VERSION "HNNBNNNYNNNNNNNNNNNNNNNNNNNNNNNNNNNNNNNNNN/4/%%%/4/'%**4NNN///"

NS_ :

BS_:

BU_: AFS Airbag Allrad BAP_Tester BMS_Hybrid Bremse_MK60EC Bremse_MK70MABS Bremse_TRW_EBC450M Bremse_TRW_ESP Daempfer EPB_TRW EPB_TRW_VW411CS FLA Gateway_PQ35 Gateway_Zusatz_EGolf Getriebe_AG6 Getriebe_DQ Getriebe_DQ_Hyb Getriebe_Sele Gurtmikro_PQ35 HCA Ladegeraet_EGolf LEH_Hybrid LH_EPS_APA LH_EPS_ZF_2G LH_EPS_ZF_3G LPG_Interface_Box LWR LWS Magne_Ride Motor_Diesel Motor_EGolf Motor_Hybrid Motor_Otto PDC_PLA Quersperre_VAQ RKA_Plus SAK Waehlhebel Waehlhebel_Sele

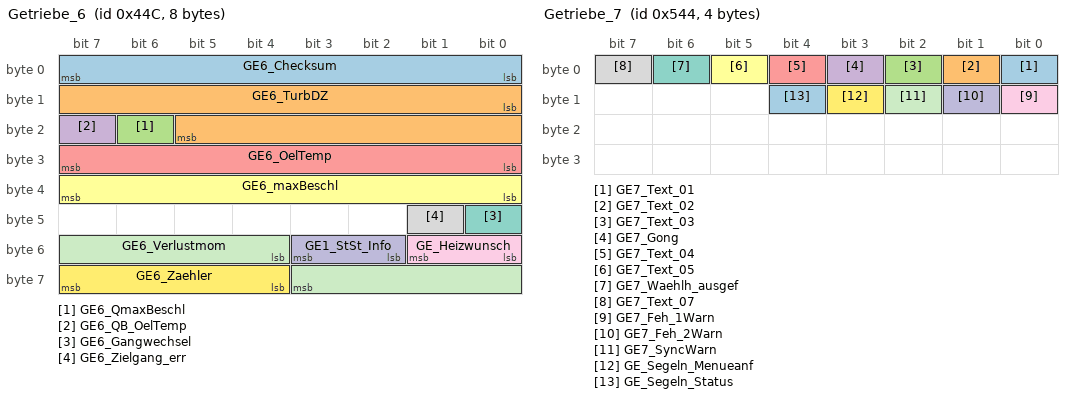
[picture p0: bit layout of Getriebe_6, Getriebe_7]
BO_ 1100 Getriebe_6: 8 Getriebe_AG6
 SG_ GE6_Checksum : 0|8@1+ (1,0) [0|255] ""  Motor_Diesel,Motor_Otto
 SG_ GE6_TurbDZ : 8|14@1+ (1,0) [0|16381] "Unit_MinutInver"  Motor_Diesel,Motor_Otto
 SG_ GE6_QmaxBeschl : 22|1@1+ (1,0) [0|1] "" Vector__XXX
 SG_ GE6_QB_OelTemp : 23|1@1+ (1,0) [0|1] ""  Motor_Diesel,Motor_Otto
 SG_ GE6_OelTemp : 24|8@1+ (1,-55) [-55|199] "Unit_DegreCelsi"  Motor_Diesel,Motor_Otto
 SG_ GE6_maxBeschl : 32|8@1+ (0.024,-2.112) [-2.112|3.984] "Unit_MeterPerSeconSquar" Vector__XXX
 SG_ GE6_Gangwechsel : 40|1@1+ (1,0) [0|1] "" Vector__XXX
 SG_ GE6_Zielgang_err : 41|1@1+ (1,0) [0|1] "" Vector__XXX
 SG_ GE_Heizwunsch : 48|2@1+ (1,0) [0|3] "" Vector__XXX
 SG_ GE1_StSt_Info : 50|2@1+ (1,0) [0|3] "" Vector__XXX
 SG_ GE6_Verlustmom : 52|8@1+ (0.39,0) [0|99.06] "Unit_PerCent" Vector__XXX
 SG_ GE6_Zaehler : 60|4@1+ (1,0) [0|15] ""  Motor_Diesel,Motor_Otto

BO_ 1348 Getriebe_7: 4 Getriebe_DQ
 SG_ GE7_Text_01 : 0|1@1+ (1,0) [0|1] ""  Gateway_PQ35
 SG_ GE7_Text_02 : 1|1@1+ (1,0) [0|1] ""  Gateway_PQ35
 SG_ GE7_Text_03 : 2|1@1+ (1,0) [0|1] ""  Gateway_PQ35
 SG_ GE7_Gong : 3|1@1+ (1,0) [0|1] ""  Gateway_PQ35
 SG_ GE7_Text_04 : 4|1@1+ (1,0) [0|1] ""  Gateway_PQ35
 SG_ GE7_Text_05 : 5|1@1+ (1,0) [0|1] ""  Gateway_PQ35
 SG_ GE7_Waehlh_ausgef : 6|1@1+ (1,0) [0|1] ""  Gateway_PQ35
 SG_ GE7_Text_07 : 7|1@1+ (1,0) [0|1] ""  Gateway_PQ35
 SG_ GE7_Feh_1Warn : 8|1@1+ (1,0) [0|1] ""  Gateway_PQ35
 SG_ GE7_Feh_2Warn : 9|1@1+ (1,0) [0|1] ""  Gateway_PQ35
 SG_ GE7_SyncWarn : 10|1@1+ (1,0) [0|1] ""  Gateway_PQ35
 SG_ GE_Segeln_Menueanf : 11|1@1+ (1,0) [0|1] ""  Gateway_PQ35
 SG_ GE_Segeln_Status : 12|1@1+ (1,0) [0|1] ""  Gateway_PQ35

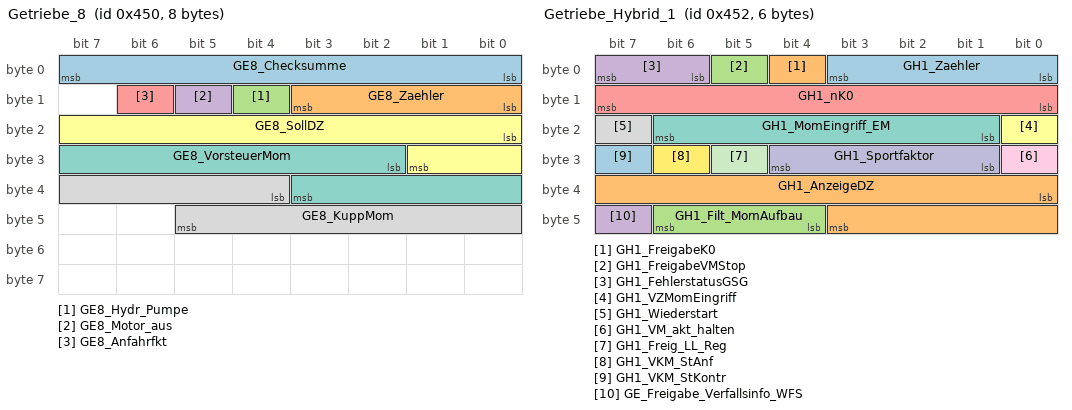
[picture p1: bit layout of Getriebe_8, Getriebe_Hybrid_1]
BO_ 1104 Getriebe_8: 8 Getriebe_Sele
 SG_ GE8_Checksumme : 0|8@1+ (1,0) [0|255] ""  Motor_Otto
 SG_ GE8_Zaehler : 8|4@1+ (1,0) [0|15] ""  Motor_Otto
 SG_ GE8_Hydr_Pumpe : 12|1@1+ (1,0) [0|1] ""  Motor_Otto
 SG_ GE8_Motor_aus : 13|1@1+ (1,0) [0|1] ""  Motor_Otto
 SG_ GE8_Anfahrfkt : 14|1@1+ (1,0) [0|1] ""  Motor_Otto
 SG_ GE8_SollDZ : 16|10@1+ (10,0) [0|10230] "Unit_MinutInver"  Motor_Otto
 SG_ GE8_VorsteuerMom : 26|10@1+ (1,0) [0|1023] "Unit_NewtoMeter"  Motor_Otto
 SG_ GE8_KuppMom : 36|10@1+ (1,0) [0|1023] "Unit_NewtoMeter"  Motor_Otto

BO_ 1106 Getriebe_Hybrid_1: 6 Getriebe_DQ_Hyb
 SG_ GH1_Zaehler : 0|4@1+ (1,0) [0|15] ""  Motor_Hybrid
 SG_ GH1_FreigabeK0 : 4|1@1+ (1,0) [0|1] ""  Motor_Hybrid
 SG_ GH1_FreigabeVMStop : 5|1@1+ (1,0) [0|1] ""  Motor_Hybrid
 SG_ GH1_FehlerstatusGSG : 6|2@1+ (1,0) [0|3] ""  Motor_Hybrid
 SG_ GH1_nK0 : 8|8@1+ (25,0) [0|6350] "Unit_MinutInver"  Motor_Hybrid
 SG_ GH1_VZMomEingriff : 16|1@1+ (1,0) [0|1] ""  LEH_Hybrid
 SG_ GH1_MomEingriff_EM : 17|6@1+ (0.5,0) [0|31.5] "Unit_NewtoMeter"  LEH_Hybrid
 SG_ GH1_Wiederstart : 23|1@1+ (1,0) [0|1] ""  Motor_Hybrid
 SG_ GH1_VM_akt_halten : 24|1@1+ (1,0) [0|1] ""  Motor_Hybrid
 SG_ GH1_Sportfaktor : 25|4@1+ (1,0) [0|15] ""  Motor_Hybrid
 SG_ GH1_Freig_LL_Reg : 29|1@1+ (1,0) [0|1] ""  Motor_Hybrid
 SG_ GH1_VKM_StAnf : 30|1@1+ (1,0) [0|1] ""  Motor_Hybrid
 SG_ GH1_VKM_StKontr : 31|1@1+ (1,0) [0|1] ""  Motor_Hybrid
 SG_ GH1_AnzeigeDZ : 32|12@1+ (3,0) [0|12282] "Unit_MinutInver"  Motor_Hybrid
 SG_ GH1_Filt_MomAufbau : 44|3@1+ (1,0) [0|7] ""  Motor_Hybrid
 SG_ GE_Freigabe_Verfallsinfo_WFS : 47|1@1+ (1,0) [0|1] "" Vector__XXX

BO_ 906 GRA_Neu: 4 Gateway_PQ35
 SG_ GRA_Checksum : 0|8@1+ (1,0) [0|255] ""  Motor_Diesel,Motor_EGolf,Motor_Hybrid,Motor_Otto
 SG_ GRA_Hauptschalt : 8|1@1+ (1,0) [0|1] ""  Motor_Diesel,Motor_EGolf,Motor_Hybrid,Motor_Otto
 SG_ GRA_Abbrechen : 9|1@1+ (1,0) [0|1] ""  Motor_Diesel,Motor_EGolf,Motor_Hybrid,Motor_Otto
 SG_ GRA_Down_kurz : 10|1@1+ (1,0) [0|1] ""  Getriebe_DQ,Getriebe_DQ_Hyb,Motor_Diesel,Motor_EGolf,Motor_Hybrid,Motor_Otto
 SG_ GRA_Up_kurz : 11|1@1+ (1,0) [0|1] ""  Getriebe_DQ,Getriebe_DQ_Hyb,Motor_Diesel,Motor_EGolf,Motor_Hybrid,Motor_Otto
 SG_ GRA_Down_lang : 12|1@1+ (1,0) [0|1] "" Vector__XXX
 SG_ GRA_Up_lang : 13|1@1+ (1,0) [0|1] "" Vector__XXX
 SG_ GRA_Fehler_Bed : 14|1@1+ (1,0) [0|1] ""  Motor_Diesel,Motor_EGolf,Motor_Hybrid,Motor_Otto
 SG_ GRA_Kodierinfo : 15|1@1+ (1,0) [0|1] ""  Motor_Diesel,Motor_EGolf,Motor_Hybrid,Motor_Otto
 SG_ GRA_Neu_Setzen : 16|1@1+ (1,0) [0|1] ""  Getriebe_DQ,Getriebe_DQ_Hyb,Motor_Diesel,Motor_EGolf,Motor_Hybrid,Motor_Otto
 SG_ GRA_Recall : 17|1@1+ (1,0) [0|1] ""  Getriebe_DQ,Getriebe_DQ_Hyb,Motor_Diesel,Motor_EGolf,Motor_Hybrid,Motor_Otto
 SG_ GRA_Sender : 18|2@1+ (1,0) [0|3] ""  Getriebe_DQ,Getriebe_DQ_Hyb,Getriebe_Sele,Motor_Diesel,Motor_EGolf,Motor_Hybrid,Motor_Otto
 SG_ GRA_Neu_Zaehler : 20|4@1+ (1,0) [0|15] ""  Motor_Diesel,Motor_EGolf,Motor_Hybrid,Motor_Otto
 SG_ GRA_Tip_Down : 24|1@1+ (1,0) [0|1] ""  Getriebe_AG6,Getriebe_DQ,Getriebe_DQ_Hyb,Getriebe_Sele
 SG_ GRA_Tip_Up : 25|1@1+ (1,0) [0|1] ""  Getriebe_AG6,Getriebe_DQ,Getriebe_DQ_Hyb,Getriebe_Sele
 SG_ GRA_Zeitluecke : 26|2@1+ (1,0) [0|3] "" Vector__XXX
 SG_ GRA_Sta_Limiter : 28|1@1+ (1,0) [0|1] "" Vector__XXX
 SG_ GRA_Typ_Hauptschalt : 29|1@1+ (1,0) [0|1] ""  Motor_Diesel,Motor_EGolf,Motor_Hybrid,Motor_Otto
 SG_ GRA_Sportschalter : 30|1@1+ (1,0) [0|1] "" Vector__XXX
 SG_ GRA_Fehler_Tip : 31|1@1+ (1,0) [0|1] ""  Getriebe_AG6,Getriebe_DQ,Getriebe_DQ_Hyb

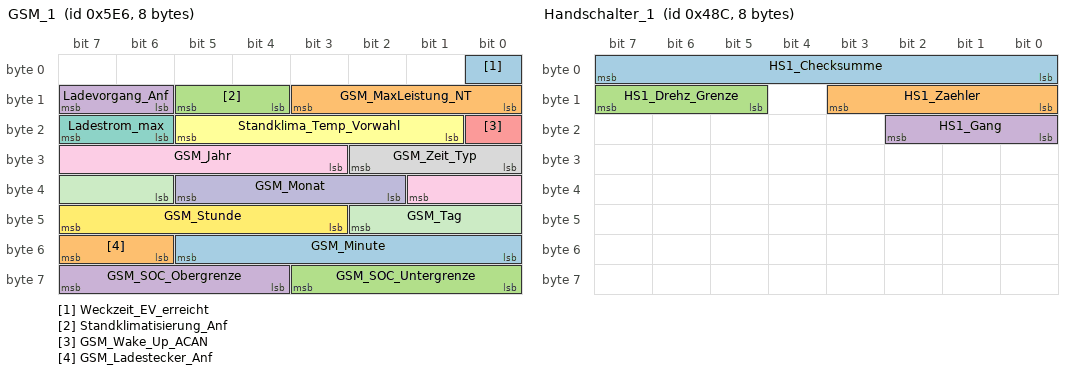
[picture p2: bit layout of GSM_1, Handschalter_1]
BO_ 1510 GSM_1: 8 Gateway_Zusatz_EGolf
 SG_ Weckzeit_EV_erreicht : 0|1@1+ (1,0) [0|1] ""  Ladegeraet_EGolf
 SG_ GSM_MaxLeistung_NT : 8|4@1+ (1,0) [1|15] "Unit_KiloWatt"  Ladegeraet_EGolf
 SG_ Standklimatisierung_Anf : 12|2@1+ (1,0) [0|3] ""  Ladegeraet_EGolf
 SG_ Ladevorgang_Anf : 14|2@1+ (1,0) [0|3] ""  Ladegeraet_EGolf
 SG_ GSM_Wake_Up_ACAN : 16|1@1+ (1,0) [0|1] "" Vector__XXX
 SG_ Standklima_Temp_Vorwahl : 17|5@1+ (1,18) [18|28] "Unit_DegreCelsi" Vector__XXX
 SG_ Ladestrom_max : 22|2@1+ (1,0) [0|3] ""  Ladegeraet_EGolf
 SG_ GSM_Zeit_Typ : 24|3@1+ (1,0) [0|7] ""  Ladegeraet_EGolf
 SG_ GSM_Jahr : 27|7@1+ (1,2000) [2000|2127] "Unit_Year"  Ladegeraet_EGolf
 SG_ GSM_Monat : 34|4@1+ (1,0) [1|12] "Unit_Month"  Ladegeraet_EGolf
 SG_ GSM_Tag : 38|5@1+ (1,0) [0|31] "Unit_Day"  Ladegeraet_EGolf
 SG_ GSM_Stunde : 43|5@1+ (1,0) [0|23] "Unit_Hours"  Ladegeraet_EGolf
 SG_ GSM_Minute : 48|6@1+ (1,0) [0|59] "Unit_Minut"  Ladegeraet_EGolf
 SG_ GSM_Ladestecker_Anf : 54|2@1+ (1,0) [0|3] ""  Ladegeraet_EGolf,Motor_EGolf
 SG_ GSM_SOC_Untergrenze : 56|4@1+ (10,0) [0|100] "Unit_PerCent"  Ladegeraet_EGolf
 SG_ GSM_SOC_Obergrenze : 60|4@1+ (10,0) [0|100] "Unit_PerCent"  Ladegeraet_EGolf

BO_ 1529 Gurtmikro_1: 1 Gurtmikro_PQ35
 SG_ GM_KD_Fehler : 0|1@1+ (1,0) [0|1] ""  Gateway_PQ35

BO_ 1164 Handschalter_1: 8 Motor_Diesel
 SG_ HS1_Checksumme : 0|8@1+ (1,0) [0|255] ""  Gateway_PQ35
 SG_ HS1_Zaehler : 8|4@1+ (1,0) [0|15] ""  Gateway_PQ35
 SG_ HS1_Drehz_Grenze : 13|3@1+ (1,0) [0|7] ""  Gateway_PQ35
 SG_ HS1_Gang : 16|3@1+ (1,0) [0|7] ""  Gateway_PQ35

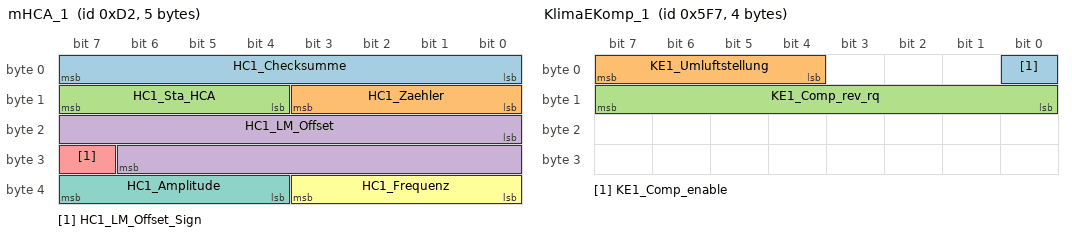
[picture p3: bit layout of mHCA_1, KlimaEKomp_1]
BO_ 210 mHCA_1: 5 Gateway_PQ35
 SG_ HC1_Checksumme : 0|8@1+ (1,0) [0|255] ""  LH_EPS_APA,LH_EPS_ZF_2G,LH_EPS_ZF_3G
 SG_ HC1_Zaehler : 8|4@1+ (1,0) [0|15] ""  LH_EPS_APA,LH_EPS_ZF_2G,LH_EPS_ZF_3G
 SG_ HC1_Sta_HCA : 12|4@1+ (1,0) [0|15] ""  Gateway_PQ35,LH_EPS_APA,LH_EPS_ZF_2G,LH_EPS_ZF_3G
 SG_ HC1_LM_Offset : 16|15@1+ (0.0003052,0) [0|10.0004884] "Unit_NewtoMeter"  Gateway_PQ35,LH_EPS_APA,LH_EPS_ZF_2G,LH_EPS_ZF_3G
 SG_ HC1_LM_Offset_Sign : 31|1@1+ (1,0) [0|1] ""  Gateway_PQ35,LH_EPS_APA,LH_EPS_ZF_2G,LH_EPS_ZF_3G
 SG_ HC1_Frequenz : 32|4@1+ (4,0) [0|60] "Unit_Hertz"  LH_EPS_APA,LH_EPS_ZF_2G,LH_EPS_ZF_3G
 SG_ HC1_Amplitude : 36|4@1+ (0.5,0) [0|7.5] "Unit_NewtoMeter"  LH_EPS_APA,LH_EPS_ZF_2G,LH_EPS_ZF_3G

BO_ 1490 mIdent: 8 Gateway_PQ35
 SG_ IDT_Mux M : 0|2@1+ (1,0) [0|2] ""  Airbag,Bremse_MK60EC,Bremse_MK70MABS,Bremse_TRW_EBC450M,Bremse_TRW_ESP,Daempfer,EPB_TRW,EPB_TRW_VW411CS,LH_EPS_APA,LH_EPS_ZF_2G,LH_EPS_ZF_3G,LWS,Magne_Ride
 SG_ IDT_Geheimnis_1 m0 : 8|8@1+ (1,0) [0|255] "" Vector__XXX
 SG_ IDT_VIN_4 m1 : 8|8@1+ (1,0) [0|255] ""  Airbag,Daempfer,LWS,Magne_Ride
 SG_ IDT_VIN_11 m2 : 8|8@1+ (1,0) [0|255] ""  Airbag,Daempfer,LWS,Magne_Ride
 SG_ IDT_Geheimnis_2 m0 : 16|8@1+ (1,0) [0|255] "" Vector__XXX
 SG_ IDT_VIN_5 m1 : 16|8@1+ (1,0) [0|255] ""  Airbag,Daempfer,LWS,Magne_Ride
 SG_ IDT_VIN_12 m2 : 16|8@1+ (1,0) [0|255] ""  Airbag,Daempfer,LWS,Magne_Ride
 SG_ IDT_Geheimnis_3 m0 : 24|8@1+ (1,0) [0|255] "" Vector__XXX
 SG_ IDT_VIN_6 m1 : 24|8@1+ (1,0) [0|255] ""  Airbag,Daempfer,LWS,Magne_Ride
 SG_ IDT_VIN_13 m2 : 24|8@1+ (1,0) [0|255] ""  Airbag,Bremse_MK60EC,Bremse_TRW_EBC450M,Bremse_TRW_ESP,Daempfer,EPB_TRW,EPB_TRW_VW411CS,LWS,Magne_Ride
 SG_ IDT_Geheimnis_4 m0 : 32|8@1+ (1,0) [0|255] "" Vector__XXX
 SG_ IDT_VIN_7 m1 : 32|8@1+ (1,0) [0|255] ""  Airbag,Bremse_MK60EC,Bremse_TRW_EBC450M,Daempfer,EPB_TRW,EPB_TRW_VW411CS,LWS,Magne_Ride
 SG_ IDT_VIN_14 m2 : 32|8@1+ (1,0) [0|255] ""  Airbag,Bremse_MK60EC,Bremse_MK70MABS,Bremse_TRW_EBC450M,Bremse_TRW_ESP,Daempfer,EPB_TRW,EPB_TRW_VW411CS,LH_EPS_APA,LH_EPS_ZF_2G,LH_EPS_ZF_3G,LWS,Magne_Ride
 SG_ IDT_VIN_1 m0 : 40|8@1+ (1,0) [0|255] ""  Airbag,Daempfer,LWS,Magne_Ride
 SG_ IDT_VIN_8 m1 : 40|8@1+ (1,0) [0|255] ""  Airbag,Bremse_MK60EC,Bremse_TRW_EBC450M,Daempfer,EPB_TRW,EPB_TRW_VW411CS,LWS,Magne_Ride
 SG_ IDT_VIN_15 m2 : 40|8@1+ (1,0) [0|255] ""  Airbag,Bremse_MK60EC,Bremse_MK70MABS,Bremse_TRW_EBC450M,Bremse_TRW_ESP,Daempfer,EPB_TRW,EPB_TRW_VW411CS,LH_EPS_APA,LH_EPS_ZF_2G,LH_EPS_ZF_3G,LWS,Magne_Ride
 SG_ IDT_VIN_2 m0 : 48|8@1+ (1,0) [0|255] ""  Airbag,Daempfer,LWS,Magne_Ride
 SG_ IDT_VIN_9 m1 : 48|8@1+ (1,0) [0|255] ""  Airbag,Daempfer,LWS,Magne_Ride
 SG_ IDT_VIN_16 m2 : 48|8@1+ (1,0) [0|255] ""  Airbag,Bremse_MK60EC,Bremse_MK70MABS,Bremse_TRW_EBC450M,Bremse_TRW_ESP,Daempfer,EPB_TRW,EPB_TRW_VW411CS,LH_EPS_APA,LH_EPS_ZF_2G,LH_EPS_ZF_3G,LWS,Magne_Ride
 SG_ IDT_VIN_3 m0 : 56|8@1+ (1,0) [0|255] ""  Airbag,Daempfer,LWS,Magne_Ride
 SG_ IDT_VIN_10 m1 : 56|8@1+ (1,0) [0|255] ""  Airbag,Daempfer,LWS,Magne_Ride
 SG_ IDT_VIN_17 m2 : 56|8@1+ (1,0) [0|255] ""  Airbag,Bremse_MK60EC,Bremse_MK70MABS,Bremse_TRW_EBC450M,Bremse_TRW_ESP,Daempfer,EPB_TRW,EPB_TRW_VW411CS,LH_EPS_APA,LH_EPS_ZF_2G,LH_EPS_ZF_3G,LWS,Magne_Ride

BO_ 1512 Klima_EV_1: 8 Gateway_Zusatz_EGolf
 SG_ KL_HV_ein : 0|1@1+ (1,0) [0|1] "" Vector__XXX
 SG_ KL_Innengeblaese : 1|1@1+ (1,0) [0|1] "" Vector__XXX
 SG_ KL_PTC_Soll : 2|8@1+ (0.5,0) [0|100] "Unit_PerCent"  BMS_Hybrid,Ladegeraet_EGolf,Motor_EGolf
 SG_ KL_Wake_Up_ACAN : 12|1@1+ (1,0) [0|1] "" Vector__XXX
 SG_ KL_HV_Anf : 13|1@1+ (1,0) [0|1] ""  Motor_EGolf
 SG_ KL_Ventil_Batterie_Anf : 14|1@1+ (1,0) [0|1] ""  Motor_EGolf
 SG_ KL_Ventil_vor_Motor_Anf : 15|1@1+ (1,0) [0|1] ""  Motor_EGolf
 SG_ PTC_Strom : 16|8@1+ (0.1,0) [0|25.4] "Unit_Amper"  Ladegeraet_EGolf,Motor_EGolf
 SG_ EKK_Strom : 24|8@1+ (0.1,0) [0|25.4] "Unit_Amper"  Ladegeraet_EGolf,Motor_EGolf
 SG_ KL_Kompr_Drehzahl_Soll : 32|8@1+ (50,0) [0|8600] "Unit_MinutInver" Vector__XXX
 SG_ EKK_Status : 40|1@1+ (1,0) [0|1] ""  Ladegeraet_EGolf,Motor_EGolf
 SG_ KL_Standklima_Status : 41|3@1+ (1,0) [0|7] ""  Ladegeraet_EGolf
 SG_ PTC_Pumpe_Ist : 44|4@1+ (10,0) [0|100] "Unit_PerCent"  Motor_EGolf
 SG_ PTC_Pumpe_Status : 48|2@1+ (1,0) [0|3] ""  Motor_EGolf
 SG_ KL_Charisma_FahrPr : 50|3@1+ (1,0) [0|7] ""  Ladegeraet_EGolf
 SG_ KL_Charisma_Status : 53|2@1+ (1,0) [0|3] ""  Ladegeraet_EGolf
 SG_ EKK_Status_Vorstrg : 55|1@1+ (1,0) [0|1] ""  Motor_EGolf
 SG_ KL_Standklima_Strg_Kluefter : 56|8@1+ (0.4,0) [0|100] "Unit_PerCent"  Motor_EGolf

BO_ 1527 KlimaEKomp_1: 4 Gateway_PQ35
 SG_ KE1_Comp_enable : 0|1@1+ (1,0) [0|1] "" Vector__XXX
 SG_ KE1_Umluftstellung : 4|4@1+ (10,0) [0|100] "Unit_PerCent"  BMS_Hybrid
 SG_ KE1_Comp_rev_rq : 8|8@1+ (50,0) [0|8600] "Unit_MinutInver" Vector__XXX

BO_ 800 Kombi_1: 8 Gateway_PQ35
 SG_ KO1_SleepInd : 0|1@1+ (1,0) [0|1] "" Vector__XXX
 SG_ KO1_Sta_Tank : 1|1@1+ (1,0) [0|1] ""  Motor_Diesel,Motor_Hybrid,Motor_Otto
 SG_ KO1_Oeldruck : 2|1@1+ (1,0) [0|1] ""  Motor_Diesel,Motor_Otto
 SG_ KO1_Sta_Oeldr : 3|1@1+ (1,0) [0|1] "" Vector__XXX
 SG_ KO1_Kuehlmittel : 4|1@1+ (1,0) [0|1] ""  Motor_Diesel,Motor_Otto
 SG_ KO1_Wakeup_Komfort : 5|1@1+ (1,0) [0|1] "" Vector__XXX
 SG_ KO1_Warn_Tank : 6|1@1+ (1,0) [0|1] ""  Motor_Diesel,Motor_Otto
 SG_ KO1_Vorgluehen : 7|1@1+ (1,0) [0|1] ""  Motor_Diesel
 SG_ KO1_Bremsinfo : 8|1@1+ (1,0) [0|1] "" Vector__XXX
 SG_ KO1_Handbremse : 9|1@1+ (1,0) [0|1] ""  Allrad,Bremse_MK60EC,Bremse_MK70MABS,Getriebe_DQ,Getriebe_DQ_Hyb,Getriebe_Sele,LH_EPS_APA,LH_EPS_ZF_2G,LH_EPS_ZF_3G,Motor_Diesel,Motor_EGolf,Motor_Hybrid,Motor_Otto,RKA_Plus
 SG_ KO1_La_Ladekon : 10|1@1+ (1,0) [0|1] "" Vector__XXX
 SG_ KO1_Stellglieder : 11|1@1+ (1,0) [0|1] ""  Airbag,LH_EPS_ZF_2G,LH_EPS_ZF_3G,Motor_Diesel
 SG_ KO1_Zeitluecke : 12|3@1+ (1,0) [0|7] "" Vector__XXX
 SG_ KO1_Tankstop : 15|1@1+ (1,0) [0|1] "" Vector__XXX
 SG_ KO1_Tankinhalt : 16|7@1+ (1,0) [0|126] "Unit_Liter"  Motor_Diesel,Motor_Hybrid,Motor_Otto
 SG_ KO1_OBD_Tank : 23|1@1+ (1,0) [0|1] ""  Motor_Diesel,Motor_Hybrid,Motor_Otto
 SG_ KO1_Quelle_kmh : 24|1@1+ (1,0) [0|1] ""  Motor_Otto
 SG_ KO1_kmh : 25|15@1+ (0.01,0) [0|326] "Unit_KiloMeterPerHour"  LH_EPS_ZF_2G,LH_EPS_ZF_3G,LWR
 SG_ KO1_Zaehler : 40|4@1+ (1,0) [0|15] ""  HCA
 SG_ KO1_ACC_Inkons : 44|1@1+ (1,0) [0|1] "" Vector__XXX
 SG_ KO1_ACC_AnzFhl : 45|1@1+ (1,0) [0|1] "" Vector__XXX
 SG_ KO1_angez_kmh : 46|10@1+ (0.32,0) [0|325.76] "Unit_KiloMeterPerHour"  Getriebe_DQ,Getriebe_DQ_Hyb,HCA,Motor_Diesel,Motor_Otto,RKA_Plus
 SG_ KO1_kmh_mph : 56|1@1+ (1,0) [0|1] ""  Getriebe_DQ,Getriebe_DQ_Hyb,Motor_Diesel,Motor_Otto
 SG_ KO1_ABS_Lampe : 57|1@1+ (1,0) [0|1] "" Vector__XXX
 SG_ KO1_ASRESP_Lampe : 58|1@1+ (1,0) [0|1] "" Vector__XXX
 SG_ KO1_Brems_Lampe : 59|1@1+ (1,0) [0|1] "" Vector__XXX
 SG_ KO1_Airbag_Lampe : 60|1@1+ (1,0) [0|1] ""  Airbag
 SG_ KO1_Lenkh_Lampe : 61|1@1+ (1,0) [0|1] ""  LH_EPS_APA,LH_EPS_ZF_2G,LH_EPS_ZF_3G
 SG_ KO1_LDW_AnzFeh : 62|1@1+ (1,0) [0|1] ""  HCA
 SG_ KO1_SILA_gueltig : 63|1@1+ (1,0) [0|1] ""  Airbag,LH_EPS_APA,LH_EPS_ZF_2G,LH_EPS_ZF_3G

BO_ 1056 Kombi_2: 8 Gateway_PQ35
 SG_ KO2_Sta_Auss_T : 0|1@1+ (1,0) [0|1] ""  Bremse_MK60EC,Bremse_MK70MABS,EPB_TRW_VW411CS,HCA,Magne_Ride,Motor_Diesel,Motor_EGolf,Motor_Hybrid,Motor_Otto,RKA_Plus
 SG_ KO2_Verb_TOG : 1|1@1+ (1,0) [0|1] ""  Motor_Diesel,Motor_Hybrid,Motor_Otto
 SG_ KO2_Oelwarn : 2|1@1+ (1,0) [0|1] "" Vector__XXX
 SG_ KO2_GRA_High : 3|1@1+ (1,0) [0|1] ""  Motor_Diesel,Motor_Otto
 SG_ KO2_Temp_Einheit : 4|1@1+ (1,0) [0|1] "" Vector__XXX
 SG_ KO2_Wischwasser : 5|1@1+ (1,0) [0|1] "" Vector__XXX
 SG_ KO2_PLA_Displaystatus : 6|1@1+ (1,0) [0|1] ""  PDC_PLA
 SG_ KO2_Fehlereintr : 7|1@1+ (1,0) [0|1] "" Vector__XXX
 SG_ KO2_gef_Auss_T : 8|8@1+ (0.5,-50) [-50|77] "Unit_DegreCelsi"  AFS,Bremse_MK60EC,Bremse_TRW_EBC450M,Bremse_TRW_ESP,EPB_TRW_VW411CS,Getriebe_DQ,Getriebe_DQ_Hyb,Getriebe_Sele,HCA,LWR,Magne_Ride,Motor_EGolf,Motor_Hybrid,Motor_Otto,PDC_PLA,RKA_Plus
 SG_ KO2_Aussen_T : 16|8@1+ (0.5,-50) [-50|77] "Unit_DegreCelsi"  Bremse_MK60EC,Bremse_MK70MABS,Magne_Ride,Motor_Diesel,Motor_Otto,PDC_PLA
 SG_ KB2_EasyEntry : 34|1@1+ (1,0) [0|1] "" Vector__XXX
 SG_ KBI_rotes_P_verbaut : 35|1@1+ (1,0) [0|1] ""  Bremse_TRW_EBC450M,EPB_TRW_VW411CS
 SG_ KO_Segeln_Menuestatus : 36|1@1+ (1,0) [0|1] ""  Getriebe_DQ
 SG_ KO_Segeln_Zustandswechsel : 37|1@1+ (1,0) [0|1] ""  Getriebe_DQ
 SG_ KB2_Auto_eKiSi : 38|1@1+ (1,0) [0|1] "" Vector__XXX
 SG_ KB2_Req_IstZu_Solldruecke : 39|1@1+ (1,0) [0|1] ""  Bremse_MK60EC,Bremse_TRW_EBC450M,RKA_Plus
 SG_ KO2_Bel_Displ : 40|7@1+ (1,0) [0|100] "Unit_PerCent"  Airbag,Daempfer,Magne_Ride,PDC_PLA,Waehlhebel_Sele
 SG_ KO2_Sta_Displ : 47|1@1+ (1,0) [0|1] ""  Airbag,Daempfer,Magne_Ride,PDC_PLA,Waehlhebel_Sele
 SG_ KO2_Bel_Schalt : 48|7@1+ (1,0) [0|100] "Unit_PerCent" Vector__XXX
 SG_ KO2_Sta_Schalt : 55|1@1+ (1,0) [0|1] "" Vector__XXX
 SG_ KO2_MFA_v_Einheit : 56|1@1+ (1,0) [0|1] ""  Motor_Diesel,Motor_EGolf,Motor_Hybrid,Motor_Otto
 SG_ KO2_Passiv_Autolock : 57|1@1+ (1,0) [0|1] "" Vector__XXX
 SG_ KO2_WFS_Schl_Ort : 58|1@1+ (1,0) [0|1] "" Vector__XXX
 SG_ KB2_MFA_Strecke_Einheit : 59|1@1+ (1,0) [0|1] "" Vector__XXX
 SG_ KO2_OBD_Nib_Temp : 60|4@1+ (1,0) [0|15] ""  Motor_Diesel,Motor_Hybrid,Motor_Otto

BO_ 1312 Kombi_3: 8 Gateway_PQ35
 SG_ KO3_Sprache m0 : 0|8@1+ (1,0) [0|255] ""  Bremse_TRW_EBC450M,Bremse_TRW_ESP
 SG_ KO3_Derivat m1 : 0|4@1+ (1,0) [0|15] ""  Allrad,Bremse_MK60EC
 SG_ KO3_Radumfang m2 : 0|12@1+ (1,0) [0|4095] ""  Allrad,Bremse_MK60EC,Bremse_MK70MABS,Bremse_TRW_EBC450M,Bremse_TRW_ESP,Getriebe_DQ,Getriebe_DQ_Hyb,PDC_PLA
 SG_ KO3_Verbau_Mot m3 : 0|1@1+ (1,0) [0|1] "" Vector__XXX
 SG_ KO3_Verbau_Get m3 : 1|1@1+ (1,0) [0|1] "" Vector__XXX
 SG_ KO3_Verbau_Br m3 : 2|1@1+ (1,0) [0|1] ""  Bremse_MK60EC
 SG_ KO3_Verbau_Kl m3 : 3|1@1+ (1,0) [0|1] "" Vector__XXX
 SG_ KO3_Generation m1 : 4|4@1+ (1,0) [0|15] ""  Allrad,Bremse_MK60EC
 SG_ KO3_Verbau_Air m3 : 4|1@1+ (1,0) [0|1] ""  Airbag
 SG_ KO3_Verbau_ADR m3 : 5|1@1+ (1,0) [0|1] "" Vector__XXX
 SG_ KO3_Verbau_BN m3 : 6|1@1+ (1,0) [0|1] "" Vector__XXX
 SG_ KO3_Verbau_Syn m3 : 7|1@1+ (1,0) [0|1] "" Vector__XXX
 SG_ KO3_Land m0 : 8|6@1+ (1,0) [0|63] "" Vector__XXX
 SG_ KO3_Baureihe m1 : 8|3@1+ (1,0) [0|7] ""  Allrad,Bremse_MK60EC
 SG_ KO3_Verbau_LWS m3 : 8|1@1+ (1,0) [0|1] "" Vector__XXX
 SG_ KO3_Verbau_DP m3 : 9|1@1+ (1,0) [0|1] "" Vector__XXX
 SG_ KO3_Verbau_LH m3 : 10|1@1+ (1,0) [0|1] "" Vector__XXX
 SG_ KO3_Marke m1 : 11|3@1+ (1,0) [0|7] ""  Allrad,Bremse_MK60EC
 SG_ KO3_Verbau_Niveau m3 : 11|1@1+ (1,0) [0|1] "" Vector__XXX
 SG_ KO3_Mp_Code M : 14|2@1+ (1,0) [0|3] ""  Airbag,Allrad,Bremse_MK60EC,Bremse_MK70MABS,Bremse_TRW_EBC450M,Bremse_TRW_ESP,Getriebe_DQ,Getriebe_DQ_Hyb,PDC_PLA
 SG_ KO3_Schluessel : 16|4@1+ (1,0) [0|15] ""  Ladegeraet_EGolf
 SG_ KO3_Um_AFS2 : 20|1@1+ (1,0) [0|1] ""  AFS
 SG_ KO3_Um_Tourist : 21|1@1+ (1,0) [0|1] ""  AFS,LWR
 SG_ KO3_Um_AutoHold : 22|1@1+ (1,0) [0|1] ""  Bremse_TRW_EBC450M,Bremse_TRW_ESP
 SG_ KO3_SWA_AnzFeh : 23|1@1+ (1,0) [0|1] "" Vector__XXX
 SG_ KO3_Standzeit : 24|15@1+ (4,0) [0|131068] "Unit_Secon"  AFS,Allrad,Bremse_MK60EC,Bremse_TRW_EBC450M,Bremse_TRW_ESP,Getriebe_DQ,Getriebe_DQ_Hyb,Magne_Ride,Motor_Diesel,Motor_Hybrid,Motor_Otto
 SG_ KO3_Sta_Standz : 39|1@1+ (1,0) [0|1] ""  AFS,Bremse_MK60EC,Getriebe_DQ,Getriebe_DQ_Hyb,Magne_Ride,Motor_Diesel,Motor_Hybrid,Motor_Otto
 SG_ KO3_Kilometer : 40|20@1+ (1,0) [0|1048575] "Unit_KiloMeter"  Bremse_MK60EC,Bremse_MK70MABS,Getriebe_AG6,LH_EPS_ZF_2G,LH_EPS_ZF_3G

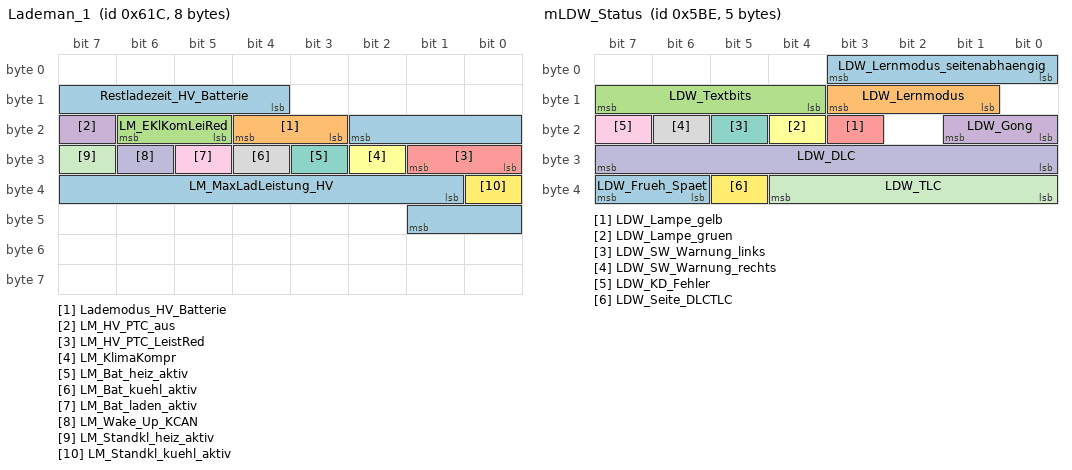
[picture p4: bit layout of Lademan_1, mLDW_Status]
BO_ 1564 Lademan_1: 8 Ladegeraet_EGolf
 SG_ Restladezeit_HV_Batterie : 12|7@1+ (5,0) [0|630] "Unit_Minut"  Gateway_Zusatz_EGolf
 SG_ Lademodus_HV_Batterie : 19|2@1+ (1,0) [0|3] ""  Gateway_Zusatz_EGolf
 SG_ LM_EKlKomLeiRed : 21|2@1+ (1,0) [0|3] ""  Gateway_Zusatz_EGolf
 SG_ LM_HV_PTC_aus : 23|1@1+ (1,0) [0|1] ""  Gateway_Zusatz_EGolf
 SG_ LM_HV_PTC_LeistRed : 24|2@1+ (1,0) [0|3] ""  Gateway_Zusatz_EGolf
 SG_ LM_KlimaKompr : 26|1@1+ (1,0) [0|1] ""  Gateway_Zusatz_EGolf
 SG_ LM_Bat_heiz_aktiv : 27|1@1+ (1,0) [0|1] ""  Gateway_Zusatz_EGolf
 SG_ LM_Bat_kuehl_aktiv : 28|1@1+ (1,0) [0|1] ""  Gateway_Zusatz_EGolf
 SG_ LM_Bat_laden_aktiv : 29|1@1+ (1,0) [0|1] ""  Gateway_Zusatz_EGolf
 SG_ LM_Wake_Up_KCAN : 30|1@1+ (1,0) [0|1] ""  Gateway_Zusatz_EGolf
 SG_ LM_Standkl_heiz_aktiv : 31|1@1+ (1,0) [0|1] ""  Gateway_Zusatz_EGolf
 SG_ LM_Standkl_kuehl_aktiv : 32|1@1+ (1,0) [0|1] ""  Gateway_Zusatz_EGolf
 SG_ LM_MaxLadLeistung_HV : 33|9@1+ (100,0) [0|51000] "Unit_Watt"  Gateway_Zusatz_EGolf

BO_ 1470 mLDW_Status: 5 HCA
 SG_ LDW_Lernmodus_seitenabhaengig : 0|4@1+ (1,0) [0|15] ""  Gateway_PQ35
 SG_ LDW_Lernmodus : 9|3@1+ (1,0) [0|7] ""  Gateway_PQ35
 SG_ LDW_Textbits : 12|4@1+ (1,0) [0|15] ""  Gateway_PQ35
 SG_ LDW_Gong : 16|2@1+ (1,0) [0|3] ""  Gateway_PQ35
 SG_ LDW_Lampe_gelb : 19|1@1+ (1,0) [0|1] ""  Gateway_PQ35
 SG_ LDW_Lampe_gruen : 20|1@1+ (1,0) [0|1] ""  Gateway_PQ35
 SG_ LDW_SW_Warnung_links : 21|1@1+ (1,0) [0|1] ""  Gateway_PQ35
 SG_ LDW_SW_Warnung_rechts : 22|1@1+ (1,0) [0|1] ""  Gateway_PQ35
 SG_ LDW_KD_Fehler : 23|1@1+ (1,0) [0|1] ""  Gateway_PQ35
 SG_ LDW_DLC : 24|8@1+ (0.01,-1.25) [-1.25|1.25] "Unit_Meter"  Gateway_PQ35
 SG_ LDW_TLC : 32|5@1+ (0.1,0) [0|3] "Unit_Secon"  Gateway_PQ35
 SG_ LDW_Seite_DLCTLC : 37|1@1+ (1,0) [0|1] ""  Gateway_PQ35
 SG_ LDW_Frueh_Spaet : 38|2@1+ (1,0) [0|3] ""  Gateway_PQ35

BO_ 976 Lenkhilfe_1: 6 LH_EPS_APA
 SG_ LH1_Lastinfo : 0|7@1+ (1,0) [0|127] "Unit_Amper"  Gateway_PQ35
 SG_ LH1_Fehler_LI : 7|1@1+ (1,0) [0|1] ""  Gateway_PQ35
 SG_ LH1_Sicherheitslamp : 8|1@1+ (1,0) [0|1] ""  Gateway_PQ35
 SG_ LH1_Fehlerlampe : 9|1@1+ (1,0) [0|1] ""  Gateway_PQ35
 SG_ LH1_Textbits : 10|3@1+ (1,0) [0|7] ""  Gateway_PQ35
 SG_ LH1_Akustiksign : 13|1@1+ (1,0) [0|1] ""  Gateway_PQ35
 SG_ LH1_SleepInd : 14|1@1+ (1,0) [0|1] ""  Gateway_PQ35
 SG_ LH1_Fehlereintr : 15|1@1+ (1,0) [0|1] ""  Gateway_PQ35
 SG_ LH1_EPS_Diagmode : 16|1@1+ (1,0) [0|1] ""  Gateway_PQ35
 SG_ LH1_gue_ECU_Temp : 19|1@1+ (1,0) [0|1] ""  Gateway_PQ35
 SG_ LH1_Kuehlung : 20|1@1+ (1,0) [0|1] ""  Gateway_PQ35
 SG_ LH1_Mode_Hybrid : 21|1@1+ (1,0) [0|1] ""  Gateway_PQ35
 SG_ LH1_NL_Untersp : 24|1@1+ (1,0) [0|1] ""  Gateway_PQ35
 SG_ LH1_NL_Uebersp : 25|1@1+ (1,0) [0|1] ""  Gateway_PQ35
 SG_ LH1_NL_Uebertemp : 26|1@1+ (1,0) [0|1] ""  Gateway_PQ35
 SG_ LH1_NL_Sensor : 27|1@1+ (1,0) [0|1] ""  Gateway_PQ35
 SG_ LH1_NL_CAN_SS : 28|1@1+ (1,0) [0|1] ""  Gateway_PQ35
 SG_ LH1_NL_ECU : 29|1@1+ (1,0) [0|1] ""  Gateway_PQ35
 SG_ LH1_NL_Motor : 30|1@1+ (1,0) [0|1] ""  Gateway_PQ35
 SG_ LH1_NL_LeistDichte : 31|1@1+ (1,0) [0|1] ""  Gateway_PQ35
 SG_ LH1_ULeistung : 32|8@1+ (0.5,0) [0|100] "Unit_PerCent"  Gateway_PQ35
 SG_ LH1_ECU_Temp : 40|8@1+ (1,-70) [-70|185] "Unit_DegreCelsi"  Gateway_PQ35

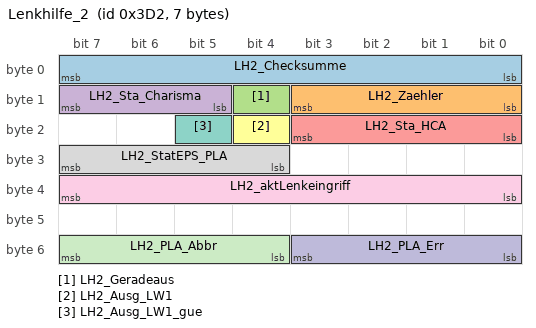
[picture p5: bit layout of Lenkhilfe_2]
BO_ 978 Lenkhilfe_2: 7 LH_EPS_APA
 SG_ LH2_Checksumme : 0|8@1+ (1,0) [0|255] ""  Bremse_MK60EC,Bremse_TRW_EBC450M,Bremse_TRW_ESP,Gateway_PQ35,HCA,PDC_PLA
 SG_ LH2_Zaehler : 8|4@1+ (1,0) [0|15] ""  Bremse_MK60EC,Bremse_TRW_EBC450M,Bremse_TRW_ESP,Gateway_PQ35,HCA,PDC_PLA
 SG_ LH2_Geradeaus : 12|1@1+ (1,0) [0|1] ""  Gateway_PQ35,LWS,Magne_Ride
 SG_ LH2_Sta_Charisma : 13|3@1+ (1,0) [0|7] ""  Gateway_PQ35
 SG_ LH2_Sta_HCA : 16|4@1+ (1,0) [0|15] ""  Gateway_PQ35,HCA
 SG_ LH2_Ausg_LW1 : 20|1@1+ (1,0) [0|1] ""  Gateway_PQ35
 SG_ LH2_Ausg_LW1_gue : 21|1@1+ (1,0) [0|1] ""  Gateway_PQ35
 SG_ LH2_StatEPS_PLA : 28|4@1+ (1,0) [0|15] ""  Bremse_MK60EC,Bremse_TRW_EBC450M,Bremse_TRW_ESP,Gateway_PQ35,PDC_PLA
 SG_ LH2_aktLenkeingriff : 32|8@1+ (1,0) [0|255] ""  Gateway_PQ35,PDC_PLA
 SG_ LH2_PLA_Err : 48|4@1+ (1,0) [0|15] ""  Gateway_PQ35,PDC_PLA
 SG_ LH2_PLA_Abbr : 52|4@1+ (1,0) [0|15] ""  Gateway_PQ35,PDC_PLA

BO_TX_BU_ 1348 : Getriebe_DQ,Getriebe_Sele,Motor_EGolf;
BO_TX_BU_ 1164 : Motor_Diesel,Motor_Otto;
BO_TX_BU_ 210 : Gateway_PQ35,HCA;
BO_TX_BU_ 976 : LH_EPS_APA,LH_EPS_ZF_2G,LH_EPS_ZF_3G;
BO_TX_BU_ 978 : LH_EPS_APA,LH_EPS_ZF_2G,LH_EPS_ZF_3G;
CM_ SG_ 1100 GE6_Checksum "Prüfsumme mit Endwert 0x0, Definition im CAN Lastenheft (HS-CAN V4.2a, LS-CAN V1.42)";
CM_ SG_ 1100 GE6_TurbDZ "Zur Verbesserung des Lastschlagverhaltens beim Schaltvorgang
Turbinendrehzahl";
CM_ SG_ 1100 GE6_QmaxBeschl "Definition im CAN Lastenheft
Qualifizierungsbit max. Beschleunigung";
CM_ SG_ 1100 GE6_QB_OelTemp "Definition im CAN Lastenheft
Qualifizierungsbit Getriebeöltemperatur";
CM_ SG_ 1100 GE6_OelTemp "Getriebeöltemperatur";
CM_ SG_ 1100 GE6_maxBeschl "max. Beschleunigung Getriebe für Audi ACC-Projekte";
CM_ SG_ 1100 GE6_Gangwechsel "Das Bit wird gesetzt, wenn das Bit 'Schaltung aktiv' gesetzt ist und der Betrag der Differenz zwischen dem Produkt aus Getriebeausgangsdrehzahl und Übersetzung des Istgangs und der Getriebeeingangsdrehzahl einen getriebeseitig applizierbaren Schwellwert ü";
CM_ SG_ 1100 GE6_Zielgang_err "Das Bit wird gesetzt, wenn der Betrag der Differenz zwischen Getriebeeingangsdrehzahl und Produkt aus Getriebeausgangsdrehzahl und Übersetzung des Zielgangs einen getriebeseitig applizierbaren Schwellwert unterschreitet. Das Bit wird zurückgesetzt, wenn d";
CM_ SG_ 1100 GE_Heizwunsch "(nur AU716)";
CM_ SG_ 1100 GE1_StSt_Info "Stopp-Freigabe/Start-Anforderung für den Start-Stopp-Koordinator
(Verriegelt über Systemstatus Start/Stopp wegen ESP8 bei AUDI und ggf. alter Motoren: Getriebe darf nur einen Wert ungleich 0 senden, wenn mMotor_10 empfangen wurde und der 'Systemstatus St";
CM_ SG_ 1100 GE6_Verlustmom "gesamtes Verlustmoment von Zentralgetriebe incl. Vorderachsdifferential (und Zentraldifferential / Verteilergetriebe bei quattro) Nutzung im ACC, GRA und Triebstrangkoordinator im Motor (nur AU716 und D3, nicht für andere Projekte verwenden!)
Getriebever";
CM_ SG_ 1100 GE6_Zaehler "Freilaufender Botschaftszähler
Zähler (Getriebe_6)";
CM_ SG_ 1348 GE7_Text_01 "Bit schaltet Textmeldung im Kombi als Fahrerhinweis:
Wenn die Kupplungsschutzfunktion des Selespeed-Getriebes aktiv ist, wird über diesen Text der Fahrer informiert.";
CM_ SG_ 1348 GE7_Text_02 "Bit schaltet Textmeldung im Kombi als Fahrerhinweis:
'Handbremse nicht betätigt'
Wenn sich das Getriebe nach KL15-Aus nicht im wegrollsicheren Zustand befindet, wird der Fahrer aufgefordert die Handbremse zu ziehen";
CM_ SG_ 1348 GE7_Text_03 "Bit schaltet Textmeldung im Kombi als Fahrerhinweis:
'Gang nicht eingelegt'
Wenn sich das Getriebe nach KL15-Aus nicht im wegrollsicheren Zustand befindet, wird der Fahrer aufgefordert durch Tippen des Wählhebels einen Gang einzulegen";
CM_ SG_ 1348 GE7_Gong "Selespeed-Getriebe kann den Fahrer in bestimmten Situationen durch einen Gong zusätzlich warnen";
CM_ SG_ 1348 GE7_Text_04 "Bit schaltet Textmeldung im Kombi als Fahrerhinweis:
'Zum Starten des Motors Bremse betätigen'
Das Bit wird gesetzt, wenn der Fahrer den Motor zu starten versucht ohne die Bremse zu betätigen, wird vom Getriebe über eine diskrete Leitung der Motorstart ";
CM_ SG_ 1348 GE7_Text_05 "Bit schaltet Textmeldung im Kombi als Fahrerhinweis:
'Zum Einlegen einer Fahrstufe im Stand Fussbremse betätigen'";
CM_ SG_ 1348 GE7_Waehlh_ausgef "Ist der Wählhebel nicht mehr in der Lage eine gültige Position an das Getriebesteuergerät zu ermitteln, so wird dieses Bit gesetzt und im Kombiinstrument erscheint die Priorität 2 Warnmeldung 'Wählhebel defekt, kein R-Gang'.";
CM_ SG_ 1348 GE7_Text_07 "Bit schaltet Prio 2 Warnung im Display des Kombis:
'Rückwärtsgang nicht schaltbar'";
CM_ SG_ 1348 GE7_Feh_1Warn "Text Prio2-Meldung 'Getriebefehler: Weiterfahrt möglich' + gelbes Getriebefehlersymbol";
CM_ SG_ 1348 GE7_Feh_2Warn "Text Prio2-Meldung 'Getriebefehler: Weiterfahrt nur eingeschränkt möglich' + gelbes Getriebefehlersymbol";
CM_ SG_ 1348 GE7_SyncWarn "tbd
Synchronisation Meldungen bei Kl.-15 aus";
CM_ SG_ 1348 GE_Segeln_Menueanf "Aktivierung/Deaktivierung Kombi-Menue Segeln Personalisierung";
CM_ SG_ 1348 GE_Segeln_Status "Bestätigung Personalisierung Segeln";
CM_ SG_ 1104 GE8_Checksumme "Prüfsumme mit Endwert 0x0, Definition im CAN Lastenheft (HS-CAN V4.2a, LS-CAN V1.42)";
CM_ SG_ 1104 GE8_Zaehler "Freilaufender Botschaftszähler";
CM_ SG_ 1104 GE8_Hydr_Pumpe "Momentenvorsteuerung der Leerlaufregelung muss erhöhtes Verlustmoment aussteuern
Hydraulikpumpe angesteuert";
CM_ SG_ 1104 GE8_Motor_aus "Motor soll beim Umschalten des Bits ausgeschaltet werden (Getriebeschutz)";
CM_ SG_ 1104 GE8_Anfahrfkt "Zwischen Motor und Getriebe gibt es für die Phase des Anfahrens eine besondere Funktion, bei der das Getriebe dem Motor eine Solldrehzahl und ein dazu passendes Vorsteuermoment vorgibt. Das Bit 'Anfahrfunktion aktiv' aktiviert die Funktion im Motor.";
CM_ SG_ 1104 GE8_SollDZ "Zwischen Motor und Getriebe gibt es für die Phase des Anfahrens eine besondere Funktion, bei der das Getriebe dem Motor eine Solldrehzahl (Solldrehzahl für Anfahrfunktion) und ein dazu passendes Vorsteuermoment vorgibt.";
CM_ SG_ 1104 GE8_VorsteuerMom "Zwischen Motor und Getriebe gibt es für die Phase des Anfahrens eine besondere Funktion, bei der das Getriebe dem Motor eine Solldrehzahl (Solldrehzahl für Anfahrfunktion) und ein dazu passendes Vorsteuermoment (Vorsteuermoment für Anfahrfunktion) vorgibt";
CM_ SG_ 1104 GE8_KuppMom "Zwischen Motor und Getriebe gibt es für die Phase des Anfahrens eine besondere Funktion, bei der das Getriebe dem Motor eine Solldrehzahl (Solldrehzahl für Anfahrfunktion) und ein dazu passendes Vorsteuermoment vorgibt. Im Fall, dass der Fahrer bei aktive";
CM_ SG_ 1106 GH1_Zaehler "Freilaufender Botschaftszähler";
CM_ SG_ 1106 GH1_FreigabeK0 "Übergang von 0 nach 1 (bzw. 1 nach 0) ist Teil des Wiederstart- (Stop-) Handshakes";
CM_ SG_ 1106 GH1_FreigabeVMStop "Signalisiert Bereitschaft GSG, dass VM gestoppt werden darf (Soft Stop) oder dass EM gestoppt werden darf (Übergang EM-Fahren => EM-Fahrbereitschaft)";
CM_ SG_ 1106 GH1_FehlerstatusGSG "Hybrid-spezifische Fehlerstati
PQ35: Fehlerstatus 1 signalisiert, dass der Druck zum Öffnen der K0 nicht ausreicht (nach Kl15 ein)
PL71: Fehlerstatus 1 signalisiert eine unzureichende Druckversorgung durch die EOP.
Fehlerstatus 2: Verhinderung ungewoll";
CM_ SG_ 1106 GH1_nK0 "Nur PQ35 Hybrid:
GSG teilt MSG mit, auf welcher DZ die EM nach schnellem Schließen der K0 und nach DZAngleichung durch das GSG landen wird.
Wenn Bit7 Byte3 nicht aktiv: EM-Drehzahl wird gespiegelt
Wenn Bit7 Byte3 aktiv: DZ, auf der Motor nach Schließen";
CM_ SG_ 1106 GH1_VZMomEingriff "PQ35 Hybrid: Vorzeichen für Getriebeeingriff auf EM (Byte 3, Bit 6..1)";
CM_ SG_ 1106 GH1_MomEingriff_EM "Nur PQ35 Hybrid: Direkter Eingriff des GSG auf EM.
Ist der Betrag des Absolutwertes des Eingriffsmomentes in Nm. Verwendet zur Dämpfung des Triebstranges nach Impulsstart, wenn VM-Momente noch ungenau sind.
E-Gas-Sicherheit: begrenzt auf 30Nm, zusätzlic";
CM_ SG_ 1106 GH1_Wiederstart "Getriebe zeigt an, ob Wiederstart aktiv ist";
CM_ SG_ 1106 GH1_VM_akt_halten "Im elektrischen Fahren/Tip: Übergang von 0 auf 1 zeigt VM-Startanforderung des GSG an.
Ansonsten: Empfehlung GSG an MSG, dass VM aktiv gehalten werden soll. Verwendbar zB bei den Funktionen 'fast off (Gang halten)' oder bei 'Rückschaltung bei Bremsen'";
CM_ SG_ 1106 GH1_Sportfaktor "Sportlichkeitsfaktor Getriebe, zur Verwendung in der Hybrid-Fahrstrategie
0 = nicht sportlich
1..15 = sportlich";
CM_ SG_ 1106 GH1_Freig_LL_Reg "GSG gibt hier die Aktivierung einer DZ-Regelung von VM und/oder EM frei.
(Verhinderung Selbstbeschleuniger)";
CM_ SG_ 1106 GH1_VKM_StAnf "Auslösen des VM-Wiederstart im elektromot. Betrieb
Nur zur abgestimmten Verwendung zwischen Hybridcontroller (MSG) und Getriebe (GSG)";
CM_ SG_ 1106 GH1_VKM_StKontr "Freigabe der Wiederstartkontrolle
Nur zur abgestimmten Verwendung zwischen Hybridcontroller (MSG) und Getriebe (GSG)";
CM_ SG_ 1106 GH1_AnzeigeDZ "Anzeigedrehzahl in Hybridprojekten vom Getriebe zum Motor";
CM_ SG_ 1106 GH1_Filt_MomAufbau "Faktor, der im MSG zur Berechnung der Filterkonstanten für den Fahrerwunschmomentenaufbau im Impulsstart verwendet wird.";
CM_ SG_ 1106 GE_Freigabe_Verfallsinfo_WFS "WFS";
CM_ SG_ 906 GRA_Checksum "Prüfsumme mit Endwert 0x0, Definition im CAN Lastenheft (HS-CAN V4.2a, LS-CAN V1.42)";
CM_ SG_ 906 GRA_Hauptschalt "1 = GRA-Hauptschaslter eingeschaltet, gerastetes Aus/Ein, 1 Tastsignal ein
 Bei Sender Codierung '01 u. 10' sind Tipsignale entprellt'
4 Positionen LSM (Sender-Codierung 11) uebertraegt Tastsignal (Byte 4 Bit 5 gesetzt)";
CM_ SG_ 906 GRA_Abbrechen "1 = GRA/ADR-Tipschalter betaetigt (Aus mit Speichern), Bei Sender Codierung '01 u. 10' sind Tipsignale entprellt'
GRA_ADR_Tippschalter _aus betaetigt, Abbrechen";
CM_ SG_ 906 GRA_Down_kurz "1 = Tippschalter betaetigt, Bei Sendercodierung '00' und '11' wird hier 'Setzen/Verzoegern' uebertragen
Bei Sender Codierung '01 u. 10' sind Tipsignale entprellt.
GRA_ADR_Tipschalter_Verzoegern betaetigt, KurzTip-down";
CM_ SG_ 906 GRA_Up_kurz "1 = Tippschalter betaetigt, Bei Sendercodierung '00' und '11' wird hier 'Wiederaufnahme/Beschleunigen' uebertragen
Bei Sender Codierung '01 u. 10' sind Tipsignale entprellt.
GRA_ADR_Tipschalter_Beschleunigen betaetigt, KurzTip-up";
CM_ SG_ 906 GRA_Down_lang "1 = Verzoegern
Betaetigung des Tipschalters 'Verzoegern' fuer t> 0.5 sec. Bedeutet 'Verzoegern'
GRA_ADR_verzoegern, LangTip-down";
CM_ SG_ 906 GRA_Up_lang "1 = Beschleunigen
Betaetigung des Tipschalters 'Beschleunigen' fuer t> 0.5 sec. Bedeutet 'Beschleunigen'
GRA_ADR_beschleunigen, LangTip-up";
CM_ SG_ 906 GRA_Fehler_Bed "1 = Fehler im Bedienteil";
CM_ SG_ 906 GRA_Kodierinfo "0 = GRA, 1 = ACC
Kodierinfo SMLS";
CM_ SG_ 906 GRA_Neu_Setzen "1 = Tipschalter betaetigt; Bei Sendercodierung '00' und '11' wird hier immer '0' uebertragen
Bei Sender Codierung '01' und '10' sind Tipsignale entprellt.
GRA_ADR_Tipschalter_Setzen";
CM_ SG_ 906 GRA_Recall "1 = Tipschalter betaetigt
Bei Sendercodierung '00' und '11' wird hier immer '0' uebertragen, Bei Sender Codierung '01' und '10' sind Tipsignale entprellt.
GRA_ADR_Tipschalter _Wiederaufnahme";
CM_ SG_ 906 GRA_Sender "00: Sender = Bordnetz-SG/BCM (4 Tasten / Rohwerte)
01: Sender = Lenksaeulenmodul mit 6 GRA Bedienelementen
10: Sender = nicht belegt
11: Sender = Lenksaeulenmodul mit 4 GRA Bedienelementen
GRA_ADR_Sendercodierung";
CM_ SG_ 906 GRA_Neu_Zaehler "Botschaftszaehler zur Erkennung fehlender GRA-Botschaften";
CM_ SG_ 906 GRA_Tip_Down "0 = Taste Down unbetaetigt, 1 = Taste Down betaetigt
Tiptronic Bedienung Down, Tiptronik-Tip-Down";
CM_ SG_ 906 GRA_Tip_Up "0 = Taste Up unbetaetigt, 1 = Taste Up betaetigt
Tiptronic Bedienung Up, Tiptronik-Tip-Up";
CM_ SG_ 906 GRA_Zeitluecke "Wird nur gesendet bei Sendercodierung '01'
00: Taste nicht betaetigt
01: Distanzwunsch kleiner
10: Distanzwunsch groesser
11: nicht definiert.
ADR Distanzwunsch, Zeitlückenverstellung";
CM_ SG_ 906 GRA_Sta_Limiter "1 = Limiterfunktion wird eingeschaltet";
CM_ SG_ 906 GRA_Typ_Hauptschalt "0 = Hauptschalter gerastet ein
1 = Hauptschalter getastet, d.h. nur Flankenübermittlung, Zustandserkennung im Motor-SG
Typ GRA Haupt-schalter/-taster";
CM_ SG_ 906 GRA_Sportschalter "z. Zt. nur Audi B7 RS4 (bewirkt Fahrpedal-Kennlinienumschaltung im Motor-SG)
Sportschalter";
CM_ SG_ 906 GRA_Fehler_Tip "1 = Fehler im Tiptronic Bedienteil";
CM_ SG_ 1510 Weckzeit_EV_erreicht "Information vom GSM Modul, daß die vom MSG programmierte Weckzeit erreicht wurde.";
CM_ SG_ 1510 GSM_MaxLeistung_NT "Vom EVU (Energieversorger) maximal zugelassene Leistung während NT-Zeit (Niedrigtarif).";
CM_ SG_ 1510 Standklimatisierung_Anf "Initialisierung der Standklimatisierung über das GSM-Modul";
CM_ SG_ 1510 Ladevorgang_Anf "Initialisierung des Ladevorgangs über das GSM-Modul";
CM_ SG_ 1510 GSM_Wake_Up_ACAN "0 = kein Wake-Up (z.B. KL15-Normalbetrieb)
1 = Anforderung zum Wecken des Antriebs-CAN
Das GSM Modul lernt anhand von MO7_Mot_weckfaehig, ob es das Bit setzen muss.";
CM_ SG_ 1510 Standklima_Temp_Vorwahl "Auto oder Temperatur, die vom Nutzer vorgewählt wurde.";
CM_ SG_ 1510 Ladestrom_max "Vom Kunden voreigestellter Ladestrom. Vorgabe gilt nur im Lademodus 0 (Schuko-Steckdose)";
CM_ SG_ 1510 GSM_Zeit_Typ "Gibt den Zeittyp an, der vom GSM Modul über die Signale der Zeitinfo gesendet wird.";
CM_ SG_ 1510 GSM_Jahr "0 für Datum unbekannt (z.B. keine Funkuhr)
(bei relativem Datum ist auch der Wert 0 gültig siehe Spezifikation_Tageszähler_Kombi_01.doc)";
CM_ SG_ 1510 GSM_Monat "0 = Monat unbekannt
Dh = ungueltig
Eh = relatives Datum siehe Spezifikation_Tageszähler_Kombi_01.doc
Fh = Keine Funkuhrinformation vorhanden und 12 h Anzeige (Monat, Tag, Jahr fehlen)";
CM_ SG_ 1510 GSM_Tag "0 für Datum unbekannt (z.B. keine Funkuhr)
(bei relativem Datum ist auch der Wert 0 gültig siehe Spezifikation_Tageszähler_Kombi_01.doc)";
CM_ SG_ 1510 GSM_Stunde "18h - 1Fh ungueltig";
CM_ SG_ 1510 GSM_Minute "3Ch - 3Fh ungueltig";
CM_ SG_ 1510 GSM_Ladestecker_Anf "Anforderung des GSM-Moduls an den Ladekoordinator zum ent- oder verriegeln des Ladesteckers.";
CM_ SG_ 1510 GSM_SOC_Untergrenze "HV-Batterieladezustand, der minimal durch Sofortladen erreicht werden soll. (Benutzervorgabe 0-100%)";
CM_ SG_ 1510 GSM_SOC_Obergrenze "HV-Batterieladezustand, bis zu dem in jedem Lademodus maximal geladen werden darf. (Benutzervorgabe 0-100%)";
CM_ SG_ 1529 GM_KD_Fehler "Mind. ein Kundendienstfehler ist eingetragen";
CM_ SG_ 1164 HS1_Checksumme "Prüfsumme mit Endwert 0x0, Definition im CAN Lastenheft (HS-CAN V4.2a, LS-CAN V1.42)";
CM_ SG_ 1164 HS1_Zaehler "Freilaufender Botschaftszähler gem. CAN Lastenheft";
CM_ SG_ 1164 HS1_Drehz_Grenze "Erkennung der Motordrehzahlgrenzen im ACC für die ACC-Funktion in Kombination mit Handschaltgetrieben für die Schaltaufforderung beim Erreichen der Komfortgrenzen bzw. die ACC-Abschaltung beim Erreichen der Abschaltgrenzen
ACC Motordrehzahlgrenze";
CM_ SG_ 1164 HS1_Gang "Erkennung der Ganginformation im ACC für die ACC-Funktion in Kombination mit Handschaltgetrieben
Ganginformation";
CM_ SG_ 210 HC1_Checksumme "Prüfsumme mit Endwert 0x0, Definition im CAN Lastenheft (HS-CAN V4.2a, LS-CAN V1.42)";
CM_ SG_ 210 HC1_Zaehler "Definition im CAN-Lastenheft
Freilaufender Botschaftszähler";
CM_ SG_ 210 HC1_Sta_HCA "0: HCA deaktiviert
1: HCA Anforderung nicht ausführbar (Lenkung Fehlerstatus)
2: Kommunikation zum Lenkhilfe-SG gestört
3: HCA funktionsbereit
4: reserviert
5: externer Momenteneingriff angefordert";
CM_ SG_ 210 HC1_LM_Offset "Reale Auflösung 0,01 Nm
Anforderung Lenkmomenten-Offset";
CM_ SG_ 210 HC1_LM_Offset_Sign "Vorzeichen Anforderung Lenkmomenten-Offset";
CM_ SG_ 210 HC1_Frequenz "Frequenz der Lenkradvibration";
CM_ SG_ 210 HC1_Amplitude "Amplitude der Lenkradvibration";
CM_ BO_ 1490 "CAN-Antrieb";
CM_ SG_ 1490 IDT_Mux "Multiplexbyte zur Berechnung der folgenden Datenbytes
Schaltet die naechsten 7 Byte um.
VW756/VW611: Reihenfolge der Inhalte für schnelle Initialisierung anderer Steuergeräte über Ident-Wert 0 folgendermaßen definiert 0, 1, 0, 2, 0, 1, 0, ...";
CM_ SG_ 1490 IDT_Geheimnis_1 "Multiplex = 0
1. Byte Fahrzeuggeheimnis (nicht PQ35/46)";
CM_ SG_ 1490 IDT_VIN_4 "Multiplex = 1
4. Stelle der Fahrgestellnummer
WFS nicht angelernt: Ausgabe 'X' (0x58) oder '-' (0x2D)";
CM_ SG_ 1490 IDT_VIN_11 "Multiplex = 2
11. Stelle der Fahrgestellnummer
WFS nicht angelernt: Ausgabe 'X' (0x58) oder '-' (0x2D)";
CM_ SG_ 1490 IDT_Geheimnis_2 "Multiplex = 0
2. Byte Fahrzeuggeheimnis (nicht PQ35/46)";
CM_ SG_ 1490 IDT_VIN_5 "Multiplex = 1
5. Stelle der Fahrgestellnummer
WFS nicht angelernt: Ausgabe 'X' (0x58) oder '-' (0x2D)";
CM_ SG_ 1490 IDT_VIN_12 "Multiplex = 2
12. Stelle der Fahrgestellnummer
WFS nicht angelernt: Ausgabe 'X' (0x58) oder '-' (0x2D)";
CM_ SG_ 1490 IDT_Geheimnis_3 "Multiplex = 0
3. Byte Fahrzeuggeheimnis (nicht PQ35/46)";
CM_ SG_ 1490 IDT_VIN_6 "Multiplex = 1
6. Stelle der Fahrgestellnummer
WFS nicht angelernt: Ausgabe 'X' (0x58) oder '-' (0x2D)";
CM_ SG_ 1490 IDT_VIN_13 "Multiplex = 2
13. Stelle der Fahrgestellnummer
WFS nicht angelernt: Ausgabe 'X' (0x58) oder '-' (0x2D)";
CM_ SG_ 1490 IDT_Geheimnis_4 "Multiplex = 0
4. Byte Fahrzeuggeheimnis (nicht PQ35/46)";
CM_ SG_ 1490 IDT_VIN_7 "Multiplex = 1
7. Stelle der Fahrgestellnummer
WFS nicht angelernt: Ausgabe 'X' (0x58) oder '-' (0x2D)";
CM_ SG_ 1490 IDT_VIN_14 "Multiplex = 2
14. Stelle der Fahrgestellnummer
WFS nicht angelernt: Ausgabe 'X' (0x58) oder '-' (0x2D)";
CM_ SG_ 1490 IDT_VIN_1 "Multiplex = 0
1. Stelle der Fahrgestellnummer
WFS nicht angelernt: Ausgabe 'X' (0x58) oder '-' (0x2D)";
CM_ SG_ 1490 IDT_VIN_8 "Multiplex = 1
8. Stelle der Fahrgestellnummer
WFS nicht angelernt: Ausgabe 'X' (0x58) oder '-' (0x2D)";
CM_ SG_ 1490 IDT_VIN_15 "Multiplex = 2
15. Stelle der Fahrgestellnummer
WFS nicht angelernt: Ausgabe 'X' (0x58) oder '-' (0x2D)";
CM_ SG_ 1490 IDT_VIN_2 "Multiplex = 0
2. Stelle der Fahrgestellnummer
WFS nicht angelernt: Ausgabe 'X' (0x58) oder '-' (0x2D)";
CM_ SG_ 1490 IDT_VIN_9 "Multiplex = 1
9. Stelle der Fahrgestellnummer
WFS nicht angelernt: Ausgabe 'X' (0x58) oder '-' (0x2D)";
CM_ SG_ 1490 IDT_VIN_16 "Multiplex = 2
16. Stelle der Fahrgestellnummer
WFS nicht angelernt: Ausgabe 'X' (0x58) oder '-' (0x2D)";
CM_ SG_ 1490 IDT_VIN_3 "Multiplex = 0
3. Stelle der Fahrgestellnummer
WFS nicht angelernt: Ausgabe 'X' (0x58) oder '-' (0x2D)";
CM_ SG_ 1490 IDT_VIN_10 "Multiplex = 1
10. Stelle der Fahrgestellnummer
WFS nicht angelernt: Ausgabe 'X' (0x58) oder '-' (0x2D)";
CM_ SG_ 1490 IDT_VIN_17 "Multiplex = 2
17. Stelle der Fahrgestellnummer
WFS nicht angelernt: Ausgabe 'X' (0x58) oder '-' (0x2D)";
CM_ SG_ 1512 KL_HV_ein "Gibt an, ob eine Hochvolt-Klimakomponente (HV-PTC, EKK) eingeschaltet ist.";
CM_ SG_ 1512 KL_Innengeblaese "Gibt an, ob das Innengebläse eingeschaltet ist.";
CM_ SG_ 1512 KL_PTC_Soll "PTC Soll Heizleistung";
CM_ SG_ 1512 KL_Wake_Up_ACAN "0 = kein Wake-Up (z.B. KL15-Normalbetrieb)
1 = Anforderung zum Wecken des Antriebs-CAN
Die RCP_Klima lernt anhand von MO7_Mot_weckfaehig, ob es das Bit setzen muss.";
CM_ SG_ 1512 KL_HV_Anf "Klimaanlage fordert die Aktivierung des Hochvoltbordnetz für Standklimatiserung an.";
CM_ SG_ 1512 KL_Ventil_Batterie_Anf "Das Klima-SG sendet eine Anforderung für den Soll-Schaltzustand des 3/2 Wegeventils für die HV-Batterie an die MED";
CM_ SG_ 1512 KL_Ventil_vor_Motor_Anf "Das Klima-SG sendet eine Anforderung für den Soll-Schaltzustand des 3/2 Wegeventils vor dem Motor an die MED";
CM_ SG_ 1512 PTC_Strom "Strom HV-PTC für Reichweitenberechnung";
CM_ SG_ 1512 EKK_Strom "Strom EKK für Reichweitenberechnung";
CM_ SG_ 1512 KL_Kompr_Drehzahl_Soll "Kompressordrehzahl";
CM_ SG_ 1512 EKK_Status "Signalisiert, ob der EKK zur Batteriekühlung oder (Stand-)klimatisierung aktiviert wurde.";
CM_ SG_ 1512 KL_Standklima_Status "Info an das GSM-Modul, daß Standklimatisierung nicht gestartet werden konnt oder abgebrochen wurde.
0 = Standklimatisierung aus
1 = Standklimatisierung ein
2 = Standklimatisierung nicht möglich, da Aussenhülle nicht geschlossen
3 = Standklimatisierung";
CM_ SG_ 1512 PTC_Pumpe_Ist "Info an das MSG über Ansteuerung PTC Wasserpumpe";
CM_ SG_ 1512 PTC_Pumpe_Status "Zustandsrückmeldung PTC Wasserpumpe";
CM_ SG_ 1512 KL_Charisma_FahrPr "Aktuelles Fahrprogramm des Charisma-Teilnehmers";
CM_ SG_ 1512 KL_Charisma_Status "Charisma Systemstatus des Charisma-Teilnehmers";
CM_ SG_ 1512 EKK_Status_Vorstrg "VW360/7: 1 = Kompressor ein, Zustand incl. 140ms Vorsteuerung, Info an das MSG: Kompressor EIN";
CM_ SG_ 1512 KL_Standklima_Strg_Kluefter "VW360/7: Ansteuerung des Kuehlerluefters in Prozent (Standklimatisierung)";
CM_ SG_ 1527 KE1_Comp_enable "Enable to start for compressor
After 1 second when High-voltage becomes available, turn on '1'";
CM_ SG_ 1527 KE1_Umluftstellung "Reserviert für Umluftstellung 0-100%";
CM_ SG_ 1527 KE1_Comp_rev_rq "Requested compressor revolution
0, 800-8600 rpm
below 800 rpm = compressor stop
800 - 8600 rpm = operation
over 8600 rpm = compressor stop";
CM_ BO_ 800 "PQ35/46 (Kombi-CAN)";
CM_ SG_ 800 KO1_SleepInd "SIB zwischen Kombi und Gateway (nur auf dem Kombi-CAN, wird aber auch auf A-CAN gespiegelt)
(z.Zt. nur Audi D3/C6, Audi AB2 und PQ46): Bit hält im PQ35/46 den CAN-Infotainment wach. Anmerkung: Bit wird bei 'Klemme 15 aus' auf 1 gesetzt, außer es liegt ei";
CM_ SG_ 800 KO1_Sta_Tank "nach 2 Sekunden liegt spätestens die Tankinfo vor
Fehlerstatus Tank";
CM_ SG_ 800 KO1_Oeldruck "Öldruckschalter";
CM_ SG_ 800 KO1_Sta_Oeldr "Öldruckwarnung könnte auch vom Empfänger des Öldruckschalters generiert werden
Dynamische Öldruckwarnung";
CM_ SG_ 800 KO1_Kuehlmittel "Kühlmittelmangel";
CM_ SG_ 800 KO1_Wakeup_Komfort "Das Audi PQ35-/ VW PQ46 Kombi kann durch Setzen dieses Bits bei aktivem Kombi-CAN den Komfort-CAN aufwecken oder wachhalten
Anmerkung: alle Funktionen, die einen aktiven Komfort-CAN benötigen (z.B. Warnblinken) müssen dieses Bit auf 1 setzen.";
CM_ SG_ 800 KO1_Warn_Tank "Fahrer wird gewarnt (z. Zt. 7 Liter)";
CM_ SG_ 800 KO1_Vorgluehen "Rückmeldeinformation für das Motorsteuergerät
Vorglühlampe (Kombi 1)";
CM_ SG_ 800 KO1_Bremsinfo "Bit 0 Bremsflüssigkeitswarnung
Bit 1 Handbremsschalter (nicht bei Audi)
A0-Klasse hat z. Zt. einen gemeinsamen Eingang für Bremsflüssigkeitsstand und Handbremse, d.h. es ist keine Unterscheidung möglich";
CM_ SG_ 800 KO1_Handbremse "Umgesetzt bei VW, Audi B6, B7
Nicht bei Audi-Fahrzeugen mit EPB (Audi D3, C6)
Sonderfall PQ46: Hardware-Eingang von EPB zur Ansteuerung der BKL-Lampe, auch im Betriebsfall BKL-Blinken!
Sonderfall BY61x: Gespiegelt aus EPB-Botschaft CAN-Antrieb.";
CM_ SG_ 800 KO1_La_Ladekon "Kombi hat seine Ladekontroll-Lampe eingeschaltet (Empfänger: z.Zt. Batman), nicht PQ35/46, nicht Audi D3/C6";
CM_ SG_ 800 KO1_Stellglieder "Im Stellgliedtest werden auch Lampen angesteuert (Achtung: Rückmeldebits können gesetzt sein)";
CM_ SG_ 800 KO1_Zeitluecke "nur in ADR/ACC-Fahrzeugen:
ACC Zusatzanzeige: 0 = aus / ungleich 0 = ein
angezeigte ADR-Zeitlücke wird auf 3 Bits begrenzt
ACC Zusatzanzeige / Angezeigte Zeitlücke";
CM_ SG_ 800 KO1_Tankstop "Kombi hat Tankstop erkannt (Vorsicht: Wartezeit nach Klemme 15 ein berücksichtigen)
Flag wird nach 5 Sekunden bei fahrendem Fahrzeug gelöscht
";
CM_ SG_ 800 KO1_Tankinhalt "Restmenge 2 bzw. 2,5l nicht auflösbar
7FH ist Fehler. Bei Klemme 15 aus werden hier die zuletzt bei Kl. 15 ein ermittelten Werte gesendet.";
CM_ SG_ 800 KO1_OBD_Tank "OBD-Schwelle (z. Zt. 15 %, applizierbar)
Tankwarnung";
CM_ SG_ 800 KO1_Quelle_kmh "Die Fahrzeuggeschwindigkeit wird aus einem Tachogeber (eigener Hallgeber, eigener Reed-Kontakt, Fahrtenschreiber) oder aus der Referenzgeschwindigkeit vom ABS berechnet (nicht Audi D3/C6)
Signalquelle Geschwindigkeit";
CM_ SG_ 800 KO1_kmh "Fahrzeuggeschwindigkeit als Rohsignal vom Tachogeber (ab ca. 25 km/h eine Geberradumdrehung, d.h. z.Zt. Mittelwert aus 4 Perioden der wahren Geschwindigkeit) oder vom ABS-Steuergerät (Raddrehzahl x Radumfang)
die Auflösung entspricht der ABS-Geschwindigk";
CM_ SG_ 800 KO1_Zaehler "Plausibilisierung erfolgt im ACC-/ADR- System: im PQ46 nur bei ACC unterstützt
Botschaftszähler";
CM_ SG_ 800 KO1_ACC_Inkons "Rückmeldung zum ACC-/ADR- System bzgl. CAN- Lastenheft
ACC Botschaft(en) nicht konsistent";
CM_ SG_ 800 KO1_ACC_AnzFhl "Bit wird bei einem ACC/ADR relevanten Fehler (Anzeige/Gong) gesetzt.
ACC Anzeige Fehler";
CM_ SG_ 800 KO1_angez_kmh "Am Tacho angezeigte Geschwindigkeit (incl. Voreilung)
(0xFF im High-Byte (Byte 7 von mKombi_1) = Fehler)";
CM_ SG_ 800 KO1_kmh_mph "Dem Fahrer wird die Geschwindigkeit in km/h oder in Miles/hour angezeigt (über Personalisierung verstellbar) (bei Audi konstanter Wert)
Einheit der angezeigten Geschwindigkeit";
CM_ SG_ 800 KO1_ABS_Lampe "ABS-Sicherheits-Lampe wurde eingeschaltet";
CM_ SG_ 800 KO1_ASRESP_Lampe "ASR-/ESP-Sicherheits-Lampe wurde eingeschaltet";
CM_ SG_ 800 KO1_Brems_Lampe "Sicherheits-Lampe Bremskontrolle wurde eingeschaltet
Besonderheit (VW PQ35/46): Lampe wird auch zur Handbremskontrolle (Audi: auch von EPB) und Bremsflüssigkeitswarnung (auch bei Audi) verwendet und vom Kombi aufgeprüft";
CM_ SG_ 800 KO1_Airbag_Lampe "Airbag Sicherheits-Lampe wurde eingeschaltet";
CM_ SG_ 800 KO1_Lenkh_Lampe "Lenkhilfe-Sicherheits-Lampe wurde eingeschaltet";
CM_ SG_ 800 KO1_LDW_AnzFeh "Kombiinstrument hat Fehler erkannt
LDW-Anzeigefehler";
CM_ SG_ 800 KO1_SILA_gueltig "Rückmeldeinformation (Bit 1-5) ist gültig
Anmerkung: Rückmeldeinformationen werden bedient; Lampen sind bei 'Klemme 15 aus' ausgeschaltet";
CM_ SG_ 1056 KO2_Sta_Auss_T "Diese Botschaft wird mit der Botschaft mKombi_1 zeitlich verzahnt gesendet!!!
n.i.O. steht für Fehlerwert, außerhalb des Meßbereichs (ungenau), nicht verbaut oder noch kein aktueller Wert
Besonderheit Initwerte Temperaturen (bei VW und Audi ???):

0/1";
CM_ SG_ 1056 KO2_Verb_TOG "'TOG nicht verbaut': TOG nicht am Kombi angeschlossen
TOG-Botschaft wird nicht vom Kombi gesendet (Bit wird bei Audi nicht unterstützt)";
CM_ SG_ 1056 KO2_Oelwarn "Ölwarnschwelle plus Offset überschritten
(wird in mKombi_2 verwendet, falls bei WIV3.2 der TOG-Sensor nicht direkt am Kombi angeschlossen ist, siehe mKombi_2, Byte 1, Bit 1)";
CM_ SG_ 1056 KO2_GRA_High "Kombi unterstützt die 'GRA High' (Sollgeschwindigkeit wird angezeigt)
GRA-High-Anzeige im Display wird unterstützt";
CM_ SG_ 1056 KO2_Temp_Einheit "Außentemperatur Anzeige im Kombi wird in Grad Celsius oder Fahrenheit gemacht
Temperatureinheit";
CM_ SG_ 1056 KO2_Wischwasser "Zusatzinfo zur Scheinwerferreinigungsanlage (z. Zt. nur Audi D3)
Wischwasserwarnung";
CM_ SG_ 1056 KO2_PLA_Displaystatus "Das Signal wird als aktive Rückmeldung genutzt, ob die Info des PLA im Kombi angezeigt wird. Wenn nach Anforderung des Displays das Signal zweimal auf 0 ist, wird der Parkvorgang abgebrochen.
Ein Kombi, dass PLA Anzeige nicht unterstützt, schickt dauerha";
CM_ SG_ 1056 KO2_Fehlereintr "Bei gesetztem Bit ist mindestens ein Kundendienstfehler eingetragen
Fehlerspeichereintrag (Kombi 2)";
CM_ SG_ 1056 KO2_gef_Auss_T "realer Meßbereich z. Zt. ca. -45..58 Grad
0 für nicht verbaut

im Fehlerfall (FFH) ggf. auf Byte 8, Bit 7..4 achten
Außentemperatur gefiltert";
CM_ SG_ 1056 KO2_Aussen_T "Klima-Steuergerät kann aus dem Rohsignal eigene Plausibilitäten berechnen
0 für nicht verbaut
im Hochlauf alter abgespeicherter Wert bis neuer vorliegt
Besonderheit Initwerte Temperaturen (bei VW und Audi ???):

0/1*:
0: Klemme 30 Reset
1: Klemme 1";
CM_ SG_ 1056 KB2_EasyEntry "Umschaltanforderung von der MFA des Kombi-SG für die Aktivierung/Deaktivierung der Easy-Entry-Funktion im Memorysitz";
CM_ SG_ 1056 KBI_rotes_P_verbaut "Das Signal dient der EPB zur Unterscheidung, ob das Kombi das 'rote P' unterstützt.";
CM_ SG_ 1056 KO_Segeln_Menuestatus "Signalisierung ob im Kombi ein Menü für die Funktion 'Segeln'/'Freilauf' verfügbar ist";
CM_ SG_ 1056 KO_Segeln_Zustandswechsel "Statuswechsel Segelwunsch des Fahrers";
CM_ SG_ 1056 KB2_Auto_eKiSi "Umschaltung automatische E-KiSi";
CM_ SG_ 1056 KB2_Req_IstZu_Solldruecke "Anforderung für RKA/RDK die Istdrücke als neue Solldrücke zu übernehmen für Systeme mit Menübedienung im Kombi";
CM_ SG_ 1056 KO2_Bel_Displ "Display-Beleuchtung, Tastverhältnis in Prozent
Klemme 58d";
CM_ SG_ 1056 KO2_Sta_Displ "N.i.O. steht für nicht verfügbar oder Ersatzwert in Bit 6..0 wird vorgegeben (Standard)
VW Highline / Mini-DOT und Audi Kombis geben das mit dem Fototransister bewertete Signal aus
Fehlerstatus Kl. 58 d";
CM_ SG_ 1056 KO2_Bel_Schalt "Schalter-Beleuchtung (z.Zt. nur Audi) ,Tastverhältnis in Prozent
Klemme 58s (Kombi 2)";
CM_ SG_ 1056 KO2_Sta_Schalt "N.i.O. steht für nicht verfügbar (z. Zt. bei VW) oder Ersatzwert in Bit 6..0 wird vorgegeben
Fehlerstatus Kl. 58 s (Kombi 2)";
CM_ SG_ 1056 KO2_MFA_v_Einheit "Meldung an den Motor, mit welcher Einheit die GRA-Geschwindigkeit dargestellt wird, damit der Motor in der Botschaft Motor_8 die GRA-Wunschgeschwindigkeit anzeigeoptimiert ausgeben kann (Verhinderung von Werten, die keiner Meilengröße entsprechen). (im Au";
CM_ SG_ 1056 KO2_Passiv_Autolock "1 = Umschaltanforderung vom Kombi: 'Passiv Autolock / Autounlock'";
CM_ SG_ 1056 KO2_WFS_Schl_Ort "Schlüsselerkennung via Lesespule oder Keyless";
CM_ SG_ 1056 KB2_MFA_Strecke_Einheit "reserviert für SCR-Reststreckeneinheit (nur AU716!)";
CM_ SG_ 1056 KO2_OBD_Nib_Temp "Die Motorsteuerung muss bei einem Sensorfehler Fehlerarten unterscheiden können (CARB-Forderung)
(PQ35/46 geplant zu KW 22/07, Touareg GP 22/08)
0000 = kein Fehler
0001 = KS-
0010 = KS+
0011 = OC
0100 = OOR+
0101 = OOR-
0110 = RC+
0111 = RC-
100";
CM_ SG_ 1312 KO3_Sprache "Code 00: Länder- und Sprachvariante werden nur ausgegeben, wenn Sie im Kombi vorliegen (z.B. Highline)
Kombi Multiplex Info (Sprachvariante)";
CM_ SG_ 1312 KO3_Derivat "Code 01: Plattforminformation entspricht dem Kenntnisstand des Kombis; als Derivat wird 0 (Kurzheck) ausgegeben, wenn es keine Besonderheiten abhängig vom Derivat gibt
Kombi Multiplex Info (Plattform/Derivat)";
CM_ SG_ 1312 KO3_Radumfang "Code 10: mittlerer Reifenumfang in Millimeter (Byte 2 Bit 5,4 reserviert, Byte 2 Bit 3..0 und Byte 1 Bit 7..0; Wertebereich 0..4096 mm)
Kombi Multiplex Info (Radumfang)";
CM_ SG_ 1312 KO3_Verbau_Mot "Code 11: Verbauliste nach Kenntnisstand des Kombis
Verbauliste Motor";
CM_ SG_ 1312 KO3_Verbau_Get "Code 11: Verbauliste nach Kenntnisstand des Kombis
Verbauliste Getriebe";
CM_ SG_ 1312 KO3_Verbau_Br "Code 11: Verbauliste nach Kenntnisstand des Kombis
Verbauliste Bremse";
CM_ SG_ 1312 KO3_Verbau_Kl "Code 11: Verbauliste nach Kenntnisstand des Kombis
Verbauliste Klima";
CM_ SG_ 1312 KO3_Generation "Code 01: Plattforminformation entspricht dem Kenntnisstand des Kombis
Kombi Multiplex Info (Plattform/Generation)";
CM_ SG_ 1312 KO3_Verbau_Air "Code 11: Verbauliste nach Kenntnisstand des Kombis
Verbauliste Airbag";
CM_ SG_ 1312 KO3_Verbau_ADR "Code 11: Verbauliste nach Kenntnisstand des Kombis
Verbauliste ADR";
CM_ SG_ 1312 KO3_Verbau_BN "Code 11: Verbauliste nach Kenntnisstand des Kombis
Verbauliste Bordnetz";
CM_ SG_ 1312 KO3_Verbau_Syn "Code 11: Verbauliste nach Kenntnisstand des Kombis
Verbauliste Allrad";
CM_ SG_ 1312 KO3_Land "Code 00: Länder- und Sprachvariante werden nur ausgegeben, wenn Sie im Kombi vorliegen (z.B. Highline)
Kombi Multiplex Info (Ländervariante)";
CM_ SG_ 1312 KO3_Baureihe "Code 01: Plattforminformation entspricht dem Kenntnisstand des Kombis
Kombi Multiplex Info (Plattform/Baureihe)";
CM_ SG_ 1312 KO3_Verbau_LWS "Code 11: Verbauliste nach Kenntnisstand des Kombis
Verbauliste Lenkwinkel";
CM_ SG_ 1312 KO3_Verbau_DP "Code 11: Verbauliste nach Kenntnisstand des Kombis
Verbauliste Dieselpumpe";
CM_ SG_ 1312 KO3_Verbau_LH "Code 11: Verbauliste nach Kenntnisstand des Kombis
Verbauliste Lenkhilfe";
CM_ SG_ 1312 KO3_Marke "Code 01: Plattforminformation entspricht dem Kenntnisstand des Kombis
Kombi Multiplex Info (Plattform/Marke)";
CM_ SG_ 1312 KO3_Verbau_Niveau "Code 11: Verbauliste nach Kenntnisstand des Kombis
Verbauliste Niveauregulierung";
CM_ SG_ 1312 KO3_Mp_Code "Code 00 Ländervariante, Sprachvariante: Land, Sprache (nur Highline)
Code 01 Plattform: Plattforminfo, die im Kombi vorliegt
Code 10 Radumfang: mittlerer Radumfang (aus der K-Zahl gerechnet)
Code 11 Verbauliste: Verbauliste nach Kenntnisstand des Kombi";
CM_ SG_ 1312 KO3_Schluessel "0 = ungueltig, xxxx = Schluessel-Nr.
Schluesselinformation (s. Kombi_3)";
CM_ SG_ 1312 KO3_Um_AFS2 "Aufforderung an das AFS.
Funktion auch während der Fahrt bedienbar.
Gedrückter Taster bewirkt Umschaltung im AFS-Steuergerät (siehe mLWR_Zustand, Byte 6, Bit 4,5)
Umschaltung AFS II";
CM_ SG_ 1312 KO3_Um_Tourist "Aufforderung an das AFS.
Gedrückter Taster bewirkt Umschaltung im AFS-Steuergerät (siehe mLWR_Zustand, Byte 6, Bit 6,7)
Touristenfunktion umschalten";
CM_ SG_ 1312 KO3_Um_AutoHold "Umstellung der 'Auto Hold'-Funktion im MFA-Display als Rückmeldung für die EPB (PQ46 ab 22/08, VW469)
Gedrückter Taster bewirkt Umschaltung im EPB-Steuergerät (siehe mEPB_1, Byte 5, Bit 2,3)
Auto Hold umschalten";
CM_ SG_ 1312 KO3_SWA_AnzFeh "Kombiinstrument hat Fehler erkannt
SWA Anzeigefehler";
CM_ SG_ 1312 KO3_Standzeit "(0...36,4 h) Standzeit in 4 Sekunden Auflösung
mit diesen 15 Bits läßt sich eine Zeit bis 36 Stunden, 24 Minuten und 28 Sekunden darstellen
Der Standzeitzähler wird mit 'Klemme 15 aus' gestartet, er bleibt 2 Minuten vor einem Überlauf stehen, dieser alt";
CM_ SG_ 1312 KO3_Sta_Standz "Reset Standzeit";
CM_ SG_ 1312 KO3_Kilometer "Kilometerstand";
CM_ SG_ 1564 Restladezeit_HV_Batterie "Zeit, bis HV-Batterie vollständig geladen ist. Angabe in 5 Minuten Schritten. Maximum 10h 30Min";
CM_ SG_ 1564 Lademodus_HV_Batterie "Gibt den Aktuell eingestellten Lademodus an.
0 = Sofortladenmodus (Taster, GSM)
1 = zeitversetztes Laden";
CM_ SG_ 1564 LM_EKlKomLeiRed "Anforderung an die Klimasteuerung, die Leistungsaufnahme des E-Kompressors bei schlechtem SOC und in bestimmten Fahrsituationen zu begrenzen.
(Das bereits bestehende Signal 'Klimakompressor aus' Motor5, Byte2, Bit5 als stets umzusetzende Anforderung blei";
CM_ SG_ 1564 LM_HV_PTC_aus "MSG schaltet HV-PTC aus";
CM_ SG_ 1564 LM_HV_PTC_LeistRed "Anforderung an die Klimasteuerung, die Leistungsaufnahme des HV-PTC bei schlechtem SOC und in bestimmten Fahrsituationen zu begrenzen.
(Das bereits bestehende Signal 'Klimakompressor aus' Motor5, Byte2, Bit5 als stets umzusetzende Anforderung bleib)";
CM_ SG_ 1564 LM_KlimaKompr "Motor-Steuergerät schaltet Klimakompressor aus";
CM_ SG_ 1564 LM_Bat_heiz_aktiv "0 = Batteriekonditionierung heizen nicht aktiv
1 = Batteriekonditionierung heizen aktiv";
CM_ SG_ 1564 LM_Bat_kuehl_aktiv "0 = Batteriekonditionierung kühlen nicht aktiv
1 = Batteriekonditionierung kühlen aktiv";
CM_ SG_ 1564 LM_Bat_laden_aktiv "0 = Batterieladen nicht aktiv
1 = Batterieladen aktiv";
CM_ SG_ 1564 LM_Wake_Up_KCAN "0 = kein Wake-Up (z.B. KL15-Normalbetrieb)
1 = Anforderung zum Wecken des Komfort-CAN (Ladestecker gesteckt)";
CM_ SG_ 1564 LM_Standkl_heiz_aktiv "0 = Standklimatisierung heizen nicht aktiv
1 = Standklimatisierung heizen aktiv";
CM_ SG_ 1564 LM_Standkl_kuehl_aktiv "0 = Standklimatisierung kühlen nicht aktiv
1 = Standklimatisierung kühlen aktiv";
CM_ SG_ 1564 LM_MaxLadLeistung_HV "Maximale Leistung Ladegerät bezogen auf die maximale Leistung Infrastruktur (Kabel, Ladestation) und Berücksichtigung des Ladegerät-Wirkungsgrades";
CM_ SG_ 1470 LDW_Lernmodus_seitenabhaengig "Signal dient zur Ansteuerung von Funktionsanzeigen im Mitteldisplay des Kombiinstruments für die seitenabhängige Liniendetektion";
CM_ SG_ 1470 LDW_Lernmodus "Ansteuerung von LDW-Funktionsanzeigen im Mitteldisplay Kombiinstrument analog B8/Q5 (im AU716, C6)";
CM_ SG_ 1470 LDW_Gong "Gong";
CM_ SG_ 1470 LDW_Lampe_gelb "Lampenansteuerung gelb im Kombiinstrument";
CM_ SG_ 1470 LDW_Lampe_gruen "Lampenansteuerung grün im Kombiinstrument";
CM_ SG_ 1470 LDW_SW_Warnung_links "Die Kamera erkennt einen kurz bevorstehenden möglichen Spurwechsel auf der linken Seite. Das Signal dient dazu, Side Assist in den Warnmodus umzuschalten, obwohl der Fahrer nicht blinkt.";
CM_ SG_ 1470 LDW_SW_Warnung_rechts "Die Kamera erkennt einen kurz bevorstehenden möglichen Spurwechsel auf der rechten Seite. Das Signal dient dazu, Side Assist in den Warnmodus umzuschalten, obwohl der Fahrer nicht blinkt.";
CM_ SG_ 1470 LDW_KD_Fehler "Bei gesetztem Bit ist mindestens ein Kundendienstfehler eingetragen";
CM_ SG_ 1470 LDW_DLC "distance to line, Abstand vom Fahrzeug zur Fahrbahnmarkierung
Der Wert gibt die Breite der Restspur zur Linie wieder (Abstand vom Fahrzeugäußerem zur Linie) (Wert POSITIV wenn Fahrzeug in der Spur - Wert NEGATIV wenn Fahrzeug über der Linie)";
CM_ SG_ 1470 LDW_TLC "time to line, Zeit bis das Fahrzeug die Fahrbahnmarkierung überquert";
CM_ SG_ 1470 LDW_Seite_DLCTLC "Zuordnung auf welche Seite sich LDW_DLC bzw. LDW_TLC beziehen";
CM_ SG_ 1470 LDW_Frueh_Spaet "Im MMI eingestellter, aktiver Lenkeingriffszeitpunkt:
0: frueh, frueh aktiv
1: frueh, spaet aktiv
2: spaet, spaet aktiv
3: Fehler";
CM_ BO_ 976 "CAN-Antrieb";
CM_ SG_ 976 LH1_Lastinfo "reale Auflösung z. Zt. 5 Ampere
Lastinformation";
CM_ SG_ 976 LH1_Fehler_LI "n.i.O. steht für Fehlerwert oder Lastinformation noch nicht verfügbar
Fehlerstatus Lastinformation";
CM_ SG_ 976 LH1_Sicherheitslamp "steuert direkt die Sicherheitswarnlampe Lenkhilfe (rot) an (bei EHPS VW25x gelbe LED)";
CM_ SG_ 976 LH1_Fehlerlampe "steuert direkt die Fehlerlampe Lenkhilfe (gelb); kein Aufprüfen bei Neustart, keine Rückleseinformation in Kombi-Botschaft";
CM_ SG_ 976 LH1_Textbits "Diese Textbits werden verwendet, um im Kombi Texte oder Bilder für die Lenkhilfe darzustellen

Hybrid:
Text 1 (ID_TXT_1026.1): Ausfall Lenkunterstützung
Text 2 (ID_TXT_1026.2): Fehler Lenkunterstützung
Text 3 (ID_TXT_1026.3): Kurzzeitige Störung Lenk";
CM_ SG_ 976 LH1_Akustiksign "Ansteuerung eines Akustiksignals (Summer) im Kombi (optional vorgehalten)";
CM_ SG_ 976 LH1_SleepInd "Die Sleep-Bereitschaft wird nach Klemme 15 aus durch Setzen dieses Bits signalisiert
NMHigh-Teilnehmer der PQ35/46 müssen das Signal nach Kl.-15 aus weiterhin bedienen oder dauerhaft auf 1 = 'Sleep bereit' setzen!
Sleep-Indication (Lenkhilfe 1)";
CM_ SG_ 976 LH1_Fehlereintr "Bei gesetztem Bit ist mindestens ein Kundendienstfehler eingetragen
Fehlerspeichereintrag (Lenkhilfe 1)";
CM_ SG_ 976 LH1_EPS_Diagmode "Anzeige, ob sich die Lenkhilfe in einem Diagnose Mode befindet.
EPS Diagnosemode";
CM_ SG_ 976 LH1_gue_ECU_Temp "(war: 'Bordnetzwelligkeit gültig')
Gültigkeit der Signale ECU-Temperatur";
CM_ SG_ 976 LH1_Kuehlung "nach Überschreiten einer oberen Grenztemperatur fordert die EPS die Zuschaltung einer externen Kühlung, z. B. durch den Kühlerlüfter
Anforderung Kühlung";
CM_ SG_ 976 LH1_Mode_Hybrid "Reserviert für Hybrid-Modus (kodierbar)
Mode Hybrid-Antrieb";
CM_ SG_ 976 LH1_NL_Untersp "Bit-Feld zeigt an, dass sich die Lenkhilfe in einem Notlaufprogramm befindet und durch welche Ursache dieses aktiviert wurde:
0: ist nicht Auslöser eines Notlaufes
1: ist Auslöser eines Notlaufes
Das Betriebsverhalten der Lenkhilfe wird an das bestehen";
CM_ SG_ 976 LH1_NL_Uebersp "Bit-Feld zeigt an, dass sich die Lenkhilfe in einem Notlaufprogramm befindet und durch welche Ursache dieses aktiviert wurde:
0: ist nicht Auslöser eines Notlaufes
1: ist Auslöser eines Notlaufes
Das Betriebsverhalten der Lenkhilfe wird an das bestehen";
CM_ SG_ 976 LH1_NL_Uebertemp "Bit-Feld zeigt an, dass sich die Lenkhilfe in einem Notlaufprogramm befindet und durch welche Ursache dieses aktiviert wurde:
0: ist nicht Auslöser eines Notlaufes
1: ist Auslöser eines Notlaufes
Das Betriebsverhalten der Lenkhilfe wird an das bestehen";
CM_ SG_ 976 LH1_NL_Sensor "Bit-Feld zeigt an, dass sich die Lenkhilfe in einem Notlaufprogramm befindet und durch welche Ursache dieses aktiviert wurde:
0: ist nicht Auslöser eines Notlaufes
1: ist Auslöser eines Notlaufes
Das Betriebsverhalten der Lenkhilfe wird an das bestehen";
CM_ SG_ 976 LH1_NL_CAN_SS "Bit-Feld zeigt an, dass sich die Lenkhilfe in einem Notlaufprogramm befindet und durch welche Ursache dieses aktiviert wurde:
0: ist nicht Auslöser eines Notlaufes
1: ist Auslöser eines Notlaufes
Das Betriebsverhalten der Lenkhilfe wird an das bestehen";
CM_ SG_ 976 LH1_NL_ECU "Bit-Feld zeigt an, dass sich die Lenkhilfe in einem Notlaufprogramm befindet und durch welche Ursache dieses aktiviert wurde:
0: ist nicht Auslöser eines Notlaufes
1: ist Auslöser eines Notlaufes
Das Betriebsverhalten der Lenkhilfe wird an das bestehen";
CM_ SG_ 976 LH1_NL_Motor "Bit-Feld zeigt an, dass sich die Lenkhilfe in einem Notlaufprogramm befindet und durch welche Ursache dieses aktiviert wurde:
0: ist nicht Auslöser eines Notlaufes
1: ist Auslöser eines Notlaufes
Das Betriebsverhalten der Lenkhilfe wird an das bestehen";
CM_ SG_ 976 LH1_NL_LeistDichte "Bit-Feld zeigt an, dass sich die Lenkhilfe in einem Notlaufprogramm befindet und durch welche Ursache dieses aktiviert wurde:
0: ist nicht Auslöser eines Notlaufes
1: ist Auslöser eines Notlaufes
Das Betriebsverhalten der Lenkhilfe wird an das bestehen";
CM_ SG_ 976 LH1_ULeistung "Die Unterstützungsleistung gibt prozentual an, in welchem Verhältnis die tatsächlich abgegebene Leistung zur Nominalleistung steht, d.h.:
0% : keine Servounterstützung
100%: maximale Servounterstützung (Nominalleistung)
0% < Unterstützungsleistung < 10";
CM_ SG_ 976 LH1_ECU_Temp "(war: 'Bordnetzwelligkeit')
Temperatur innerhalb der ECU";
CM_ SG_ 978 LH2_Checksumme "Prüfsumme mit Endwert 0x0, Definition im CAN Lastenheft (HS-CAN V4.2a, LS-CAN V1.42)";
CM_ SG_ 978 LH2_Zaehler "Freilaufender Botschaftszähler, Definition nach CAN-Lastenheft";
CM_ SG_ 978 LH2_Geradeaus "Geradeausfahrt wird angezeigt, wenn sichergestellt ist, dass sich der Lenkwinkel im Sektor +-180° befindet (Mittensektoranzeige)
(nur der LWS empfängt dieses Bit noch)";
CM_ SG_ 978 LH2_Sta_Charisma "Bedeutung der Status-Indices:
0: Charisma in der EPS deaktiviert
1: Sonderkennung mit Komfort-Charakteristik
2: Default: Standardkennung der EPS
3: Sonderkennung mit Sport-Charakteristik
Status Charisma";
CM_ SG_ 978 LH2_Sta_HCA "Bedeutung der Status-Indizes:
0: HCA in der EPS deaktiviert
1: HCA Anforderung nicht ausführbar aufgrund von Init-Phase o.Ä. ohne Fehlerspeichereintrag in der Lenkung (Initialisierung, Ausschaltphase, ¿)
2: HCA Anforderung nicht ausführbar aufgrund ein";
CM_ SG_ 978 LH2_Ausg_LW1 "Steht dieser Wert auf 1, gibt die Lenkhilfe die Lenkwinkelbotschaft Lenkwinkel1 aus. Die Ausgabe ist über den Tester aktivierbar. Dies setzt voraus, dass der Lenkstockschalter diese Botschaft nicht ausgibt.";
CM_ SG_ 978 LH2_Ausg_LW1_gue "Signal Ausgabe LW1 darf nur ausgewertet warden, wenn das Gültigkeitsbit gesetzt ist.
Gültigkeit Ausgabe LW1";
CM_ SG_ 978 LH2_StatEPS_PLA "16 Statuswerte (siehe LH PLA/EPS)
Status EPS PLA";
CM_ SG_ 978 LH2_aktLenkeingriff "Indikation, welcher Eingriff in die Momentenschnittstelle der EPS in der Umsetzung ist.
Bitfeldreihenfolge entspricht Priorität, EPS priorisiert bei zeitgleicher Anforderung
Bit 0: kein Eingriff
Bit 1: DSR
Bit 3: Heading Control
Bit 5: Torque Steer
";
CM_ SG_ 978 LH2_PLA_Err "Art des Fehlers ohne Eintrag, 16 Werte möglich (siehe LH EPS/PLA)";
CM_ SG_ 978 LH2_PLA_Abbr "Grund des PLA-Abbruchs, 16 Werte möglich (siehe LH EPS/PLA)";
BA_DEF_ BO_  "GenMsgAutoGenDsp" ENUM  "No","Yes";
BA_DEF_ BO_  "GenMsgAutoGenSnd" ENUM  "No","Yes";
BA_DEF_ BO_  "GenMsgCycleTime" INT 0 65535;
BA_DEF_ BO_  "GenMsgCycleTimeFast" INT 0 65535;
BA_DEF_ BO_  "GenMsgDelayTime" INT 0 100000;
BA_DEF_ BO_  "GenMsgILSupport" ENUM  "No","Yes";
BA_DEF_ BO_  "GenMsgSendType" ENUM  "Cyclic","not_used","not_used","not_used","not_used","not_used","not_used","IfActive","NoMsgSendType";
BA_DEF_ BO_  "GenMsgStartDelayTime" INT 0 100000;
BA_DEF_ BO_  "NmMessage" ENUM  "No","Yes";
BA_DEF_ BO_  "NmhMessage" ENUM  "No","Yes";
BA_DEF_ BO_  "VAGTP20_API" HEX 0 255;
BA_DEF_ BO_  "VAGTP20_DynConnection" ENUM  "No","Yes";
BA_DEF_ BO_  "VAGTP20_DynSetup" ENUM  "No","Yes";
BA_DEF_ BO_  "VAGTP20_StatConnection" ENUM  "No","Yes";
BA_DEF_ BO_  "Timeoutzeit" INT 0 1000000;
BA_DEF_ BO_  "DiagRequest" ENUM  "No","Yes";
BA_DEF_ BO_  "DiagResponse" ENUM  "No","Yes";
BA_DEF_ BO_  "DiagState" ENUM  "No","Yes";
BA_DEF_ BO_  "GenMsgChkConstant" HEX 0 4095;
BA_DEF_ SG_  "GenSigAutoGenDsp" ENUM  "No","Yes";
BA_DEF_ SG_  "GenSigAutoGenSnd" ENUM  "No","Yes";
BA_DEF_ SG_  "GenSigEnvVarType" ENUM  "int","float","undef";
BA_DEF_ SG_  "GenSigInactiveValue" INT -2147483648 2147483647;
BA_DEF_ SG_  "GenSigSendType" ENUM  "Cyclic","OnWrite","OnWriteWithRepetition","OnChange","OnChangeWithRepetition","IfActive","IfActiveWithRepetition","NoSigSendType","OnChangeAndIfActive","OnChangeAndIfActiveWithRepetition";
BA_DEF_ SG_  "GenSigStartValue" INT -2147483648 2147483647;
BA_DEF_ SG_  "NWM-WakeupAllowed" ENUM  "No","Yes";
BA_DEF_ SG_  "GenSigFuncType" ENUM  "NoFunction","MsgCounter","CRC-8","XOR","XOR-2","DatedBit","SW-Kl15","CHK","Constant","Protocol";
BA_DEF_ SG_  "GenSigSwitchedByIgnition" ENUM  "No","Yes";
BA_DEF_ SG_  "Fehlerwert" HEX 0 2147483647;
BA_DEF_ SG_  "GenSigMissingSourceValue" HEX 0 2147483647;
BA_DEF_REL_ BU_SG_REL_  "GenSigTimeoutTime" INT 0 65535;
BA_DEF_DEF_REL_ "GenSigTimeoutTime" 0;
BA_DEF_DEF_  "GenMsgAutoGenDsp" "Yes";
BA_DEF_DEF_  "GenMsgAutoGenSnd" "Yes";
BA_DEF_DEF_  "GenMsgCycleTime" 0;
BA_DEF_DEF_  "GenMsgCycleTimeFast" 0;
BA_DEF_DEF_  "GenMsgDelayTime" 0;
BA_DEF_DEF_  "GenMsgILSupport" "No";
BA_DEF_DEF_  "GenMsgSendType" "NoMsgSendType";
BA_DEF_DEF_  "GenMsgStartDelayTime" 0;
BA_DEF_DEF_  "NmMessage" "No";
BA_DEF_DEF_  "NmhMessage" "No";
BA_DEF_DEF_  "VAGTP20_API" 0;
BA_DEF_DEF_  "VAGTP20_DynConnection" "No";
BA_DEF_DEF_  "VAGTP20_DynSetup" "No";
BA_DEF_DEF_  "VAGTP20_StatConnection" "No";
BA_DEF_DEF_  "Timeoutzeit" 0;
BA_DEF_DEF_  "DiagRequest" "No";
BA_DEF_DEF_  "DiagResponse" "No";
BA_DEF_DEF_  "DiagState" "No";
BA_DEF_DEF_  "GenMsgChkConstant" 0;
BA_DEF_DEF_  "GenSigAutoGenDsp" "No";
BA_DEF_DEF_  "GenSigAutoGenSnd" "No";
BA_DEF_DEF_  "GenSigEnvVarType" "undef";
BA_DEF_DEF_  "GenSigInactiveValue" 0;
BA_DEF_DEF_  "GenSigSendType" "NoSigSendType";
BA_DEF_DEF_  "GenSigStartValue" 0;
BA_DEF_DEF_  "NWM-WakeupAllowed" "No";
BA_DEF_DEF_  "GenSigFuncType" "NoFunction";
BA_DEF_DEF_  "GenSigSwitchedByIgnition" "Yes";
BA_DEF_DEF_  "Fehlerwert" 0;
BA_DEF_DEF_  "GenSigMissingSourceValue" 0;
BA_ "GenMsgSendType" BO_ 1100 0;
BA_ "GenMsgILSupport" BO_ 1100 1;
BA_ "GenMsgCycleTime" BO_ 1100 20;
BA_ "GenMsgSendType" BO_ 1348 0;
BA_ "GenMsgILSupport" BO_ 1348 1;
BA_ "GenMsgDelayTime" BO_ 1348 10;
BA_ "GenMsgCycleTime" BO_ 1348 100;
BA_ "GenMsgSendType" BO_ 1104 0;
BA_ "GenMsgILSupport" BO_ 1104 1;
BA_ "GenMsgCycleTime" BO_ 1104 10;
BA_ "GenMsgSendType" BO_ 1106 0;
BA_ "GenMsgILSupport" BO_ 1106 1;
BA_ "GenMsgCycleTime" BO_ 1106 20;
BA_ "GenMsgSendType" BO_ 906 0;
BA_ "GenMsgILSupport" BO_ 906 1;
BA_ "GenMsgCycleTime" BO_ 906 20;
BA_ "GenMsgSendType" BO_ 1510 0;
BA_ "GenMsgDelayTime" BO_ 1510 100;
BA_ "GenMsgCycleTime" BO_ 1510 500;
BA_ "GenMsgSendType" BO_ 1529 0;
BA_ "GenMsgILSupport" BO_ 1529 1;
BA_ "GenMsgCycleTime" BO_ 1529 1000;
BA_ "GenMsgSendType" BO_ 1164 0;
BA_ "GenMsgILSupport" BO_ 1164 1;
BA_ "GenMsgCycleTime" BO_ 1164 40;
BA_ "GenMsgSendType" BO_ 210 0;
BA_ "GenMsgILSupport" BO_ 210 1;
BA_ "GenMsgCycleTime" BO_ 210 20;
BA_ "GenMsgSendType" BO_ 1490 0;
BA_ "GenMsgILSupport" BO_ 1490 1;
BA_ "GenMsgCycleTime" BO_ 1490 200;
BA_ "GenMsgSendType" BO_ 1512 0;
BA_ "GenMsgDelayTime" BO_ 1512 100;
BA_ "GenMsgCycleTime" BO_ 1512 500;
BA_ "GenMsgSendType" BO_ 1527 0;
BA_ "GenMsgILSupport" BO_ 1527 1;
BA_ "GenMsgCycleTime" BO_ 1527 500;
BA_ "GenMsgSendType" BO_ 800 0;
BA_ "GenMsgILSupport" BO_ 800 1;
BA_ "GenMsgCycleTimeFast" BO_ 800 20;
BA_ "GenMsgCycleTime" BO_ 800 25;
BA_ "GenMsgSendType" BO_ 1056 0;
BA_ "GenMsgILSupport" BO_ 1056 1;
BA_ "GenMsgCycleTime" BO_ 1056 200;
BA_ "GenMsgSendType" BO_ 1312 0;
BA_ "GenMsgILSupport" BO_ 1312 1;
BA_ "GenMsgCycleTime" BO_ 1312 200;
BA_ "GenMsgSendType" BO_ 1564 0;
BA_ "GenMsgILSupport" BO_ 1564 1;
BA_ "GenMsgCycleTime" BO_ 1564 1000;
BA_ "GenMsgSendType" BO_ 1470 0;
BA_ "GenMsgILSupport" BO_ 1470 1;
BA_ "GenMsgCycleTime" BO_ 1470 50;
BA_ "GenMsgSendType" BO_ 976 0;
BA_ "GenMsgILSupport" BO_ 976 1;
BA_ "GenMsgCycleTime" BO_ 976 20;
BA_ "GenMsgSendType" BO_ 978 0;
BA_ "GenMsgILSupport" BO_ 978 1;
BA_ "GenMsgCycleTime" BO_ 978 50;
BA_ "GenSigSwitchedByIgnition" SG_ 1100 GE6_Checksum 0;
BA_ "GenSigFuncType" SG_ 1100 GE6_Checksum 4;
BA_ "GenSigSendType" SG_ 1100 GE6_Checksum 0;
BA_ "GenSigAutoGenSnd" SG_ 1100 GE6_Checksum 1;
BA_ "GenSigAutoGenDsp" SG_ 1100 GE6_Checksum 1;
BA_ "Fehlerwert" SG_ 1100 GE6_TurbDZ 16383;
BA_ "GenSigStartValue" SG_ 1100 GE6_TurbDZ 16382;
BA_ "GenSigSendType" SG_ 1100 GE6_TurbDZ 0;
BA_ "GenSigAutoGenSnd" SG_ 1100 GE6_TurbDZ 1;
BA_ "GenSigAutoGenDsp" SG_ 1100 GE6_TurbDZ 1;
BA_ "GenSigStartValue" SG_ 1100 GE6_QmaxBeschl 1;
BA_ "GenSigSendType" SG_ 1100 GE6_QmaxBeschl 0;
BA_ "GenSigAutoGenSnd" SG_ 1100 GE6_QmaxBeschl 1;
BA_ "GenSigAutoGenDsp" SG_ 1100 GE6_QmaxBeschl 1;
BA_ "GenSigStartValue" SG_ 1100 GE6_QB_OelTemp 1;
BA_ "GenSigSendType" SG_ 1100 GE6_QB_OelTemp 0;
BA_ "GenSigAutoGenSnd" SG_ 1100 GE6_QB_OelTemp 1;
BA_ "GenSigAutoGenDsp" SG_ 1100 GE6_QB_OelTemp 1;
BA_ "Fehlerwert" SG_ 1100 GE6_OelTemp 255;
BA_ "GenSigSendType" SG_ 1100 GE6_OelTemp 0;
BA_ "GenSigAutoGenSnd" SG_ 1100 GE6_OelTemp 1;
BA_ "GenSigAutoGenDsp" SG_ 1100 GE6_OelTemp 1;
BA_ "Fehlerwert" SG_ 1100 GE6_maxBeschl 255;
BA_ "GenSigStartValue" SG_ 1100 GE6_maxBeschl 88;
BA_ "GenSigSendType" SG_ 1100 GE6_maxBeschl 0;
BA_ "GenSigAutoGenSnd" SG_ 1100 GE6_maxBeschl 1;
BA_ "GenSigAutoGenDsp" SG_ 1100 GE6_maxBeschl 1;
BA_ "GenSigSendType" SG_ 1100 GE6_Gangwechsel 0;
BA_ "GenSigAutoGenSnd" SG_ 1100 GE6_Gangwechsel 1;
BA_ "GenSigAutoGenDsp" SG_ 1100 GE6_Gangwechsel 1;
BA_ "GenSigStartValue" SG_ 1100 GE6_Zielgang_err 1;
BA_ "GenSigSendType" SG_ 1100 GE6_Zielgang_err 0;
BA_ "GenSigAutoGenSnd" SG_ 1100 GE6_Zielgang_err 1;
BA_ "GenSigAutoGenDsp" SG_ 1100 GE6_Zielgang_err 1;
BA_ "GenSigSwitchedByIgnition" SG_ 1100 GE_Heizwunsch 0;
BA_ "GenSigStartValue" SG_ 1100 GE_Heizwunsch 1;
BA_ "GenSigSendType" SG_ 1100 GE_Heizwunsch 0;
BA_ "GenSigAutoGenSnd" SG_ 1100 GE_Heizwunsch 1;
BA_ "GenSigAutoGenDsp" SG_ 1100 GE_Heizwunsch 1;
BA_ "GenSigSendType" SG_ 1100 GE1_StSt_Info 0;
BA_ "GenSigAutoGenSnd" SG_ 1100 GE1_StSt_Info 1;
BA_ "GenSigAutoGenDsp" SG_ 1100 GE1_StSt_Info 1;
BA_ "Fehlerwert" SG_ 1100 GE6_Verlustmom 255;
BA_ "GenSigSendType" SG_ 1100 GE6_Verlustmom 0;
BA_ "GenSigAutoGenSnd" SG_ 1100 GE6_Verlustmom 1;
BA_ "GenSigAutoGenDsp" SG_ 1100 GE6_Verlustmom 1;
BA_ "GenSigSwitchedByIgnition" SG_ 1100 GE6_Zaehler 0;
BA_ "GenSigFuncType" SG_ 1100 GE6_Zaehler 1;
BA_ "GenSigSendType" SG_ 1100 GE6_Zaehler 0;
BA_ "GenSigAutoGenSnd" SG_ 1100 GE6_Zaehler 1;
BA_ "GenSigAutoGenDsp" SG_ 1100 GE6_Zaehler 1;
BA_ "GenSigSendType" SG_ 1348 GE7_Text_01 0;
BA_ "GenSigAutoGenSnd" SG_ 1348 GE7_Text_01 1;
BA_ "GenSigAutoGenDsp" SG_ 1348 GE7_Text_01 1;
BA_ "GenSigSendType" SG_ 1348 GE7_Text_02 0;
BA_ "GenSigAutoGenSnd" SG_ 1348 GE7_Text_02 1;
BA_ "GenSigAutoGenDsp" SG_ 1348 GE7_Text_02 1;
BA_ "GenSigSendType" SG_ 1348 GE7_Text_03 0;
BA_ "GenSigAutoGenSnd" SG_ 1348 GE7_Text_03 1;
BA_ "GenSigAutoGenDsp" SG_ 1348 GE7_Text_03 1;
BA_ "GenSigSendType" SG_ 1348 GE7_Gong 0;
BA_ "GenSigAutoGenSnd" SG_ 1348 GE7_Gong 1;
BA_ "GenSigAutoGenDsp" SG_ 1348 GE7_Gong 1;
BA_ "GenSigSendType" SG_ 1348 GE7_Text_04 0;
BA_ "GenSigAutoGenSnd" SG_ 1348 GE7_Text_04 1;
BA_ "GenSigAutoGenDsp" SG_ 1348 GE7_Text_04 1;
BA_ "GenSigSendType" SG_ 1348 GE7_Text_05 0;
BA_ "GenSigAutoGenSnd" SG_ 1348 GE7_Text_05 1;
BA_ "GenSigAutoGenDsp" SG_ 1348 GE7_Text_05 1;
BA_ "GenSigSendType" SG_ 1348 GE7_Waehlh_ausgef 0;
BA_ "GenSigAutoGenSnd" SG_ 1348 GE7_Waehlh_ausgef 1;
BA_ "GenSigAutoGenDsp" SG_ 1348 GE7_Waehlh_ausgef 1;
BA_ "GenSigSendType" SG_ 1348 GE7_Text_07 0;
BA_ "GenSigAutoGenSnd" SG_ 1348 GE7_Text_07 1;
BA_ "GenSigAutoGenDsp" SG_ 1348 GE7_Text_07 1;
BA_ "GenSigSendType" SG_ 1348 GE7_Feh_1Warn 0;
BA_ "GenSigAutoGenSnd" SG_ 1348 GE7_Feh_1Warn 1;
BA_ "GenSigAutoGenDsp" SG_ 1348 GE7_Feh_1Warn 1;
BA_ "GenSigSendType" SG_ 1348 GE7_Feh_2Warn 0;
BA_ "GenSigAutoGenSnd" SG_ 1348 GE7_Feh_2Warn 1;
BA_ "GenSigAutoGenDsp" SG_ 1348 GE7_Feh_2Warn 1;
BA_ "GenSigSendType" SG_ 1348 GE7_SyncWarn 0;
BA_ "GenSigAutoGenSnd" SG_ 1348 GE7_SyncWarn 1;
BA_ "GenSigAutoGenDsp" SG_ 1348 GE7_SyncWarn 1;
BA_ "GenSigSwitchedByIgnition" SG_ 1348 GE_Segeln_Menueanf 0;
BA_ "GenSigSendType" SG_ 1348 GE_Segeln_Menueanf 0;
BA_ "GenSigSwitchedByIgnition" SG_ 1348 GE_Segeln_Status 0;
BA_ "GenSigSendType" SG_ 1348 GE_Segeln_Status 0;
BA_ "GenSigFuncType" SG_ 1104 GE8_Checksumme 4;
BA_ "GenSigSendType" SG_ 1104 GE8_Checksumme 0;
BA_ "GenSigAutoGenSnd" SG_ 1104 GE8_Checksumme 1;
BA_ "GenSigAutoGenDsp" SG_ 1104 GE8_Checksumme 1;
BA_ "GenSigFuncType" SG_ 1104 GE8_Zaehler 1;
BA_ "GenSigSendType" SG_ 1104 GE8_Zaehler 0;
BA_ "GenSigAutoGenSnd" SG_ 1104 GE8_Zaehler 1;
BA_ "GenSigAutoGenDsp" SG_ 1104 GE8_Zaehler 1;
BA_ "GenSigSendType" SG_ 1104 GE8_Hydr_Pumpe 0;
BA_ "GenSigAutoGenSnd" SG_ 1104 GE8_Hydr_Pumpe 1;
BA_ "GenSigAutoGenDsp" SG_ 1104 GE8_Hydr_Pumpe 1;
BA_ "GenSigSendType" SG_ 1104 GE8_Motor_aus 0;
BA_ "GenSigAutoGenSnd" SG_ 1104 GE8_Motor_aus 1;
BA_ "GenSigAutoGenDsp" SG_ 1104 GE8_Motor_aus 1;
BA_ "GenSigSendType" SG_ 1104 GE8_Anfahrfkt 0;
BA_ "GenSigAutoGenSnd" SG_ 1104 GE8_Anfahrfkt 1;
BA_ "GenSigAutoGenDsp" SG_ 1104 GE8_Anfahrfkt 1;
BA_ "GenSigSendType" SG_ 1104 GE8_SollDZ 0;
BA_ "GenSigAutoGenSnd" SG_ 1104 GE8_SollDZ 1;
BA_ "GenSigAutoGenDsp" SG_ 1104 GE8_SollDZ 1;
BA_ "GenSigSendType" SG_ 1104 GE8_VorsteuerMom 0;
BA_ "GenSigAutoGenSnd" SG_ 1104 GE8_VorsteuerMom 1;
BA_ "GenSigAutoGenDsp" SG_ 1104 GE8_VorsteuerMom 1;
BA_ "GenSigSendType" SG_ 1104 GE8_KuppMom 0;
BA_ "GenSigAutoGenSnd" SG_ 1104 GE8_KuppMom 1;
BA_ "GenSigAutoGenDsp" SG_ 1104 GE8_KuppMom 1;
BA_ "GenSigSwitchedByIgnition" SG_ 1106 GH1_Zaehler 0;
BA_ "GenSigFuncType" SG_ 1106 GH1_Zaehler 1;
BA_ "GenSigSendType" SG_ 1106 GH1_Zaehler 0;
BA_ "GenSigAutoGenSnd" SG_ 1106 GH1_Zaehler 1;
BA_ "GenSigAutoGenDsp" SG_ 1106 GH1_Zaehler 1;
BA_ "GenSigSwitchedByIgnition" SG_ 1106 GH1_FreigabeK0 0;
BA_ "GenSigSendType" SG_ 1106 GH1_FreigabeK0 0;
BA_ "GenSigAutoGenSnd" SG_ 1106 GH1_FreigabeK0 1;
BA_ "GenSigAutoGenDsp" SG_ 1106 GH1_FreigabeK0 1;
BA_ "GenSigSwitchedByIgnition" SG_ 1106 GH1_FreigabeVMStop 0;
BA_ "GenSigSendType" SG_ 1106 GH1_FreigabeVMStop 0;
BA_ "GenSigAutoGenSnd" SG_ 1106 GH1_FreigabeVMStop 1;
BA_ "GenSigAutoGenDsp" SG_ 1106 GH1_FreigabeVMStop 1;
BA_ "GenSigSwitchedByIgnition" SG_ 1106 GH1_FehlerstatusGSG 0;
BA_ "GenSigSendType" SG_ 1106 GH1_FehlerstatusGSG 0;
BA_ "GenSigAutoGenSnd" SG_ 1106 GH1_FehlerstatusGSG 1;
BA_ "GenSigAutoGenDsp" SG_ 1106 GH1_FehlerstatusGSG 1;
BA_ "Fehlerwert" SG_ 1106 GH1_nK0 255;
BA_ "GenSigSwitchedByIgnition" SG_ 1106 GH1_nK0 0;
BA_ "GenSigSendType" SG_ 1106 GH1_nK0 0;
BA_ "GenSigAutoGenSnd" SG_ 1106 GH1_nK0 1;
BA_ "GenSigAutoGenDsp" SG_ 1106 GH1_nK0 1;
BA_ "GenSigSwitchedByIgnition" SG_ 1106 GH1_VZMomEingriff 0;
BA_ "GenSigSendType" SG_ 1106 GH1_VZMomEingriff 0;
BA_ "GenSigAutoGenSnd" SG_ 1106 GH1_VZMomEingriff 1;
BA_ "GenSigAutoGenDsp" SG_ 1106 GH1_VZMomEingriff 1;
BA_ "GenSigSwitchedByIgnition" SG_ 1106 GH1_MomEingriff_EM 0;
BA_ "GenSigSendType" SG_ 1106 GH1_MomEingriff_EM 0;
BA_ "GenSigAutoGenSnd" SG_ 1106 GH1_MomEingriff_EM 1;
BA_ "GenSigAutoGenDsp" SG_ 1106 GH1_MomEingriff_EM 1;
BA_ "GenSigSwitchedByIgnition" SG_ 1106 GH1_Wiederstart 0;
BA_ "GenSigSendType" SG_ 1106 GH1_Wiederstart 0;
BA_ "GenSigAutoGenSnd" SG_ 1106 GH1_Wiederstart 1;
BA_ "GenSigAutoGenDsp" SG_ 1106 GH1_Wiederstart 1;
BA_ "GenSigSwitchedByIgnition" SG_ 1106 GH1_VM_akt_halten 0;
BA_ "GenSigSendType" SG_ 1106 GH1_VM_akt_halten 0;
BA_ "GenSigAutoGenSnd" SG_ 1106 GH1_VM_akt_halten 1;
BA_ "GenSigAutoGenDsp" SG_ 1106 GH1_VM_akt_halten 1;
BA_ "GenSigSwitchedByIgnition" SG_ 1106 GH1_Sportfaktor 0;
BA_ "GenSigSendType" SG_ 1106 GH1_Sportfaktor 0;
BA_ "GenSigAutoGenSnd" SG_ 1106 GH1_Sportfaktor 1;
BA_ "GenSigAutoGenDsp" SG_ 1106 GH1_Sportfaktor 1;
BA_ "GenSigSwitchedByIgnition" SG_ 1106 GH1_Freig_LL_Reg 0;
BA_ "GenSigStartValue" SG_ 1106 GH1_Freig_LL_Reg 1;
BA_ "GenSigSendType" SG_ 1106 GH1_Freig_LL_Reg 0;
BA_ "GenSigAutoGenSnd" SG_ 1106 GH1_Freig_LL_Reg 1;
BA_ "GenSigAutoGenDsp" SG_ 1106 GH1_Freig_LL_Reg 1;
BA_ "GenSigSwitchedByIgnition" SG_ 1106 GH1_VKM_StAnf 0;
BA_ "GenSigSendType" SG_ 1106 GH1_VKM_StAnf 0;
BA_ "GenSigAutoGenSnd" SG_ 1106 GH1_VKM_StAnf 1;
BA_ "GenSigAutoGenDsp" SG_ 1106 GH1_VKM_StAnf 1;
BA_ "GenSigSwitchedByIgnition" SG_ 1106 GH1_VKM_StKontr 0;
BA_ "GenSigSendType" SG_ 1106 GH1_VKM_StKontr 0;
BA_ "GenSigAutoGenSnd" SG_ 1106 GH1_VKM_StKontr 1;
BA_ "GenSigAutoGenDsp" SG_ 1106 GH1_VKM_StKontr 1;
BA_ "Fehlerwert" SG_ 1106 GH1_AnzeigeDZ 4095;
BA_ "GenSigSwitchedByIgnition" SG_ 1106 GH1_AnzeigeDZ 0;
BA_ "GenSigSendType" SG_ 1106 GH1_AnzeigeDZ 0;
BA_ "GenSigAutoGenSnd" SG_ 1106 GH1_AnzeigeDZ 1;
BA_ "GenSigAutoGenDsp" SG_ 1106 GH1_AnzeigeDZ 1;
BA_ "GenSigSwitchedByIgnition" SG_ 1106 GH1_Filt_MomAufbau 0;
BA_ "GenSigSendType" SG_ 1106 GH1_Filt_MomAufbau 0;
BA_ "GenSigAutoGenSnd" SG_ 1106 GH1_Filt_MomAufbau 1;
BA_ "GenSigAutoGenDsp" SG_ 1106 GH1_Filt_MomAufbau 1;
BA_ "GenSigSwitchedByIgnition" SG_ 1106 GE_Freigabe_Verfallsinfo_WFS 0;
BA_ "GenSigSendType" SG_ 1106 GE_Freigabe_Verfallsinfo_WFS 0;
BA_ "GenSigSwitchedByIgnition" SG_ 906 GRA_Checksum 0;
BA_ "GenSigFuncType" SG_ 906 GRA_Checksum 4;
BA_ "GenSigSendType" SG_ 906 GRA_Checksum 0;
BA_ "GenSigAutoGenSnd" SG_ 906 GRA_Checksum 1;
BA_ "GenSigAutoGenDsp" SG_ 906 GRA_Checksum 1;
BA_ "GenSigSwitchedByIgnition" SG_ 906 GRA_Hauptschalt 0;
BA_ "GenSigSendType" SG_ 906 GRA_Hauptschalt 0;
BA_ "GenSigAutoGenSnd" SG_ 906 GRA_Hauptschalt 1;
BA_ "GenSigAutoGenDsp" SG_ 906 GRA_Hauptschalt 1;
BA_ "GenSigSwitchedByIgnition" SG_ 906 GRA_Abbrechen 0;
BA_ "GenSigSendType" SG_ 906 GRA_Abbrechen 0;
BA_ "GenSigAutoGenSnd" SG_ 906 GRA_Abbrechen 1;
BA_ "GenSigAutoGenDsp" SG_ 906 GRA_Abbrechen 1;
BA_ "GenSigSwitchedByIgnition" SG_ 906 GRA_Down_kurz 0;
BA_ "GenSigSendType" SG_ 906 GRA_Down_kurz 0;
BA_ "GenSigAutoGenSnd" SG_ 906 GRA_Down_kurz 1;
BA_ "GenSigAutoGenDsp" SG_ 906 GRA_Down_kurz 1;
BA_ "GenSigSwitchedByIgnition" SG_ 906 GRA_Up_kurz 0;
BA_ "GenSigSendType" SG_ 906 GRA_Up_kurz 0;
BA_ "GenSigAutoGenSnd" SG_ 906 GRA_Up_kurz 1;
BA_ "GenSigAutoGenDsp" SG_ 906 GRA_Up_kurz 1;
BA_ "GenSigSwitchedByIgnition" SG_ 906 GRA_Down_lang 0;
BA_ "GenSigSendType" SG_ 906 GRA_Down_lang 0;
BA_ "GenSigAutoGenSnd" SG_ 906 GRA_Down_lang 1;
BA_ "GenSigAutoGenDsp" SG_ 906 GRA_Down_lang 1;
BA_ "GenSigSwitchedByIgnition" SG_ 906 GRA_Up_lang 0;
BA_ "GenSigSendType" SG_ 906 GRA_Up_lang 0;
BA_ "GenSigAutoGenSnd" SG_ 906 GRA_Up_lang 1;
BA_ "GenSigAutoGenDsp" SG_ 906 GRA_Up_lang 1;
BA_ "GenSigSwitchedByIgnition" SG_ 906 GRA_Fehler_Bed 0;
BA_ "GenSigSendType" SG_ 906 GRA_Fehler_Bed 0;
BA_ "GenSigAutoGenSnd" SG_ 906 GRA_Fehler_Bed 1;
BA_ "GenSigAutoGenDsp" SG_ 906 GRA_Fehler_Bed 1;
BA_ "GenSigSwitchedByIgnition" SG_ 906 GRA_Kodierinfo 0;
BA_ "GenSigSendType" SG_ 906 GRA_Kodierinfo 0;
BA_ "GenSigAutoGenSnd" SG_ 906 GRA_Kodierinfo 1;
BA_ "GenSigAutoGenDsp" SG_ 906 GRA_Kodierinfo 1;
BA_ "GenSigSwitchedByIgnition" SG_ 906 GRA_Neu_Setzen 0;
BA_ "GenSigSendType" SG_ 906 GRA_Neu_Setzen 0;
BA_ "GenSigAutoGenSnd" SG_ 906 GRA_Neu_Setzen 1;
BA_ "GenSigAutoGenDsp" SG_ 906 GRA_Neu_Setzen 1;
BA_ "GenSigSwitchedByIgnition" SG_ 906 GRA_Recall 0;
BA_ "GenSigSendType" SG_ 906 GRA_Recall 0;
BA_ "GenSigAutoGenSnd" SG_ 906 GRA_Recall 1;
BA_ "GenSigAutoGenDsp" SG_ 906 GRA_Recall 1;
BA_ "GenSigSwitchedByIgnition" SG_ 906 GRA_Sender 0;
BA_ "GenSigSendType" SG_ 906 GRA_Sender 0;
BA_ "GenSigAutoGenSnd" SG_ 906 GRA_Sender 1;
BA_ "GenSigAutoGenDsp" SG_ 906 GRA_Sender 1;
BA_ "GenSigSwitchedByIgnition" SG_ 906 GRA_Neu_Zaehler 0;
BA_ "GenSigFuncType" SG_ 906 GRA_Neu_Zaehler 1;
BA_ "GenSigSendType" SG_ 906 GRA_Neu_Zaehler 0;
BA_ "GenSigAutoGenSnd" SG_ 906 GRA_Neu_Zaehler 1;
BA_ "GenSigAutoGenDsp" SG_ 906 GRA_Neu_Zaehler 1;
BA_ "GenSigSwitchedByIgnition" SG_ 906 GRA_Tip_Down 0;
BA_ "GenSigSendType" SG_ 906 GRA_Tip_Down 0;
BA_ "GenSigAutoGenSnd" SG_ 906 GRA_Tip_Down 1;
BA_ "GenSigAutoGenDsp" SG_ 906 GRA_Tip_Down 1;
BA_ "GenSigSwitchedByIgnition" SG_ 906 GRA_Tip_Up 0;
BA_ "GenSigSendType" SG_ 906 GRA_Tip_Up 0;
BA_ "GenSigAutoGenSnd" SG_ 906 GRA_Tip_Up 1;
BA_ "GenSigAutoGenDsp" SG_ 906 GRA_Tip_Up 1;
BA_ "GenSigSwitchedByIgnition" SG_ 906 GRA_Zeitluecke 0;
BA_ "GenSigSendType" SG_ 906 GRA_Zeitluecke 0;
BA_ "GenSigAutoGenSnd" SG_ 906 GRA_Zeitluecke 1;
BA_ "GenSigAutoGenDsp" SG_ 906 GRA_Zeitluecke 1;
BA_ "GenSigSwitchedByIgnition" SG_ 906 GRA_Sta_Limiter 0;
BA_ "GenSigSendType" SG_ 906 GRA_Sta_Limiter 0;
BA_ "GenSigAutoGenSnd" SG_ 906 GRA_Sta_Limiter 1;
BA_ "GenSigAutoGenDsp" SG_ 906 GRA_Sta_Limiter 1;
BA_ "GenSigSwitchedByIgnition" SG_ 906 GRA_Typ_Hauptschalt 0;
BA_ "GenSigSendType" SG_ 906 GRA_Typ_Hauptschalt 0;
BA_ "GenSigAutoGenSnd" SG_ 906 GRA_Typ_Hauptschalt 1;
BA_ "GenSigAutoGenDsp" SG_ 906 GRA_Typ_Hauptschalt 1;
BA_ "GenSigSwitchedByIgnition" SG_ 906 GRA_Sportschalter 0;
BA_ "GenSigSendType" SG_ 906 GRA_Sportschalter 0;
BA_ "GenSigAutoGenSnd" SG_ 906 GRA_Sportschalter 1;
BA_ "GenSigAutoGenDsp" SG_ 906 GRA_Sportschalter 1;
BA_ "GenSigSwitchedByIgnition" SG_ 906 GRA_Fehler_Tip 0;
BA_ "GenSigSendType" SG_ 906 GRA_Fehler_Tip 0;
BA_ "GenSigAutoGenSnd" SG_ 906 GRA_Fehler_Tip 1;
BA_ "GenSigAutoGenDsp" SG_ 906 GRA_Fehler_Tip 1;
BA_ "GenSigSwitchedByIgnition" SG_ 1510 Weckzeit_EV_erreicht 0;
BA_ "GenSigSendType" SG_ 1510 Weckzeit_EV_erreicht 3;
BA_ "GenSigSwitchedByIgnition" SG_ 1510 GSM_MaxLeistung_NT 0;
BA_ "GenSigSendType" SG_ 1510 GSM_MaxLeistung_NT 0;
BA_ "GenSigSwitchedByIgnition" SG_ 1510 Standklimatisierung_Anf 0;
BA_ "GenSigSendType" SG_ 1510 Standklimatisierung_Anf 3;
BA_ "GenSigSwitchedByIgnition" SG_ 1510 Ladevorgang_Anf 0;
BA_ "GenSigSendType" SG_ 1510 Ladevorgang_Anf 3;
BA_ "GenSigSwitchedByIgnition" SG_ 1510 GSM_Wake_Up_ACAN 0;
BA_ "GenSigSendType" SG_ 1510 GSM_Wake_Up_ACAN 3;
BA_ "GenSigAutoGenSnd" SG_ 1510 GSM_Wake_Up_ACAN 1;
BA_ "GenSigAutoGenDsp" SG_ 1510 GSM_Wake_Up_ACAN 1;
BA_ "GenSigSwitchedByIgnition" SG_ 1510 Standklima_Temp_Vorwahl 0;
BA_ "GenSigSendType" SG_ 1510 Standklima_Temp_Vorwahl 0;
BA_ "GenSigSwitchedByIgnition" SG_ 1510 Ladestrom_max 0;
BA_ "GenSigSendType" SG_ 1510 Ladestrom_max 0;
BA_ "GenSigSwitchedByIgnition" SG_ 1510 GSM_Zeit_Typ 0;
BA_ "GenSigSendType" SG_ 1510 GSM_Zeit_Typ 0;
BA_ "GenSigAutoGenSnd" SG_ 1510 GSM_Zeit_Typ 1;
BA_ "GenSigAutoGenDsp" SG_ 1510 GSM_Zeit_Typ 1;
BA_ "GenSigSwitchedByIgnition" SG_ 1510 GSM_Jahr 0;
BA_ "GenSigSendType" SG_ 1510 GSM_Jahr 0;
BA_ "GenSigAutoGenSnd" SG_ 1510 GSM_Jahr 1;
BA_ "GenSigAutoGenDsp" SG_ 1510 GSM_Jahr 1;
BA_ "GenSigSwitchedByIgnition" SG_ 1510 GSM_Monat 0;
BA_ "GenSigSendType" SG_ 1510 GSM_Monat 0;
BA_ "GenSigAutoGenSnd" SG_ 1510 GSM_Monat 1;
BA_ "GenSigAutoGenDsp" SG_ 1510 GSM_Monat 1;
BA_ "GenSigSwitchedByIgnition" SG_ 1510 GSM_Tag 0;
BA_ "GenSigSendType" SG_ 1510 GSM_Tag 0;
BA_ "GenSigAutoGenSnd" SG_ 1510 GSM_Tag 1;
BA_ "GenSigAutoGenDsp" SG_ 1510 GSM_Tag 1;
BA_ "GenSigSwitchedByIgnition" SG_ 1510 GSM_Stunde 0;
BA_ "GenSigSendType" SG_ 1510 GSM_Stunde 0;
BA_ "GenSigAutoGenSnd" SG_ 1510 GSM_Stunde 1;
BA_ "GenSigAutoGenDsp" SG_ 1510 GSM_Stunde 1;
BA_ "GenSigSwitchedByIgnition" SG_ 1510 GSM_Minute 0;
BA_ "GenSigSendType" SG_ 1510 GSM_Minute 0;
BA_ "GenSigAutoGenSnd" SG_ 1510 GSM_Minute 1;
BA_ "GenSigAutoGenDsp" SG_ 1510 GSM_Minute 1;
BA_ "GenSigSwitchedByIgnition" SG_ 1510 GSM_Ladestecker_Anf 0;
BA_ "GenSigSendType" SG_ 1510 GSM_Ladestecker_Anf 3;
BA_ "GenSigSwitchedByIgnition" SG_ 1510 GSM_SOC_Untergrenze 0;
BA_ "GenSigStartValue" SG_ 1510 GSM_SOC_Untergrenze 14;
BA_ "GenSigSendType" SG_ 1510 GSM_SOC_Untergrenze 0;
BA_ "GenSigSwitchedByIgnition" SG_ 1510 GSM_SOC_Obergrenze 0;
BA_ "GenSigStartValue" SG_ 1510 GSM_SOC_Obergrenze 14;
BA_ "GenSigSendType" SG_ 1510 GSM_SOC_Obergrenze 0;
BA_ "Fehlerwert" SG_ 1529 GM_KD_Fehler 1;
BA_ "GenSigSendType" SG_ 1529 GM_KD_Fehler 0;
BA_ "GenSigAutoGenSnd" SG_ 1529 GM_KD_Fehler 1;
BA_ "GenSigAutoGenDsp" SG_ 1529 GM_KD_Fehler 1;
BA_ "GenSigSwitchedByIgnition" SG_ 1164 HS1_Checksumme 0;
BA_ "GenSigFuncType" SG_ 1164 HS1_Checksumme 4;
BA_ "GenSigSendType" SG_ 1164 HS1_Checksumme 0;
BA_ "GenSigAutoGenSnd" SG_ 1164 HS1_Checksumme 1;
BA_ "GenSigAutoGenDsp" SG_ 1164 HS1_Checksumme 1;
BA_ "GenSigSwitchedByIgnition" SG_ 1164 HS1_Zaehler 0;
BA_ "GenSigFuncType" SG_ 1164 HS1_Zaehler 1;
BA_ "GenSigSendType" SG_ 1164 HS1_Zaehler 0;
BA_ "GenSigAutoGenSnd" SG_ 1164 HS1_Zaehler 1;
BA_ "GenSigAutoGenDsp" SG_ 1164 HS1_Zaehler 1;
BA_ "GenSigSwitchedByIgnition" SG_ 1164 HS1_Drehz_Grenze 0;
BA_ "GenSigStartValue" SG_ 1164 HS1_Drehz_Grenze 1;
BA_ "GenSigSendType" SG_ 1164 HS1_Drehz_Grenze 0;
BA_ "GenSigAutoGenSnd" SG_ 1164 HS1_Drehz_Grenze 1;
BA_ "GenSigAutoGenDsp" SG_ 1164 HS1_Drehz_Grenze 1;
BA_ "GenSigSwitchedByIgnition" SG_ 1164 HS1_Gang 0;
BA_ "GenSigStartValue" SG_ 1164 HS1_Gang 7;
BA_ "GenSigSendType" SG_ 1164 HS1_Gang 0;
BA_ "GenSigAutoGenSnd" SG_ 1164 HS1_Gang 1;
BA_ "GenSigAutoGenDsp" SG_ 1164 HS1_Gang 1;
BA_ "GenSigFuncType" SG_ 210 HC1_Checksumme 4;
BA_ "GenSigSendType" SG_ 210 HC1_Checksumme 0;
BA_ "GenSigAutoGenSnd" SG_ 210 HC1_Checksumme 1;
BA_ "GenSigAutoGenDsp" SG_ 210 HC1_Checksumme 1;
BA_ "GenSigFuncType" SG_ 210 HC1_Zaehler 1;
BA_ "GenSigSendType" SG_ 210 HC1_Zaehler 0;
BA_ "GenSigAutoGenSnd" SG_ 210 HC1_Zaehler 1;
BA_ "GenSigAutoGenDsp" SG_ 210 HC1_Zaehler 1;
BA_ "GenSigSendType" SG_ 210 HC1_Sta_HCA 0;
BA_ "GenSigAutoGenSnd" SG_ 210 HC1_Sta_HCA 1;
BA_ "GenSigAutoGenDsp" SG_ 210 HC1_Sta_HCA 1;
BA_ "GenSigSendType" SG_ 210 HC1_LM_Offset 0;
BA_ "GenSigAutoGenSnd" SG_ 210 HC1_LM_Offset 1;
BA_ "GenSigAutoGenDsp" SG_ 210 HC1_LM_Offset 1;
BA_ "GenSigSendType" SG_ 210 HC1_LM_Offset_Sign 0;
BA_ "GenSigAutoGenSnd" SG_ 210 HC1_LM_Offset_Sign 1;
BA_ "GenSigAutoGenDsp" SG_ 210 HC1_LM_Offset_Sign 1;
BA_ "GenSigSendType" SG_ 210 HC1_Frequenz 0;
BA_ "GenSigAutoGenSnd" SG_ 210 HC1_Frequenz 1;
BA_ "GenSigAutoGenDsp" SG_ 210 HC1_Frequenz 1;
BA_ "GenSigSendType" SG_ 210 HC1_Amplitude 0;
BA_ "GenSigAutoGenSnd" SG_ 210 HC1_Amplitude 1;
BA_ "GenSigAutoGenDsp" SG_ 210 HC1_Amplitude 1;
BA_ "GenSigSwitchedByIgnition" SG_ 1490 IDT_Mux 0;
BA_ "GenSigSendType" SG_ 1490 IDT_Mux 0;
BA_ "GenSigAutoGenSnd" SG_ 1490 IDT_Mux 1;
BA_ "GenSigAutoGenDsp" SG_ 1490 IDT_Mux 1;
BA_ "GenSigSwitchedByIgnition" SG_ 1490 IDT_Geheimnis_1 0;
BA_ "GenSigAutoGenSnd" SG_ 1490 IDT_Geheimnis_1 1;
BA_ "GenSigAutoGenDsp" SG_ 1490 IDT_Geheimnis_1 1;
BA_ "GenSigSwitchedByIgnition" SG_ 1490 IDT_VIN_4 0;
BA_ "GenSigStartValue" SG_ 1490 IDT_VIN_4 88;
BA_ "GenSigAutoGenSnd" SG_ 1490 IDT_VIN_4 1;
BA_ "GenSigAutoGenDsp" SG_ 1490 IDT_VIN_4 1;
BA_ "GenSigSwitchedByIgnition" SG_ 1490 IDT_VIN_11 0;
BA_ "GenSigStartValue" SG_ 1490 IDT_VIN_11 88;
BA_ "GenSigAutoGenSnd" SG_ 1490 IDT_VIN_11 1;
BA_ "GenSigAutoGenDsp" SG_ 1490 IDT_VIN_11 1;
BA_ "GenSigSwitchedByIgnition" SG_ 1490 IDT_Geheimnis_2 0;
BA_ "GenSigAutoGenSnd" SG_ 1490 IDT_Geheimnis_2 1;
BA_ "GenSigAutoGenDsp" SG_ 1490 IDT_Geheimnis_2 1;
BA_ "GenSigSwitchedByIgnition" SG_ 1490 IDT_VIN_5 0;
BA_ "GenSigStartValue" SG_ 1490 IDT_VIN_5 88;
BA_ "GenSigAutoGenSnd" SG_ 1490 IDT_VIN_5 1;
BA_ "GenSigAutoGenDsp" SG_ 1490 IDT_VIN_5 1;
BA_ "GenSigSwitchedByIgnition" SG_ 1490 IDT_VIN_12 0;
BA_ "GenSigStartValue" SG_ 1490 IDT_VIN_12 88;
BA_ "GenSigAutoGenSnd" SG_ 1490 IDT_VIN_12 1;
BA_ "GenSigAutoGenDsp" SG_ 1490 IDT_VIN_12 1;
BA_ "GenSigSwitchedByIgnition" SG_ 1490 IDT_Geheimnis_3 0;
BA_ "GenSigAutoGenSnd" SG_ 1490 IDT_Geheimnis_3 1;
BA_ "GenSigAutoGenDsp" SG_ 1490 IDT_Geheimnis_3 1;
BA_ "GenSigSwitchedByIgnition" SG_ 1490 IDT_VIN_6 0;
BA_ "GenSigStartValue" SG_ 1490 IDT_VIN_6 88;
BA_ "GenSigAutoGenSnd" SG_ 1490 IDT_VIN_6 1;
BA_ "GenSigAutoGenDsp" SG_ 1490 IDT_VIN_6 1;
BA_ "GenSigSwitchedByIgnition" SG_ 1490 IDT_VIN_13 0;
BA_ "GenSigStartValue" SG_ 1490 IDT_VIN_13 88;
BA_ "GenSigAutoGenSnd" SG_ 1490 IDT_VIN_13 1;
BA_ "GenSigAutoGenDsp" SG_ 1490 IDT_VIN_13 1;
BA_ "GenSigSwitchedByIgnition" SG_ 1490 IDT_Geheimnis_4 0;
BA_ "GenSigAutoGenSnd" SG_ 1490 IDT_Geheimnis_4 1;
BA_ "GenSigAutoGenDsp" SG_ 1490 IDT_Geheimnis_4 1;
BA_ "GenSigSwitchedByIgnition" SG_ 1490 IDT_VIN_7 0;
BA_ "GenSigStartValue" SG_ 1490 IDT_VIN_7 88;
BA_ "GenSigAutoGenSnd" SG_ 1490 IDT_VIN_7 1;
BA_ "GenSigAutoGenDsp" SG_ 1490 IDT_VIN_7 1;
BA_ "GenSigSwitchedByIgnition" SG_ 1490 IDT_VIN_14 0;
BA_ "GenSigStartValue" SG_ 1490 IDT_VIN_14 88;
BA_ "GenSigAutoGenSnd" SG_ 1490 IDT_VIN_14 1;
BA_ "GenSigAutoGenDsp" SG_ 1490 IDT_VIN_14 1;
BA_ "GenSigSwitchedByIgnition" SG_ 1490 IDT_VIN_1 0;
BA_ "GenSigStartValue" SG_ 1490 IDT_VIN_1 88;
BA_ "GenSigAutoGenSnd" SG_ 1490 IDT_VIN_1 1;
BA_ "GenSigAutoGenDsp" SG_ 1490 IDT_VIN_1 1;
BA_ "GenSigSwitchedByIgnition" SG_ 1490 IDT_VIN_8 0;
BA_ "GenSigStartValue" SG_ 1490 IDT_VIN_8 88;
BA_ "GenSigAutoGenSnd" SG_ 1490 IDT_VIN_8 1;
BA_ "GenSigAutoGenDsp" SG_ 1490 IDT_VIN_8 1;
BA_ "GenSigSwitchedByIgnition" SG_ 1490 IDT_VIN_15 0;
BA_ "GenSigStartValue" SG_ 1490 IDT_VIN_15 88;
BA_ "GenSigAutoGenSnd" SG_ 1490 IDT_VIN_15 1;
BA_ "GenSigAutoGenDsp" SG_ 1490 IDT_VIN_15 1;
BA_ "GenSigSwitchedByIgnition" SG_ 1490 IDT_VIN_2 0;
BA_ "GenSigStartValue" SG_ 1490 IDT_VIN_2 88;
BA_ "GenSigAutoGenSnd" SG_ 1490 IDT_VIN_2 1;
BA_ "GenSigAutoGenDsp" SG_ 1490 IDT_VIN_2 1;
BA_ "GenSigSwitchedByIgnition" SG_ 1490 IDT_VIN_9 0;
BA_ "GenSigStartValue" SG_ 1490 IDT_VIN_9 88;
BA_ "GenSigAutoGenSnd" SG_ 1490 IDT_VIN_9 1;
BA_ "GenSigAutoGenDsp" SG_ 1490 IDT_VIN_9 1;
BA_ "GenSigSwitchedByIgnition" SG_ 1490 IDT_VIN_16 0;
BA_ "GenSigStartValue" SG_ 1490 IDT_VIN_16 88;
BA_ "GenSigAutoGenSnd" SG_ 1490 IDT_VIN_16 1;
BA_ "GenSigAutoGenDsp" SG_ 1490 IDT_VIN_16 1;
BA_ "GenSigSwitchedByIgnition" SG_ 1490 IDT_VIN_3 0;
BA_ "GenSigStartValue" SG_ 1490 IDT_VIN_3 88;
BA_ "GenSigAutoGenSnd" SG_ 1490 IDT_VIN_3 1;
BA_ "GenSigAutoGenDsp" SG_ 1490 IDT_VIN_3 1;
BA_ "GenSigSwitchedByIgnition" SG_ 1490 IDT_VIN_10 0;
BA_ "GenSigStartValue" SG_ 1490 IDT_VIN_10 88;
BA_ "GenSigAutoGenSnd" SG_ 1490 IDT_VIN_10 1;
BA_ "GenSigAutoGenDsp" SG_ 1490 IDT_VIN_10 1;
BA_ "GenSigSwitchedByIgnition" SG_ 1490 IDT_VIN_17 0;
BA_ "GenSigStartValue" SG_ 1490 IDT_VIN_17 88;
BA_ "GenSigAutoGenSnd" SG_ 1490 IDT_VIN_17 1;
BA_ "GenSigAutoGenDsp" SG_ 1490 IDT_VIN_17 1;
BA_ "GenSigSwitchedByIgnition" SG_ 1512 KL_HV_ein 0;
BA_ "GenSigSendType" SG_ 1512 KL_HV_ein 0;
BA_ "GenSigSwitchedByIgnition" SG_ 1512 KL_Innengeblaese 0;
BA_ "GenSigSendType" SG_ 1512 KL_Innengeblaese 0;
BA_ "GenSigSwitchedByIgnition" SG_ 1512 KL_PTC_Soll 0;
BA_ "GenSigSendType" SG_ 1512 KL_PTC_Soll 0;
BA_ "GenSigSwitchedByIgnition" SG_ 1512 KL_Wake_Up_ACAN 0;
BA_ "GenSigSendType" SG_ 1512 KL_Wake_Up_ACAN 3;
BA_ "GenSigAutoGenSnd" SG_ 1512 KL_Wake_Up_ACAN 1;
BA_ "GenSigAutoGenDsp" SG_ 1512 KL_Wake_Up_ACAN 1;
BA_ "GenSigSwitchedByIgnition" SG_ 1512 KL_HV_Anf 0;
BA_ "GenSigSendType" SG_ 1512 KL_HV_Anf 0;
BA_ "GenSigSwitchedByIgnition" SG_ 1512 KL_Ventil_Batterie_Anf 0;
BA_ "GenSigSendType" SG_ 1512 KL_Ventil_Batterie_Anf 0;
BA_ "GenSigSwitchedByIgnition" SG_ 1512 KL_Ventil_vor_Motor_Anf 0;
BA_ "GenSigSendType" SG_ 1512 KL_Ventil_vor_Motor_Anf 0;
BA_ "GenSigSwitchedByIgnition" SG_ 1512 PTC_Strom 0;
BA_ "GenSigStartValue" SG_ 1512 PTC_Strom 255;
BA_ "GenSigSendType" SG_ 1512 PTC_Strom 0;
BA_ "GenSigAutoGenSnd" SG_ 1512 PTC_Strom 1;
BA_ "GenSigAutoGenDsp" SG_ 1512 PTC_Strom 1;
BA_ "GenSigSwitchedByIgnition" SG_ 1512 EKK_Strom 0;
BA_ "GenSigStartValue" SG_ 1512 EKK_Strom 255;
BA_ "GenSigSendType" SG_ 1512 EKK_Strom 0;
BA_ "GenSigAutoGenSnd" SG_ 1512 EKK_Strom 1;
BA_ "GenSigAutoGenDsp" SG_ 1512 EKK_Strom 1;
BA_ "GenSigSwitchedByIgnition" SG_ 1512 KL_Kompr_Drehzahl_Soll 0;
BA_ "GenSigSendType" SG_ 1512 KL_Kompr_Drehzahl_Soll 0;
BA_ "GenSigSwitchedByIgnition" SG_ 1512 EKK_Status 0;
BA_ "GenSigSendType" SG_ 1512 EKK_Status 0;
BA_ "GenSigSwitchedByIgnition" SG_ 1512 KL_Standklima_Status 0;
BA_ "GenSigSendType" SG_ 1512 KL_Standklima_Status 3;
BA_ "GenSigSwitchedByIgnition" SG_ 1512 PTC_Pumpe_Ist 0;
BA_ "GenSigSendType" SG_ 1512 PTC_Pumpe_Ist 0;
BA_ "GenSigSwitchedByIgnition" SG_ 1512 PTC_Pumpe_Status 0;
BA_ "GenSigSendType" SG_ 1512 PTC_Pumpe_Status 0;
BA_ "GenSigSwitchedByIgnition" SG_ 1512 KL_Charisma_FahrPr 0;
BA_ "GenSigSendType" SG_ 1512 KL_Charisma_FahrPr 3;
BA_ "GenSigEnvVarType" SG_ 1512 KL_Charisma_FahrPr 0;
BA_ "GenSigAutoGenSnd" SG_ 1512 KL_Charisma_FahrPr 1;
BA_ "GenSigAutoGenDsp" SG_ 1512 KL_Charisma_FahrPr 1;
BA_ "GenSigSwitchedByIgnition" SG_ 1512 KL_Charisma_Status 0;
BA_ "GenSigSendType" SG_ 1512 KL_Charisma_Status 3;
BA_ "GenSigEnvVarType" SG_ 1512 KL_Charisma_Status 0;
BA_ "GenSigAutoGenSnd" SG_ 1512 KL_Charisma_Status 1;
BA_ "GenSigAutoGenDsp" SG_ 1512 KL_Charisma_Status 1;
BA_ "GenSigSwitchedByIgnition" SG_ 1512 EKK_Status_Vorstrg 0;
BA_ "GenSigSendType" SG_ 1512 EKK_Status_Vorstrg 3;
BA_ "GenSigAutoGenSnd" SG_ 1512 EKK_Status_Vorstrg 1;
BA_ "GenSigAutoGenDsp" SG_ 1512 EKK_Status_Vorstrg 1;
BA_ "Fehlerwert" SG_ 1512 KL_Standklima_Strg_Kluefter 255;
BA_ "GenSigSwitchedByIgnition" SG_ 1512 KL_Standklima_Strg_Kluefter 0;
BA_ "GenSigSendType" SG_ 1512 KL_Standklima_Strg_Kluefter 0;
BA_ "GenSigAutoGenSnd" SG_ 1512 KL_Standklima_Strg_Kluefter 1;
BA_ "GenSigAutoGenDsp" SG_ 1512 KL_Standklima_Strg_Kluefter 1;
BA_ "GenSigSwitchedByIgnition" SG_ 1527 KE1_Comp_enable 0;
BA_ "GenSigSendType" SG_ 1527 KE1_Comp_enable 0;
BA_ "GenSigAutoGenSnd" SG_ 1527 KE1_Comp_enable 1;
BA_ "GenSigAutoGenDsp" SG_ 1527 KE1_Comp_enable 1;
BA_ "GenSigSwitchedByIgnition" SG_ 1527 KE1_Umluftstellung 0;
BA_ "GenSigSendType" SG_ 1527 KE1_Umluftstellung 0;
BA_ "GenSigAutoGenSnd" SG_ 1527 KE1_Umluftstellung 1;
BA_ "GenSigAutoGenDsp" SG_ 1527 KE1_Umluftstellung 1;
BA_ "GenSigSwitchedByIgnition" SG_ 1527 KE1_Comp_rev_rq 0;
BA_ "GenSigSendType" SG_ 1527 KE1_Comp_rev_rq 0;
BA_ "GenSigAutoGenSnd" SG_ 1527 KE1_Comp_rev_rq 1;
BA_ "GenSigAutoGenDsp" SG_ 1527 KE1_Comp_rev_rq 1;
BA_ "GenSigSwitchedByIgnition" SG_ 800 KO1_SleepInd 0;
BA_ "GenSigSendType" SG_ 800 KO1_SleepInd 0;
BA_ "GenSigAutoGenSnd" SG_ 800 KO1_SleepInd 1;
BA_ "GenSigAutoGenDsp" SG_ 800 KO1_SleepInd 1;
BA_ "GenSigSwitchedByIgnition" SG_ 800 KO1_Sta_Tank 0;
BA_ "GenSigSendType" SG_ 800 KO1_Sta_Tank 0;
BA_ "GenSigAutoGenSnd" SG_ 800 KO1_Sta_Tank 1;
BA_ "GenSigAutoGenDsp" SG_ 800 KO1_Sta_Tank 1;
BA_ "GenSigSwitchedByIgnition" SG_ 800 KO1_Oeldruck 0;
BA_ "GenSigSendType" SG_ 800 KO1_Oeldruck 0;
BA_ "GenSigAutoGenSnd" SG_ 800 KO1_Oeldruck 1;
BA_ "GenSigAutoGenDsp" SG_ 800 KO1_Oeldruck 1;
BA_ "GenSigSwitchedByIgnition" SG_ 800 KO1_Sta_Oeldr 0;
BA_ "GenSigSendType" SG_ 800 KO1_Sta_Oeldr 0;
BA_ "GenSigAutoGenSnd" SG_ 800 KO1_Sta_Oeldr 1;
BA_ "GenSigAutoGenDsp" SG_ 800 KO1_Sta_Oeldr 1;
BA_ "GenSigSwitchedByIgnition" SG_ 800 KO1_Kuehlmittel 0;
BA_ "GenSigSendType" SG_ 800 KO1_Kuehlmittel 0;
BA_ "GenSigAutoGenSnd" SG_ 800 KO1_Kuehlmittel 1;
BA_ "GenSigAutoGenDsp" SG_ 800 KO1_Kuehlmittel 1;
BA_ "GenSigSwitchedByIgnition" SG_ 800 KO1_Wakeup_Komfort 0;
BA_ "GenSigSendType" SG_ 800 KO1_Wakeup_Komfort 0;
BA_ "GenSigAutoGenSnd" SG_ 800 KO1_Wakeup_Komfort 1;
BA_ "GenSigAutoGenDsp" SG_ 800 KO1_Wakeup_Komfort 1;
BA_ "GenSigSwitchedByIgnition" SG_ 800 KO1_Warn_Tank 0;
BA_ "GenSigSendType" SG_ 800 KO1_Warn_Tank 0;
BA_ "GenSigAutoGenSnd" SG_ 800 KO1_Warn_Tank 1;
BA_ "GenSigAutoGenDsp" SG_ 800 KO1_Warn_Tank 1;
BA_ "GenSigSwitchedByIgnition" SG_ 800 KO1_Vorgluehen 0;
BA_ "GenSigSendType" SG_ 800 KO1_Vorgluehen 0;
BA_ "GenSigAutoGenSnd" SG_ 800 KO1_Vorgluehen 1;
BA_ "GenSigAutoGenDsp" SG_ 800 KO1_Vorgluehen 1;
BA_ "GenSigSwitchedByIgnition" SG_ 800 KO1_Bremsinfo 0;
BA_ "GenSigSendType" SG_ 800 KO1_Bremsinfo 0;
BA_ "GenSigAutoGenSnd" SG_ 800 KO1_Bremsinfo 1;
BA_ "GenSigAutoGenDsp" SG_ 800 KO1_Bremsinfo 1;
BA_ "GenSigSwitchedByIgnition" SG_ 800 KO1_Handbremse 0;
BA_ "GenSigSendType" SG_ 800 KO1_Handbremse 0;
BA_ "GenSigAutoGenSnd" SG_ 800 KO1_Handbremse 1;
BA_ "GenSigAutoGenDsp" SG_ 800 KO1_Handbremse 1;
BA_ "GenSigSwitchedByIgnition" SG_ 800 KO1_La_Ladekon 0;
BA_ "GenSigSendType" SG_ 800 KO1_La_Ladekon 0;
BA_ "GenSigAutoGenSnd" SG_ 800 KO1_La_Ladekon 1;
BA_ "GenSigAutoGenDsp" SG_ 800 KO1_La_Ladekon 1;
BA_ "GenSigSwitchedByIgnition" SG_ 800 KO1_Stellglieder 0;
BA_ "GenSigSendType" SG_ 800 KO1_Stellglieder 0;
BA_ "GenSigAutoGenSnd" SG_ 800 KO1_Stellglieder 1;
BA_ "GenSigAutoGenDsp" SG_ 800 KO1_Stellglieder 1;
BA_ "GenSigSwitchedByIgnition" SG_ 800 KO1_Zeitluecke 0;
BA_ "GenSigSendType" SG_ 800 KO1_Zeitluecke 0;
BA_ "GenSigAutoGenSnd" SG_ 800 KO1_Zeitluecke 1;
BA_ "GenSigAutoGenDsp" SG_ 800 KO1_Zeitluecke 1;
BA_ "GenSigSwitchedByIgnition" SG_ 800 KO1_Tankstop 0;
BA_ "GenSigSendType" SG_ 800 KO1_Tankstop 0;
BA_ "GenSigAutoGenSnd" SG_ 800 KO1_Tankstop 1;
BA_ "GenSigAutoGenDsp" SG_ 800 KO1_Tankstop 1;
BA_ "Fehlerwert" SG_ 800 KO1_Tankinhalt 127;
BA_ "GenSigSwitchedByIgnition" SG_ 800 KO1_Tankinhalt 0;
BA_ "GenSigSendType" SG_ 800 KO1_Tankinhalt 0;
BA_ "GenSigAutoGenSnd" SG_ 800 KO1_Tankinhalt 1;
BA_ "GenSigAutoGenDsp" SG_ 800 KO1_Tankinhalt 1;
BA_ "GenSigSwitchedByIgnition" SG_ 800 KO1_OBD_Tank 0;
BA_ "GenSigSendType" SG_ 800 KO1_OBD_Tank 0;
BA_ "GenSigAutoGenSnd" SG_ 800 KO1_OBD_Tank 1;
BA_ "GenSigAutoGenDsp" SG_ 800 KO1_OBD_Tank 1;
BA_ "GenSigSwitchedByIgnition" SG_ 800 KO1_Quelle_kmh 0;
BA_ "GenSigSendType" SG_ 800 KO1_Quelle_kmh 0;
BA_ "GenSigAutoGenSnd" SG_ 800 KO1_Quelle_kmh 1;
BA_ "GenSigAutoGenDsp" SG_ 800 KO1_Quelle_kmh 1;
BA_ "GenSigSwitchedByIgnition" SG_ 800 KO1_kmh 0;
BA_ "GenSigSendType" SG_ 800 KO1_kmh 0;
BA_ "GenSigAutoGenSnd" SG_ 800 KO1_kmh 1;
BA_ "GenSigAutoGenDsp" SG_ 800 KO1_kmh 1;
BA_ "GenSigSwitchedByIgnition" SG_ 800 KO1_Zaehler 0;
BA_ "GenSigFuncType" SG_ 800 KO1_Zaehler 1;
BA_ "GenSigSendType" SG_ 800 KO1_Zaehler 0;
BA_ "GenSigAutoGenSnd" SG_ 800 KO1_Zaehler 1;
BA_ "GenSigAutoGenDsp" SG_ 800 KO1_Zaehler 1;
BA_ "Fehlerwert" SG_ 800 KO1_ACC_Inkons 1;
BA_ "GenSigSwitchedByIgnition" SG_ 800 KO1_ACC_Inkons 0;
BA_ "GenSigSendType" SG_ 800 KO1_ACC_Inkons 0;
BA_ "GenSigAutoGenSnd" SG_ 800 KO1_ACC_Inkons 1;
BA_ "GenSigAutoGenDsp" SG_ 800 KO1_ACC_Inkons 1;
BA_ "GenSigSwitchedByIgnition" SG_ 800 KO1_ACC_AnzFhl 0;
BA_ "GenSigSendType" SG_ 800 KO1_ACC_AnzFhl 0;
BA_ "GenSigAutoGenSnd" SG_ 800 KO1_ACC_AnzFhl 1;
BA_ "GenSigAutoGenDsp" SG_ 800 KO1_ACC_AnzFhl 1;
BA_ "Fehlerwert" SG_ 800 KO1_angez_kmh 1023;
BA_ "GenSigSwitchedByIgnition" SG_ 800 KO1_angez_kmh 0;
BA_ "GenSigSendType" SG_ 800 KO1_angez_kmh 0;
BA_ "GenSigAutoGenSnd" SG_ 800 KO1_angez_kmh 1;
BA_ "GenSigAutoGenDsp" SG_ 800 KO1_angez_kmh 1;
BA_ "GenSigSwitchedByIgnition" SG_ 800 KO1_kmh_mph 0;
BA_ "GenSigSendType" SG_ 800 KO1_kmh_mph 0;
BA_ "GenSigAutoGenSnd" SG_ 800 KO1_kmh_mph 1;
BA_ "GenSigAutoGenDsp" SG_ 800 KO1_kmh_mph 1;
BA_ "GenSigSwitchedByIgnition" SG_ 800 KO1_ABS_Lampe 0;
BA_ "GenSigSendType" SG_ 800 KO1_ABS_Lampe 0;
BA_ "GenSigAutoGenSnd" SG_ 800 KO1_ABS_Lampe 1;
BA_ "GenSigAutoGenDsp" SG_ 800 KO1_ABS_Lampe 1;
BA_ "GenSigSwitchedByIgnition" SG_ 800 KO1_ASRESP_Lampe 0;
BA_ "GenSigSendType" SG_ 800 KO1_ASRESP_Lampe 0;
BA_ "GenSigAutoGenSnd" SG_ 800 KO1_ASRESP_Lampe 1;
BA_ "GenSigAutoGenDsp" SG_ 800 KO1_ASRESP_Lampe 1;
BA_ "GenSigSwitchedByIgnition" SG_ 800 KO1_Brems_Lampe 0;
BA_ "GenSigSendType" SG_ 800 KO1_Brems_Lampe 0;
BA_ "GenSigAutoGenSnd" SG_ 800 KO1_Brems_Lampe 1;
BA_ "GenSigAutoGenDsp" SG_ 800 KO1_Brems_Lampe 1;
BA_ "GenSigSwitchedByIgnition" SG_ 800 KO1_Airbag_Lampe 0;
BA_ "GenSigSendType" SG_ 800 KO1_Airbag_Lampe 0;
BA_ "GenSigAutoGenSnd" SG_ 800 KO1_Airbag_Lampe 1;
BA_ "GenSigAutoGenDsp" SG_ 800 KO1_Airbag_Lampe 1;
BA_ "GenSigSwitchedByIgnition" SG_ 800 KO1_Lenkh_Lampe 0;
BA_ "GenSigSendType" SG_ 800 KO1_Lenkh_Lampe 0;
BA_ "GenSigAutoGenSnd" SG_ 800 KO1_Lenkh_Lampe 1;
BA_ "GenSigAutoGenDsp" SG_ 800 KO1_Lenkh_Lampe 1;
BA_ "Fehlerwert" SG_ 800 KO1_LDW_AnzFeh 1;
BA_ "GenSigSwitchedByIgnition" SG_ 800 KO1_LDW_AnzFeh 0;
BA_ "GenSigSendType" SG_ 800 KO1_LDW_AnzFeh 0;
BA_ "GenSigAutoGenSnd" SG_ 800 KO1_LDW_AnzFeh 1;
BA_ "GenSigAutoGenDsp" SG_ 800 KO1_LDW_AnzFeh 1;
BA_ "GenSigSwitchedByIgnition" SG_ 800 KO1_SILA_gueltig 0;
BA_ "GenSigSendType" SG_ 800 KO1_SILA_gueltig 0;
BA_ "GenSigAutoGenSnd" SG_ 800 KO1_SILA_gueltig 1;
BA_ "GenSigAutoGenDsp" SG_ 800 KO1_SILA_gueltig 1;
BA_ "GenSigSwitchedByIgnition" SG_ 1056 KO2_Sta_Auss_T 0;
BA_ "GenSigStartValue" SG_ 1056 KO2_Sta_Auss_T 1;
BA_ "GenSigSendType" SG_ 1056 KO2_Sta_Auss_T 0;
BA_ "GenSigAutoGenSnd" SG_ 1056 KO2_Sta_Auss_T 1;
BA_ "GenSigAutoGenDsp" SG_ 1056 KO2_Sta_Auss_T 1;
BA_ "GenSigSwitchedByIgnition" SG_ 1056 KO2_Verb_TOG 0;
BA_ "GenSigFuncType" SG_ 1056 KO2_Verb_TOG 8;
BA_ "GenSigSendType" SG_ 1056 KO2_Verb_TOG 0;
BA_ "GenSigAutoGenSnd" SG_ 1056 KO2_Verb_TOG 1;
BA_ "GenSigAutoGenDsp" SG_ 1056 KO2_Verb_TOG 1;
BA_ "GenSigSwitchedByIgnition" SG_ 1056 KO2_Oelwarn 0;
BA_ "GenSigSendType" SG_ 1056 KO2_Oelwarn 0;
BA_ "GenSigAutoGenSnd" SG_ 1056 KO2_Oelwarn 1;
BA_ "GenSigAutoGenDsp" SG_ 1056 KO2_Oelwarn 1;
BA_ "GenSigSwitchedByIgnition" SG_ 1056 KO2_GRA_High 0;
BA_ "GenSigSendType" SG_ 1056 KO2_GRA_High 0;
BA_ "GenSigAutoGenSnd" SG_ 1056 KO2_GRA_High 1;
BA_ "GenSigAutoGenDsp" SG_ 1056 KO2_GRA_High 1;
BA_ "GenSigSwitchedByIgnition" SG_ 1056 KO2_Temp_Einheit 0;
BA_ "GenSigSendType" SG_ 1056 KO2_Temp_Einheit 0;
BA_ "GenSigAutoGenSnd" SG_ 1056 KO2_Temp_Einheit 1;
BA_ "GenSigAutoGenDsp" SG_ 1056 KO2_Temp_Einheit 1;
BA_ "GenSigSwitchedByIgnition" SG_ 1056 KO2_Wischwasser 0;
BA_ "GenSigSendType" SG_ 1056 KO2_Wischwasser 0;
BA_ "GenSigAutoGenSnd" SG_ 1056 KO2_Wischwasser 1;
BA_ "GenSigAutoGenDsp" SG_ 1056 KO2_Wischwasser 1;
BA_ "GenSigSwitchedByIgnition" SG_ 1056 KO2_PLA_Displaystatus 0;
BA_ "GenSigSendType" SG_ 1056 KO2_PLA_Displaystatus 0;
BA_ "GenSigAutoGenSnd" SG_ 1056 KO2_PLA_Displaystatus 1;
BA_ "GenSigAutoGenDsp" SG_ 1056 KO2_PLA_Displaystatus 1;
BA_ "GenSigSwitchedByIgnition" SG_ 1056 KO2_Fehlereintr 0;
BA_ "GenSigSendType" SG_ 1056 KO2_Fehlereintr 0;
BA_ "GenSigAutoGenSnd" SG_ 1056 KO2_Fehlereintr 1;
BA_ "GenSigAutoGenDsp" SG_ 1056 KO2_Fehlereintr 1;
BA_ "Fehlerwert" SG_ 1056 KO2_gef_Auss_T 255;
BA_ "GenSigSwitchedByIgnition" SG_ 1056 KO2_gef_Auss_T 0;
BA_ "GenSigSendType" SG_ 1056 KO2_gef_Auss_T 0;
BA_ "GenSigAutoGenSnd" SG_ 1056 KO2_gef_Auss_T 1;
BA_ "GenSigAutoGenDsp" SG_ 1056 KO2_gef_Auss_T 1;
BA_ "Fehlerwert" SG_ 1056 KO2_Aussen_T 255;
BA_ "GenSigSwitchedByIgnition" SG_ 1056 KO2_Aussen_T 0;
BA_ "GenSigSendType" SG_ 1056 KO2_Aussen_T 0;
BA_ "GenSigAutoGenSnd" SG_ 1056 KO2_Aussen_T 1;
BA_ "GenSigAutoGenDsp" SG_ 1056 KO2_Aussen_T 1;
BA_ "GenSigSwitchedByIgnition" SG_ 1056 KB2_EasyEntry 0;
BA_ "GenSigSendType" SG_ 1056 KB2_EasyEntry 0;
BA_ "GenSigAutoGenSnd" SG_ 1056 KB2_EasyEntry 1;
BA_ "GenSigAutoGenDsp" SG_ 1056 KB2_EasyEntry 1;
BA_ "GenSigSwitchedByIgnition" SG_ 1056 KBI_rotes_P_verbaut 0;
BA_ "GenSigSendType" SG_ 1056 KBI_rotes_P_verbaut 0;
BA_ "GenSigAutoGenSnd" SG_ 1056 KBI_rotes_P_verbaut 1;
BA_ "GenSigAutoGenDsp" SG_ 1056 KBI_rotes_P_verbaut 1;
BA_ "GenSigSwitchedByIgnition" SG_ 1056 KO_Segeln_Menuestatus 0;
BA_ "GenSigSendType" SG_ 1056 KO_Segeln_Menuestatus 0;
BA_ "GenSigAutoGenSnd" SG_ 1056 KO_Segeln_Menuestatus 1;
BA_ "GenSigAutoGenDsp" SG_ 1056 KO_Segeln_Menuestatus 1;
BA_ "GenSigSwitchedByIgnition" SG_ 1056 KO_Segeln_Zustandswechsel 0;
BA_ "GenSigSendType" SG_ 1056 KO_Segeln_Zustandswechsel 0;
BA_ "GenSigAutoGenSnd" SG_ 1056 KO_Segeln_Zustandswechsel 1;
BA_ "GenSigAutoGenDsp" SG_ 1056 KO_Segeln_Zustandswechsel 1;
BA_ "GenSigSwitchedByIgnition" SG_ 1056 KB2_Auto_eKiSi 0;
BA_ "GenSigSendType" SG_ 1056 KB2_Auto_eKiSi 0;
BA_ "GenSigAutoGenSnd" SG_ 1056 KB2_Auto_eKiSi 1;
BA_ "GenSigAutoGenDsp" SG_ 1056 KB2_Auto_eKiSi 1;
BA_ "GenSigSwitchedByIgnition" SG_ 1056 KB2_Req_IstZu_Solldruecke 0;
BA_ "GenSigSendType" SG_ 1056 KB2_Req_IstZu_Solldruecke 0;
BA_ "GenSigAutoGenSnd" SG_ 1056 KB2_Req_IstZu_Solldruecke 1;
BA_ "GenSigAutoGenDsp" SG_ 1056 KB2_Req_IstZu_Solldruecke 1;
BA_ "GenSigSwitchedByIgnition" SG_ 1056 KO2_Bel_Displ 0;
BA_ "GenSigSendType" SG_ 1056 KO2_Bel_Displ 0;
BA_ "GenSigAutoGenSnd" SG_ 1056 KO2_Bel_Displ 1;
BA_ "GenSigAutoGenDsp" SG_ 1056 KO2_Bel_Displ 1;
BA_ "GenSigSwitchedByIgnition" SG_ 1056 KO2_Sta_Displ 0;
BA_ "GenSigSendType" SG_ 1056 KO2_Sta_Displ 0;
BA_ "GenSigAutoGenSnd" SG_ 1056 KO2_Sta_Displ 1;
BA_ "GenSigAutoGenDsp" SG_ 1056 KO2_Sta_Displ 1;
BA_ "GenSigSwitchedByIgnition" SG_ 1056 KO2_Bel_Schalt 0;
BA_ "GenSigSendType" SG_ 1056 KO2_Bel_Schalt 0;
BA_ "GenSigAutoGenSnd" SG_ 1056 KO2_Bel_Schalt 1;
BA_ "GenSigAutoGenDsp" SG_ 1056 KO2_Bel_Schalt 1;
BA_ "GenSigSwitchedByIgnition" SG_ 1056 KO2_Sta_Schalt 0;
BA_ "GenSigSendType" SG_ 1056 KO2_Sta_Schalt 0;
BA_ "GenSigAutoGenSnd" SG_ 1056 KO2_Sta_Schalt 1;
BA_ "GenSigAutoGenDsp" SG_ 1056 KO2_Sta_Schalt 1;
BA_ "GenSigSwitchedByIgnition" SG_ 1056 KO2_MFA_v_Einheit 0;
BA_ "GenSigSendType" SG_ 1056 KO2_MFA_v_Einheit 0;
BA_ "GenSigAutoGenSnd" SG_ 1056 KO2_MFA_v_Einheit 1;
BA_ "GenSigAutoGenDsp" SG_ 1056 KO2_MFA_v_Einheit 1;
BA_ "GenSigSwitchedByIgnition" SG_ 1056 KO2_Passiv_Autolock 0;
BA_ "GenSigSendType" SG_ 1056 KO2_Passiv_Autolock 0;
BA_ "GenSigAutoGenSnd" SG_ 1056 KO2_Passiv_Autolock 1;
BA_ "GenSigAutoGenDsp" SG_ 1056 KO2_Passiv_Autolock 1;
BA_ "GenSigSwitchedByIgnition" SG_ 1056 KO2_WFS_Schl_Ort 0;
BA_ "GenSigSendType" SG_ 1056 KO2_WFS_Schl_Ort 0;
BA_ "GenSigAutoGenSnd" SG_ 1056 KO2_WFS_Schl_Ort 1;
BA_ "GenSigAutoGenDsp" SG_ 1056 KO2_WFS_Schl_Ort 1;
BA_ "GenSigSwitchedByIgnition" SG_ 1056 KB2_MFA_Strecke_Einheit 0;
BA_ "GenSigSendType" SG_ 1056 KB2_MFA_Strecke_Einheit 0;
BA_ "GenSigAutoGenSnd" SG_ 1056 KB2_MFA_Strecke_Einheit 1;
BA_ "GenSigAutoGenDsp" SG_ 1056 KB2_MFA_Strecke_Einheit 1;
BA_ "GenSigSwitchedByIgnition" SG_ 1056 KO2_OBD_Nib_Temp 0;
BA_ "GenSigSendType" SG_ 1056 KO2_OBD_Nib_Temp 0;
BA_ "GenSigAutoGenSnd" SG_ 1056 KO2_OBD_Nib_Temp 1;
BA_ "GenSigAutoGenDsp" SG_ 1056 KO2_OBD_Nib_Temp 1;
BA_ "GenSigSwitchedByIgnition" SG_ 1312 KO3_Sprache 0;
BA_ "GenSigAutoGenSnd" SG_ 1312 KO3_Sprache 1;
BA_ "GenSigAutoGenDsp" SG_ 1312 KO3_Sprache 1;
BA_ "GenSigSwitchedByIgnition" SG_ 1312 KO3_Derivat 0;
BA_ "GenSigAutoGenSnd" SG_ 1312 KO3_Derivat 1;
BA_ "GenSigAutoGenDsp" SG_ 1312 KO3_Derivat 1;
BA_ "GenSigSwitchedByIgnition" SG_ 1312 KO3_Radumfang 0;
BA_ "GenSigAutoGenSnd" SG_ 1312 KO3_Radumfang 1;
BA_ "GenSigAutoGenDsp" SG_ 1312 KO3_Radumfang 1;
BA_ "GenSigSwitchedByIgnition" SG_ 1312 KO3_Verbau_Mot 0;
BA_ "GenSigAutoGenSnd" SG_ 1312 KO3_Verbau_Mot 1;
BA_ "GenSigAutoGenDsp" SG_ 1312 KO3_Verbau_Mot 1;
BA_ "GenSigSwitchedByIgnition" SG_ 1312 KO3_Verbau_Get 0;
BA_ "GenSigAutoGenSnd" SG_ 1312 KO3_Verbau_Get 1;
BA_ "GenSigAutoGenDsp" SG_ 1312 KO3_Verbau_Get 1;
BA_ "GenSigSwitchedByIgnition" SG_ 1312 KO3_Verbau_Br 0;
BA_ "GenSigAutoGenSnd" SG_ 1312 KO3_Verbau_Br 1;
BA_ "GenSigAutoGenDsp" SG_ 1312 KO3_Verbau_Br 1;
BA_ "GenSigSwitchedByIgnition" SG_ 1312 KO3_Verbau_Kl 0;
BA_ "GenSigAutoGenSnd" SG_ 1312 KO3_Verbau_Kl 1;
BA_ "GenSigAutoGenDsp" SG_ 1312 KO3_Verbau_Kl 1;
BA_ "GenSigSwitchedByIgnition" SG_ 1312 KO3_Generation 0;
BA_ "GenSigAutoGenSnd" SG_ 1312 KO3_Generation 1;
BA_ "GenSigAutoGenDsp" SG_ 1312 KO3_Generation 1;
BA_ "GenSigSwitchedByIgnition" SG_ 1312 KO3_Verbau_Air 0;
BA_ "GenSigAutoGenSnd" SG_ 1312 KO3_Verbau_Air 1;
BA_ "GenSigAutoGenDsp" SG_ 1312 KO3_Verbau_Air 1;
BA_ "GenSigSwitchedByIgnition" SG_ 1312 KO3_Verbau_ADR 0;
BA_ "GenSigAutoGenSnd" SG_ 1312 KO3_Verbau_ADR 1;
BA_ "GenSigAutoGenDsp" SG_ 1312 KO3_Verbau_ADR 1;
BA_ "GenSigSwitchedByIgnition" SG_ 1312 KO3_Verbau_BN 0;
BA_ "GenSigAutoGenSnd" SG_ 1312 KO3_Verbau_BN 1;
BA_ "GenSigAutoGenDsp" SG_ 1312 KO3_Verbau_BN 1;
BA_ "GenSigSwitchedByIgnition" SG_ 1312 KO3_Verbau_Syn 0;
BA_ "GenSigAutoGenSnd" SG_ 1312 KO3_Verbau_Syn 1;
BA_ "GenSigAutoGenDsp" SG_ 1312 KO3_Verbau_Syn 1;
BA_ "GenSigSwitchedByIgnition" SG_ 1312 KO3_Land 0;
BA_ "GenSigAutoGenSnd" SG_ 1312 KO3_Land 1;
BA_ "GenSigAutoGenDsp" SG_ 1312 KO3_Land 1;
BA_ "GenSigSwitchedByIgnition" SG_ 1312 KO3_Baureihe 0;
BA_ "GenSigAutoGenSnd" SG_ 1312 KO3_Baureihe 1;
BA_ "GenSigAutoGenDsp" SG_ 1312 KO3_Baureihe 1;
BA_ "GenSigSwitchedByIgnition" SG_ 1312 KO3_Verbau_LWS 0;
BA_ "GenSigAutoGenSnd" SG_ 1312 KO3_Verbau_LWS 1;
BA_ "GenSigAutoGenDsp" SG_ 1312 KO3_Verbau_LWS 1;
BA_ "GenSigSwitchedByIgnition" SG_ 1312 KO3_Verbau_DP 0;
BA_ "GenSigAutoGenSnd" SG_ 1312 KO3_Verbau_DP 1;
BA_ "GenSigAutoGenDsp" SG_ 1312 KO3_Verbau_DP 1;
BA_ "GenSigSwitchedByIgnition" SG_ 1312 KO3_Verbau_LH 0;
BA_ "GenSigAutoGenSnd" SG_ 1312 KO3_Verbau_LH 1;
BA_ "GenSigAutoGenDsp" SG_ 1312 KO3_Verbau_LH 1;
BA_ "GenSigSwitchedByIgnition" SG_ 1312 KO3_Marke 0;
BA_ "GenSigAutoGenSnd" SG_ 1312 KO3_Marke 1;
BA_ "GenSigAutoGenDsp" SG_ 1312 KO3_Marke 1;
BA_ "GenSigSwitchedByIgnition" SG_ 1312 KO3_Verbau_Niveau 0;
BA_ "GenSigAutoGenSnd" SG_ 1312 KO3_Verbau_Niveau 1;
BA_ "GenSigAutoGenDsp" SG_ 1312 KO3_Verbau_Niveau 1;
BA_ "GenSigSwitchedByIgnition" SG_ 1312 KO3_Mp_Code 0;
BA_ "GenSigSendType" SG_ 1312 KO3_Mp_Code 0;
BA_ "GenSigAutoGenSnd" SG_ 1312 KO3_Mp_Code 1;
BA_ "GenSigAutoGenDsp" SG_ 1312 KO3_Mp_Code 1;
BA_ "GenSigSwitchedByIgnition" SG_ 1312 KO3_Schluessel 0;
BA_ "GenSigSendType" SG_ 1312 KO3_Schluessel 0;
BA_ "GenSigAutoGenSnd" SG_ 1312 KO3_Schluessel 1;
BA_ "GenSigAutoGenDsp" SG_ 1312 KO3_Schluessel 1;
BA_ "GenSigSwitchedByIgnition" SG_ 1312 KO3_Um_AFS2 0;
BA_ "GenSigSendType" SG_ 1312 KO3_Um_AFS2 0;
BA_ "GenSigAutoGenSnd" SG_ 1312 KO3_Um_AFS2 1;
BA_ "GenSigAutoGenDsp" SG_ 1312 KO3_Um_AFS2 1;
BA_ "GenSigSwitchedByIgnition" SG_ 1312 KO3_Um_Tourist 0;
BA_ "GenSigSendType" SG_ 1312 KO3_Um_Tourist 0;
BA_ "GenSigAutoGenSnd" SG_ 1312 KO3_Um_Tourist 1;
BA_ "GenSigAutoGenDsp" SG_ 1312 KO3_Um_Tourist 1;
BA_ "GenSigSwitchedByIgnition" SG_ 1312 KO3_Um_AutoHold 0;
BA_ "GenSigSendType" SG_ 1312 KO3_Um_AutoHold 0;
BA_ "GenSigAutoGenSnd" SG_ 1312 KO3_Um_AutoHold 1;
BA_ "GenSigAutoGenDsp" SG_ 1312 KO3_Um_AutoHold 1;
BA_ "Fehlerwert" SG_ 1312 KO3_SWA_AnzFeh 1;
BA_ "GenSigSwitchedByIgnition" SG_ 1312 KO3_SWA_AnzFeh 0;
BA_ "GenSigSendType" SG_ 1312 KO3_SWA_AnzFeh 0;
BA_ "GenSigAutoGenSnd" SG_ 1312 KO3_SWA_AnzFeh 1;
BA_ "GenSigAutoGenDsp" SG_ 1312 KO3_SWA_AnzFeh 1;
BA_ "GenSigSwitchedByIgnition" SG_ 1312 KO3_Standzeit 0;
BA_ "GenSigSendType" SG_ 1312 KO3_Standzeit 0;
BA_ "GenSigAutoGenSnd" SG_ 1312 KO3_Standzeit 1;
BA_ "GenSigAutoGenDsp" SG_ 1312 KO3_Standzeit 1;
BA_ "GenSigSwitchedByIgnition" SG_ 1312 KO3_Sta_Standz 0;
BA_ "GenSigSendType" SG_ 1312 KO3_Sta_Standz 0;
BA_ "GenSigAutoGenSnd" SG_ 1312 KO3_Sta_Standz 1;
BA_ "GenSigAutoGenDsp" SG_ 1312 KO3_Sta_Standz 1;
BA_ "GenSigSwitchedByIgnition" SG_ 1312 KO3_Kilometer 0;
BA_ "GenSigSendType" SG_ 1312 KO3_Kilometer 0;
BA_ "GenSigAutoGenSnd" SG_ 1312 KO3_Kilometer 1;
BA_ "GenSigAutoGenDsp" SG_ 1312 KO3_Kilometer 1;
BA_ "GenSigSwitchedByIgnition" SG_ 1564 Restladezeit_HV_Batterie 0;
BA_ "GenSigStartValue" SG_ 1564 Restladezeit_HV_Batterie 127;
BA_ "GenSigSendType" SG_ 1564 Restladezeit_HV_Batterie 0;
BA_ "GenSigSwitchedByIgnition" SG_ 1564 Lademodus_HV_Batterie 0;
BA_ "GenSigSendType" SG_ 1564 Lademodus_HV_Batterie 0;
BA_ "GenSigSwitchedByIgnition" SG_ 1564 LM_EKlKomLeiRed 0;
BA_ "GenSigSendType" SG_ 1564 LM_EKlKomLeiRed 0;
BA_ "GenSigAutoGenSnd" SG_ 1564 LM_EKlKomLeiRed 1;
BA_ "GenSigAutoGenDsp" SG_ 1564 LM_EKlKomLeiRed 1;
BA_ "GenSigSwitchedByIgnition" SG_ 1564 LM_HV_PTC_aus 0;
BA_ "GenSigSendType" SG_ 1564 LM_HV_PTC_aus 0;
BA_ "GenSigSwitchedByIgnition" SG_ 1564 LM_HV_PTC_LeistRed 0;
BA_ "GenSigSendType" SG_ 1564 LM_HV_PTC_LeistRed 0;
BA_ "GenSigSwitchedByIgnition" SG_ 1564 LM_KlimaKompr 0;
BA_ "GenSigSendType" SG_ 1564 LM_KlimaKompr 0;
BA_ "GenSigAutoGenSnd" SG_ 1564 LM_KlimaKompr 1;
BA_ "GenSigAutoGenDsp" SG_ 1564 LM_KlimaKompr 1;
BA_ "GenSigSwitchedByIgnition" SG_ 1564 LM_Bat_heiz_aktiv 0;
BA_ "GenSigSendType" SG_ 1564 LM_Bat_heiz_aktiv 0;
BA_ "GenSigSwitchedByIgnition" SG_ 1564 LM_Bat_kuehl_aktiv 0;
BA_ "GenSigSendType" SG_ 1564 LM_Bat_kuehl_aktiv 0;
BA_ "GenSigSwitchedByIgnition" SG_ 1564 LM_Bat_laden_aktiv 0;
BA_ "GenSigSendType" SG_ 1564 LM_Bat_laden_aktiv 0;
BA_ "GenSigSwitchedByIgnition" SG_ 1564 LM_Wake_Up_KCAN 0;
BA_ "GenSigSendType" SG_ 1564 LM_Wake_Up_KCAN 0;
BA_ "GenSigAutoGenSnd" SG_ 1564 LM_Wake_Up_KCAN 1;
BA_ "GenSigAutoGenDsp" SG_ 1564 LM_Wake_Up_KCAN 1;
BA_ "GenSigSwitchedByIgnition" SG_ 1564 LM_Standkl_heiz_aktiv 0;
BA_ "GenSigSendType" SG_ 1564 LM_Standkl_heiz_aktiv 0;
BA_ "GenSigSwitchedByIgnition" SG_ 1564 LM_Standkl_kuehl_aktiv 0;
BA_ "GenSigSendType" SG_ 1564 LM_Standkl_kuehl_aktiv 0;
BA_ "GenSigSwitchedByIgnition" SG_ 1564 LM_MaxLadLeistung_HV 0;
BA_ "GenSigStartValue" SG_ 1564 LM_MaxLadLeistung_HV 511;
BA_ "GenSigSendType" SG_ 1564 LM_MaxLadLeistung_HV 0;
BA_ "GenSigSendType" SG_ 1470 LDW_Lernmodus_seitenabhaengig 0;
BA_ "GenSigAutoGenSnd" SG_ 1470 LDW_Lernmodus_seitenabhaengig 1;
BA_ "GenSigAutoGenDsp" SG_ 1470 LDW_Lernmodus_seitenabhaengig 1;
BA_ "GenSigSendType" SG_ 1470 LDW_Lernmodus 0;
BA_ "GenSigAutoGenSnd" SG_ 1470 LDW_Lernmodus 1;
BA_ "GenSigAutoGenDsp" SG_ 1470 LDW_Lernmodus 1;
BA_ "GenSigSendType" SG_ 1470 LDW_Textbits 0;
BA_ "GenSigAutoGenSnd" SG_ 1470 LDW_Textbits 1;
BA_ "GenSigAutoGenDsp" SG_ 1470 LDW_Textbits 1;
BA_ "GenSigSendType" SG_ 1470 LDW_Gong 0;
BA_ "GenSigAutoGenSnd" SG_ 1470 LDW_Gong 1;
BA_ "GenSigAutoGenDsp" SG_ 1470 LDW_Gong 1;
BA_ "GenSigSendType" SG_ 1470 LDW_Lampe_gelb 0;
BA_ "GenSigAutoGenSnd" SG_ 1470 LDW_Lampe_gelb 1;
BA_ "GenSigAutoGenDsp" SG_ 1470 LDW_Lampe_gelb 1;
BA_ "GenSigSendType" SG_ 1470 LDW_Lampe_gruen 0;
BA_ "GenSigAutoGenSnd" SG_ 1470 LDW_Lampe_gruen 1;
BA_ "GenSigAutoGenDsp" SG_ 1470 LDW_Lampe_gruen 1;
BA_ "GenSigSendType" SG_ 1470 LDW_SW_Warnung_links 0;
BA_ "GenSigAutoGenSnd" SG_ 1470 LDW_SW_Warnung_links 1;
BA_ "GenSigAutoGenDsp" SG_ 1470 LDW_SW_Warnung_links 1;
BA_ "GenSigSendType" SG_ 1470 LDW_SW_Warnung_rechts 0;
BA_ "GenSigAutoGenSnd" SG_ 1470 LDW_SW_Warnung_rechts 1;
BA_ "GenSigAutoGenDsp" SG_ 1470 LDW_SW_Warnung_rechts 1;
BA_ "Fehlerwert" SG_ 1470 LDW_KD_Fehler 1;
BA_ "GenSigSendType" SG_ 1470 LDW_KD_Fehler 0;
BA_ "GenSigAutoGenSnd" SG_ 1470 LDW_KD_Fehler 1;
BA_ "GenSigAutoGenDsp" SG_ 1470 LDW_KD_Fehler 1;
BA_ "GenSigStartValue" SG_ 1470 LDW_DLC 250;
BA_ "GenSigSendType" SG_ 1470 LDW_DLC 0;
BA_ "GenSigAutoGenSnd" SG_ 1470 LDW_DLC 1;
BA_ "GenSigAutoGenDsp" SG_ 1470 LDW_DLC 1;
BA_ "GenSigStartValue" SG_ 1470 LDW_TLC 31;
BA_ "GenSigSendType" SG_ 1470 LDW_TLC 0;
BA_ "GenSigAutoGenSnd" SG_ 1470 LDW_TLC 1;
BA_ "GenSigAutoGenDsp" SG_ 1470 LDW_TLC 1;
BA_ "GenSigSendType" SG_ 1470 LDW_Seite_DLCTLC 0;
BA_ "GenSigAutoGenSnd" SG_ 1470 LDW_Seite_DLCTLC 1;
BA_ "GenSigAutoGenDsp" SG_ 1470 LDW_Seite_DLCTLC 1;
BA_ "Fehlerwert" SG_ 1470 LDW_Frueh_Spaet 3;
BA_ "GenSigSendType" SG_ 1470 LDW_Frueh_Spaet 0;
BA_ "GenSigEnvVarType" SG_ 1470 LDW_Frueh_Spaet 0;
BA_ "GenSigAutoGenSnd" SG_ 1470 LDW_Frueh_Spaet 1;
BA_ "GenSigAutoGenDsp" SG_ 1470 LDW_Frueh_Spaet 1;
BA_ "GenSigSendType" SG_ 976 LH1_Lastinfo 0;
BA_ "GenSigAutoGenSnd" SG_ 976 LH1_Lastinfo 1;
BA_ "GenSigAutoGenDsp" SG_ 976 LH1_Lastinfo 1;
BA_ "GenSigSendType" SG_ 976 LH1_Fehler_LI 0;
BA_ "GenSigAutoGenSnd" SG_ 976 LH1_Fehler_LI 1;
BA_ "GenSigAutoGenDsp" SG_ 976 LH1_Fehler_LI 1;
BA_ "GenSigStartValue" SG_ 976 LH1_Sicherheitslamp 1;
BA_ "GenSigSendType" SG_ 976 LH1_Sicherheitslamp 0;
BA_ "GenSigAutoGenSnd" SG_ 976 LH1_Sicherheitslamp 1;
BA_ "GenSigAutoGenDsp" SG_ 976 LH1_Sicherheitslamp 1;
BA_ "GenSigSendType" SG_ 976 LH1_Fehlerlampe 0;
BA_ "GenSigAutoGenSnd" SG_ 976 LH1_Fehlerlampe 1;
BA_ "GenSigAutoGenDsp" SG_ 976 LH1_Fehlerlampe 1;
BA_ "GenSigSendType" SG_ 976 LH1_Textbits 0;
BA_ "GenSigAutoGenSnd" SG_ 976 LH1_Textbits 1;
BA_ "GenSigAutoGenDsp" SG_ 976 LH1_Textbits 1;
BA_ "GenSigSendType" SG_ 976 LH1_Akustiksign 0;
BA_ "GenSigAutoGenSnd" SG_ 976 LH1_Akustiksign 1;
BA_ "GenSigAutoGenDsp" SG_ 976 LH1_Akustiksign 1;
BA_ "GenSigSwitchedByIgnition" SG_ 976 LH1_SleepInd 0;
BA_ "GenSigSendType" SG_ 976 LH1_SleepInd 0;
BA_ "GenSigAutoGenSnd" SG_ 976 LH1_SleepInd 1;
BA_ "GenSigAutoGenDsp" SG_ 976 LH1_SleepInd 1;
BA_ "GenSigSwitchedByIgnition" SG_ 976 LH1_Fehlereintr 0;
BA_ "GenSigSendType" SG_ 976 LH1_Fehlereintr 0;
BA_ "GenSigAutoGenSnd" SG_ 976 LH1_Fehlereintr 1;
BA_ "GenSigAutoGenDsp" SG_ 976 LH1_Fehlereintr 1;
BA_ "GenSigSendType" SG_ 976 LH1_EPS_Diagmode 0;
BA_ "GenSigAutoGenSnd" SG_ 976 LH1_EPS_Diagmode 1;
BA_ "GenSigAutoGenDsp" SG_ 976 LH1_EPS_Diagmode 1;
BA_ "GenSigSendType" SG_ 976 LH1_gue_ECU_Temp 0;
BA_ "GenSigAutoGenSnd" SG_ 976 LH1_gue_ECU_Temp 1;
BA_ "GenSigAutoGenDsp" SG_ 976 LH1_gue_ECU_Temp 1;
BA_ "GenSigSendType" SG_ 976 LH1_Kuehlung 0;
BA_ "GenSigAutoGenSnd" SG_ 976 LH1_Kuehlung 1;
BA_ "GenSigAutoGenDsp" SG_ 976 LH1_Kuehlung 1;
BA_ "GenSigSendType" SG_ 976 LH1_Mode_Hybrid 0;
BA_ "GenSigAutoGenSnd" SG_ 976 LH1_Mode_Hybrid 1;
BA_ "GenSigAutoGenDsp" SG_ 976 LH1_Mode_Hybrid 1;
BA_ "GenSigSendType" SG_ 976 LH1_NL_Untersp 0;
BA_ "GenSigAutoGenSnd" SG_ 976 LH1_NL_Untersp 1;
BA_ "GenSigAutoGenDsp" SG_ 976 LH1_NL_Untersp 1;
BA_ "GenSigSendType" SG_ 976 LH1_NL_Uebersp 0;
BA_ "GenSigAutoGenSnd" SG_ 976 LH1_NL_Uebersp 1;
BA_ "GenSigAutoGenDsp" SG_ 976 LH1_NL_Uebersp 1;
BA_ "GenSigSendType" SG_ 976 LH1_NL_Uebertemp 0;
BA_ "GenSigAutoGenSnd" SG_ 976 LH1_NL_Uebertemp 1;
BA_ "GenSigAutoGenDsp" SG_ 976 LH1_NL_Uebertemp 1;
BA_ "GenSigSendType" SG_ 976 LH1_NL_Sensor 0;
BA_ "GenSigAutoGenSnd" SG_ 976 LH1_NL_Sensor 1;
BA_ "GenSigAutoGenDsp" SG_ 976 LH1_NL_Sensor 1;
BA_ "GenSigSendType" SG_ 976 LH1_NL_CAN_SS 0;
BA_ "GenSigAutoGenSnd" SG_ 976 LH1_NL_CAN_SS 1;
BA_ "GenSigAutoGenDsp" SG_ 976 LH1_NL_CAN_SS 1;
BA_ "GenSigSendType" SG_ 976 LH1_NL_ECU 0;
BA_ "GenSigAutoGenSnd" SG_ 976 LH1_NL_ECU 1;
BA_ "GenSigAutoGenDsp" SG_ 976 LH1_NL_ECU 1;
BA_ "GenSigSendType" SG_ 976 LH1_NL_Motor 0;
BA_ "GenSigAutoGenSnd" SG_ 976 LH1_NL_Motor 1;
BA_ "GenSigAutoGenDsp" SG_ 976 LH1_NL_Motor 1;
BA_ "GenSigSendType" SG_ 976 LH1_NL_LeistDichte 0;
BA_ "GenSigAutoGenSnd" SG_ 976 LH1_NL_LeistDichte 1;
BA_ "GenSigAutoGenDsp" SG_ 976 LH1_NL_LeistDichte 1;
BA_ "GenSigSendType" SG_ 976 LH1_ULeistung 0;
BA_ "GenSigAutoGenSnd" SG_ 976 LH1_ULeistung 1;
BA_ "GenSigAutoGenDsp" SG_ 976 LH1_ULeistung 1;
BA_ "GenSigSendType" SG_ 976 LH1_ECU_Temp 0;
BA_ "GenSigAutoGenSnd" SG_ 976 LH1_ECU_Temp 1;
BA_ "GenSigAutoGenDsp" SG_ 976 LH1_ECU_Temp 1;
BA_ "GenSigSwitchedByIgnition" SG_ 978 LH2_Checksumme 0;
BA_ "GenSigFuncType" SG_ 978 LH2_Checksumme 4;
BA_ "GenSigSendType" SG_ 978 LH2_Checksumme 0;
BA_ "GenSigAutoGenSnd" SG_ 978 LH2_Checksumme 1;
BA_ "GenSigAutoGenDsp" SG_ 978 LH2_Checksumme 1;
BA_ "GenSigSwitchedByIgnition" SG_ 978 LH2_Zaehler 0;
BA_ "GenSigFuncType" SG_ 978 LH2_Zaehler 1;
BA_ "GenSigSendType" SG_ 978 LH2_Zaehler 0;
BA_ "GenSigAutoGenSnd" SG_ 978 LH2_Zaehler 1;
BA_ "GenSigAutoGenDsp" SG_ 978 LH2_Zaehler 1;
BA_ "GenSigSendType" SG_ 978 LH2_Geradeaus 0;
BA_ "GenSigAutoGenSnd" SG_ 978 LH2_Geradeaus 1;
BA_ "GenSigAutoGenDsp" SG_ 978 LH2_Geradeaus 1;
BA_ "GenSigStartValue" SG_ 978 LH2_Sta_Charisma 2;
BA_ "GenSigSendType" SG_ 978 LH2_Sta_Charisma 0;
BA_ "GenSigAutoGenSnd" SG_ 978 LH2_Sta_Charisma 1;
BA_ "GenSigAutoGenDsp" SG_ 978 LH2_Sta_Charisma 1;
BA_ "GenSigSendType" SG_ 978 LH2_Sta_HCA 0;
BA_ "GenSigAutoGenSnd" SG_ 978 LH2_Sta_HCA 1;
BA_ "GenSigAutoGenDsp" SG_ 978 LH2_Sta_HCA 1;
BA_ "GenSigSendType" SG_ 978 LH2_Ausg_LW1 0;
BA_ "GenSigAutoGenSnd" SG_ 978 LH2_Ausg_LW1 1;
BA_ "GenSigAutoGenDsp" SG_ 978 LH2_Ausg_LW1 1;
BA_ "GenSigSendType" SG_ 978 LH2_Ausg_LW1_gue 0;
BA_ "GenSigAutoGenSnd" SG_ 978 LH2_Ausg_LW1_gue 1;
BA_ "GenSigAutoGenDsp" SG_ 978 LH2_Ausg_LW1_gue 1;
BA_ "GenSigSendType" SG_ 978 LH2_StatEPS_PLA 0;
BA_ "GenSigAutoGenSnd" SG_ 978 LH2_StatEPS_PLA 1;
BA_ "GenSigAutoGenDsp" SG_ 978 LH2_StatEPS_PLA 1;
BA_ "GenSigSendType" SG_ 978 LH2_aktLenkeingriff 0;
BA_ "GenSigAutoGenSnd" SG_ 978 LH2_aktLenkeingriff 1;
BA_ "GenSigAutoGenDsp" SG_ 978 LH2_aktLenkeingriff 1;
BA_ "GenSigSendType" SG_ 978 LH2_PLA_Err 0;
BA_ "GenSigAutoGenSnd" SG_ 978 LH2_PLA_Err 1;
BA_ "GenSigAutoGenDsp" SG_ 978 LH2_PLA_Err 1;
BA_ "GenSigSendType" SG_ 978 LH2_PLA_Abbr 0;
BA_ "GenSigAutoGenSnd" SG_ 978 LH2_PLA_Abbr 1;
BA_ "GenSigAutoGenDsp" SG_ 978 LH2_PLA_Abbr 1;
BA_REL_ "GenSigTimeoutTime" BU_SG_REL_ Motor_Diesel SG_ 1100 GE6_Checksum 500;
BA_REL_ "GenSigTimeoutTime" BU_SG_REL_ Motor_Otto SG_ 1100 GE6_Checksum 500;
BA_REL_ "GenSigTimeoutTime" BU_SG_REL_ Motor_Diesel SG_ 1100 GE6_TurbDZ 500;
BA_REL_ "GenSigTimeoutTime" BU_SG_REL_ Motor_Otto SG_ 1100 GE6_TurbDZ 500;
BA_REL_ "GenSigTimeoutTime" BU_SG_REL_ Motor_Diesel SG_ 1100 GE6_QB_OelTemp 500;
BA_REL_ "GenSigTimeoutTime" BU_SG_REL_ Motor_Otto SG_ 1100 GE6_QB_OelTemp 500;
BA_REL_ "GenSigTimeoutTime" BU_SG_REL_ Motor_Diesel SG_ 1100 GE6_OelTemp 500;
BA_REL_ "GenSigTimeoutTime" BU_SG_REL_ Motor_Otto SG_ 1100 GE6_OelTemp 500;
BA_REL_ "GenSigTimeoutTime" BU_SG_REL_ Motor_Diesel SG_ 1100 GE6_Zaehler 500;
BA_REL_ "GenSigTimeoutTime" BU_SG_REL_ Motor_Otto SG_ 1100 GE6_Zaehler 500;
BA_REL_ "GenSigTimeoutTime" BU_SG_REL_ Motor_Otto SG_ 1104 GE8_Checksumme 500;
BA_REL_ "GenSigTimeoutTime" BU_SG_REL_ Motor_Otto SG_ 1104 GE8_Zaehler 500;
BA_REL_ "GenSigTimeoutTime" BU_SG_REL_ Motor_Otto SG_ 1104 GE8_Hydr_Pumpe 500;
BA_REL_ "GenSigTimeoutTime" BU_SG_REL_ Motor_Otto SG_ 1104 GE8_Motor_aus 500;
BA_REL_ "GenSigTimeoutTime" BU_SG_REL_ Motor_Otto SG_ 1104 GE8_Anfahrfkt 500;
BA_REL_ "GenSigTimeoutTime" BU_SG_REL_ Motor_Otto SG_ 1104 GE8_SollDZ 500;
BA_REL_ "GenSigTimeoutTime" BU_SG_REL_ Motor_Otto SG_ 1104 GE8_VorsteuerMom 500;
BA_REL_ "GenSigTimeoutTime" BU_SG_REL_ Motor_Otto SG_ 1104 GE8_KuppMom 500;
BA_REL_ "GenSigTimeoutTime" BU_SG_REL_ Motor_Hybrid SG_ 1106 GH1_Zaehler 500;
BA_REL_ "GenSigTimeoutTime" BU_SG_REL_ Motor_Hybrid SG_ 1106 GH1_FreigabeK0 500;
BA_REL_ "GenSigTimeoutTime" BU_SG_REL_ Motor_Hybrid SG_ 1106 GH1_FreigabeVMStop 500;
BA_REL_ "GenSigTimeoutTime" BU_SG_REL_ Motor_Hybrid SG_ 1106 GH1_FehlerstatusGSG 500;
BA_REL_ "GenSigTimeoutTime" BU_SG_REL_ Motor_Hybrid SG_ 1106 GH1_nK0 500;
BA_REL_ "GenSigTimeoutTime" BU_SG_REL_ LEH_Hybrid SG_ 1106 GH1_VZMomEingriff 500;
BA_REL_ "GenSigTimeoutTime" BU_SG_REL_ LEH_Hybrid SG_ 1106 GH1_MomEingriff_EM 500;
BA_REL_ "GenSigTimeoutTime" BU_SG_REL_ Motor_Hybrid SG_ 1106 GH1_Wiederstart 500;
BA_REL_ "GenSigTimeoutTime" BU_SG_REL_ Motor_Hybrid SG_ 1106 GH1_VM_akt_halten 500;
BA_REL_ "GenSigTimeoutTime" BU_SG_REL_ Motor_Hybrid SG_ 1106 GH1_Sportfaktor 500;
BA_REL_ "GenSigTimeoutTime" BU_SG_REL_ Motor_Hybrid SG_ 1106 GH1_Freig_LL_Reg 500;
BA_REL_ "GenSigTimeoutTime" BU_SG_REL_ Motor_Hybrid SG_ 1106 GH1_VKM_StAnf 500;
BA_REL_ "GenSigTimeoutTime" BU_SG_REL_ Motor_Hybrid SG_ 1106 GH1_VKM_StKontr 500;
BA_REL_ "GenSigTimeoutTime" BU_SG_REL_ Motor_Hybrid SG_ 1106 GH1_AnzeigeDZ 500;
BA_REL_ "GenSigTimeoutTime" BU_SG_REL_ Motor_Hybrid SG_ 1106 GH1_Filt_MomAufbau 500;
BA_REL_ "GenSigTimeoutTime" BU_SG_REL_ Motor_Diesel SG_ 906 GRA_Checksum 500;
BA_REL_ "GenSigTimeoutTime" BU_SG_REL_ Motor_Hybrid SG_ 906 GRA_Checksum 500;
BA_REL_ "GenSigTimeoutTime" BU_SG_REL_ Motor_Otto SG_ 906 GRA_Checksum 500;
BA_REL_ "GenSigTimeoutTime" BU_SG_REL_ Motor_Diesel SG_ 906 GRA_Hauptschalt 500;
BA_REL_ "GenSigTimeoutTime" BU_SG_REL_ Motor_Hybrid SG_ 906 GRA_Hauptschalt 500;
BA_REL_ "GenSigTimeoutTime" BU_SG_REL_ Motor_Otto SG_ 906 GRA_Hauptschalt 500;
BA_REL_ "GenSigTimeoutTime" BU_SG_REL_ Motor_Diesel SG_ 906 GRA_Abbrechen 500;
BA_REL_ "GenSigTimeoutTime" BU_SG_REL_ Motor_Hybrid SG_ 906 GRA_Abbrechen 500;
BA_REL_ "GenSigTimeoutTime" BU_SG_REL_ Motor_Otto SG_ 906 GRA_Abbrechen 500;
BA_REL_ "GenSigTimeoutTime" BU_SG_REL_ Getriebe_DQ SG_ 906 GRA_Down_kurz 500;
BA_REL_ "GenSigTimeoutTime" BU_SG_REL_ Getriebe_DQ_Hyb SG_ 906 GRA_Down_kurz 500;
BA_REL_ "GenSigTimeoutTime" BU_SG_REL_ Motor_Diesel SG_ 906 GRA_Down_kurz 500;
BA_REL_ "GenSigTimeoutTime" BU_SG_REL_ Motor_Hybrid SG_ 906 GRA_Down_kurz 500;
BA_REL_ "GenSigTimeoutTime" BU_SG_REL_ Motor_Otto SG_ 906 GRA_Down_kurz 500;
BA_REL_ "GenSigTimeoutTime" BU_SG_REL_ Getriebe_DQ SG_ 906 GRA_Up_kurz 500;
BA_REL_ "GenSigTimeoutTime" BU_SG_REL_ Getriebe_DQ_Hyb SG_ 906 GRA_Up_kurz 500;
BA_REL_ "GenSigTimeoutTime" BU_SG_REL_ Motor_Diesel SG_ 906 GRA_Up_kurz 500;
BA_REL_ "GenSigTimeoutTime" BU_SG_REL_ Motor_Hybrid SG_ 906 GRA_Up_kurz 500;
BA_REL_ "GenSigTimeoutTime" BU_SG_REL_ Motor_Otto SG_ 906 GRA_Up_kurz 500;
BA_REL_ "GenSigTimeoutTime" BU_SG_REL_ Motor_Diesel SG_ 906 GRA_Fehler_Bed 500;
BA_REL_ "GenSigTimeoutTime" BU_SG_REL_ Motor_Hybrid SG_ 906 GRA_Fehler_Bed 500;
BA_REL_ "GenSigTimeoutTime" BU_SG_REL_ Motor_Otto SG_ 906 GRA_Fehler_Bed 500;
BA_REL_ "GenSigTimeoutTime" BU_SG_REL_ Motor_Diesel SG_ 906 GRA_Kodierinfo 500;
BA_REL_ "GenSigTimeoutTime" BU_SG_REL_ Motor_Hybrid SG_ 906 GRA_Kodierinfo 500;
BA_REL_ "GenSigTimeoutTime" BU_SG_REL_ Motor_Otto SG_ 906 GRA_Kodierinfo 500;
BA_REL_ "GenSigTimeoutTime" BU_SG_REL_ Getriebe_DQ SG_ 906 GRA_Neu_Setzen 500;
BA_REL_ "GenSigTimeoutTime" BU_SG_REL_ Getriebe_DQ_Hyb SG_ 906 GRA_Neu_Setzen 500;
BA_REL_ "GenSigTimeoutTime" BU_SG_REL_ Motor_Diesel SG_ 906 GRA_Neu_Setzen 500;
BA_REL_ "GenSigTimeoutTime" BU_SG_REL_ Motor_Hybrid SG_ 906 GRA_Neu_Setzen 500;
BA_REL_ "GenSigTimeoutTime" BU_SG_REL_ Motor_Otto SG_ 906 GRA_Neu_Setzen 500;
BA_REL_ "GenSigTimeoutTime" BU_SG_REL_ Getriebe_DQ SG_ 906 GRA_Recall 500;
BA_REL_ "GenSigTimeoutTime" BU_SG_REL_ Getriebe_DQ_Hyb SG_ 906 GRA_Recall 500;
BA_REL_ "GenSigTimeoutTime" BU_SG_REL_ Motor_Diesel SG_ 906 GRA_Recall 500;
BA_REL_ "GenSigTimeoutTime" BU_SG_REL_ Motor_Hybrid SG_ 906 GRA_Recall 500;
BA_REL_ "GenSigTimeoutTime" BU_SG_REL_ Motor_Otto SG_ 906 GRA_Recall 500;
BA_REL_ "GenSigTimeoutTime" BU_SG_REL_ Getriebe_DQ SG_ 906 GRA_Sender 500;
BA_REL_ "GenSigTimeoutTime" BU_SG_REL_ Getriebe_DQ_Hyb SG_ 906 GRA_Sender 500;
BA_REL_ "GenSigTimeoutTime" BU_SG_REL_ Getriebe_Sele SG_ 906 GRA_Sender 500;
BA_REL_ "GenSigTimeoutTime" BU_SG_REL_ Motor_Diesel SG_ 906 GRA_Sender 500;
BA_REL_ "GenSigTimeoutTime" BU_SG_REL_ Motor_Hybrid SG_ 906 GRA_Sender 500;
BA_REL_ "GenSigTimeoutTime" BU_SG_REL_ Motor_Otto SG_ 906 GRA_Sender 500;
BA_REL_ "GenSigTimeoutTime" BU_SG_REL_ Motor_Diesel SG_ 906 GRA_Neu_Zaehler 500;
BA_REL_ "GenSigTimeoutTime" BU_SG_REL_ Motor_Hybrid SG_ 906 GRA_Neu_Zaehler 500;
BA_REL_ "GenSigTimeoutTime" BU_SG_REL_ Motor_Otto SG_ 906 GRA_Neu_Zaehler 500;
BA_REL_ "GenSigTimeoutTime" BU_SG_REL_ Getriebe_AG6 SG_ 906 GRA_Tip_Down 500;
BA_REL_ "GenSigTimeoutTime" BU_SG_REL_ Getriebe_DQ SG_ 906 GRA_Tip_Down 500;
BA_REL_ "GenSigTimeoutTime" BU_SG_REL_ Getriebe_DQ_Hyb SG_ 906 GRA_Tip_Down 500;
BA_REL_ "GenSigTimeoutTime" BU_SG_REL_ Getriebe_Sele SG_ 906 GRA_Tip_Down 500;
BA_REL_ "GenSigTimeoutTime" BU_SG_REL_ Getriebe_AG6 SG_ 906 GRA_Tip_Up 500;
BA_REL_ "GenSigTimeoutTime" BU_SG_REL_ Getriebe_DQ SG_ 906 GRA_Tip_Up 500;
BA_REL_ "GenSigTimeoutTime" BU_SG_REL_ Getriebe_DQ_Hyb SG_ 906 GRA_Tip_Up 500;
BA_REL_ "GenSigTimeoutTime" BU_SG_REL_ Getriebe_Sele SG_ 906 GRA_Tip_Up 500;
BA_REL_ "GenSigTimeoutTime" BU_SG_REL_ Motor_Diesel SG_ 906 GRA_Typ_Hauptschalt 500;
BA_REL_ "GenSigTimeoutTime" BU_SG_REL_ Motor_Hybrid SG_ 906 GRA_Typ_Hauptschalt 500;
BA_REL_ "GenSigTimeoutTime" BU_SG_REL_ Motor_Otto SG_ 906 GRA_Typ_Hauptschalt 500;
BA_REL_ "GenSigTimeoutTime" BU_SG_REL_ Getriebe_AG6 SG_ 906 GRA_Fehler_Tip 500;
BA_REL_ "GenSigTimeoutTime" BU_SG_REL_ Getriebe_DQ SG_ 906 GRA_Fehler_Tip 500;
BA_REL_ "GenSigTimeoutTime" BU_SG_REL_ Getriebe_DQ_Hyb SG_ 906 GRA_Fehler_Tip 500;
BA_REL_ "GenSigTimeoutTime" BU_SG_REL_ Ladegeraet_EGolf SG_ 1510 Weckzeit_EV_erreicht 5000;
BA_REL_ "GenSigTimeoutTime" BU_SG_REL_ Ladegeraet_EGolf SG_ 1510 GSM_MaxLeistung_NT 5000;
BA_REL_ "GenSigTimeoutTime" BU_SG_REL_ Ladegeraet_EGolf SG_ 1510 Standklimatisierung_Anf 5000;
BA_REL_ "GenSigTimeoutTime" BU_SG_REL_ Ladegeraet_EGolf SG_ 1510 Ladevorgang_Anf 5000;
BA_REL_ "GenSigTimeoutTime" BU_SG_REL_ Ladegeraet_EGolf SG_ 1510 Ladestrom_max 5000;
BA_REL_ "GenSigTimeoutTime" BU_SG_REL_ Ladegeraet_EGolf SG_ 1510 GSM_Zeit_Typ 5000;
BA_REL_ "GenSigTimeoutTime" BU_SG_REL_ Ladegeraet_EGolf SG_ 1510 GSM_Jahr 5000;
BA_REL_ "GenSigTimeoutTime" BU_SG_REL_ Ladegeraet_EGolf SG_ 1510 GSM_Monat 5000;
BA_REL_ "GenSigTimeoutTime" BU_SG_REL_ Ladegeraet_EGolf SG_ 1510 GSM_Tag 5000;
BA_REL_ "GenSigTimeoutTime" BU_SG_REL_ Ladegeraet_EGolf SG_ 1510 GSM_Stunde 5000;
BA_REL_ "GenSigTimeoutTime" BU_SG_REL_ Ladegeraet_EGolf SG_ 1510 GSM_Minute 5000;
BA_REL_ "GenSigTimeoutTime" BU_SG_REL_ Ladegeraet_EGolf SG_ 1510 GSM_Ladestecker_Anf 5000;
BA_REL_ "GenSigTimeoutTime" BU_SG_REL_ Ladegeraet_EGolf SG_ 1510 GSM_SOC_Untergrenze 5000;
BA_REL_ "GenSigTimeoutTime" BU_SG_REL_ Ladegeraet_EGolf SG_ 1510 GSM_SOC_Obergrenze 5000;
BA_REL_ "GenSigTimeoutTime" BU_SG_REL_ Gateway_PQ35 SG_ 1529 GM_KD_Fehler 5000;
BA_REL_ "GenSigTimeoutTime" BU_SG_REL_ LH_EPS_APA SG_ 210 HC1_Checksumme 500;
BA_REL_ "GenSigTimeoutTime" BU_SG_REL_ LH_EPS_ZF_2G SG_ 210 HC1_Checksumme 500;
BA_REL_ "GenSigTimeoutTime" BU_SG_REL_ LH_EPS_ZF_3G SG_ 210 HC1_Checksumme 500;
BA_REL_ "GenSigTimeoutTime" BU_SG_REL_ LH_EPS_APA SG_ 210 HC1_Zaehler 500;
BA_REL_ "GenSigTimeoutTime" BU_SG_REL_ LH_EPS_ZF_2G SG_ 210 HC1_Zaehler 500;
BA_REL_ "GenSigTimeoutTime" BU_SG_REL_ LH_EPS_ZF_3G SG_ 210 HC1_Zaehler 500;
BA_REL_ "GenSigTimeoutTime" BU_SG_REL_ Gateway_PQ35 SG_ 210 HC1_Sta_HCA 500;
BA_REL_ "GenSigTimeoutTime" BU_SG_REL_ LH_EPS_APA SG_ 210 HC1_Sta_HCA 500;
BA_REL_ "GenSigTimeoutTime" BU_SG_REL_ LH_EPS_ZF_2G SG_ 210 HC1_Sta_HCA 500;
BA_REL_ "GenSigTimeoutTime" BU_SG_REL_ LH_EPS_ZF_3G SG_ 210 HC1_Sta_HCA 500;
BA_REL_ "GenSigTimeoutTime" BU_SG_REL_ Gateway_PQ35 SG_ 210 HC1_LM_Offset 500;
BA_REL_ "GenSigTimeoutTime" BU_SG_REL_ LH_EPS_APA SG_ 210 HC1_LM_Offset 500;
BA_REL_ "GenSigTimeoutTime" BU_SG_REL_ LH_EPS_ZF_2G SG_ 210 HC1_LM_Offset 500;
BA_REL_ "GenSigTimeoutTime" BU_SG_REL_ LH_EPS_ZF_3G SG_ 210 HC1_LM_Offset 500;
BA_REL_ "GenSigTimeoutTime" BU_SG_REL_ Gateway_PQ35 SG_ 210 HC1_LM_Offset_Sign 500;
BA_REL_ "GenSigTimeoutTime" BU_SG_REL_ LH_EPS_APA SG_ 210 HC1_LM_Offset_Sign 500;
BA_REL_ "GenSigTimeoutTime" BU_SG_REL_ LH_EPS_ZF_2G SG_ 210 HC1_LM_Offset_Sign 500;
BA_REL_ "GenSigTimeoutTime" BU_SG_REL_ LH_EPS_ZF_3G SG_ 210 HC1_LM_Offset_Sign 500;
BA_REL_ "GenSigTimeoutTime" BU_SG_REL_ LH_EPS_APA SG_ 210 HC1_Frequenz 500;
BA_REL_ "GenSigTimeoutTime" BU_SG_REL_ LH_EPS_ZF_2G SG_ 210 HC1_Frequenz 500;
BA_REL_ "GenSigTimeoutTime" BU_SG_REL_ LH_EPS_ZF_3G SG_ 210 HC1_Frequenz 500;
BA_REL_ "GenSigTimeoutTime" BU_SG_REL_ LH_EPS_APA SG_ 210 HC1_Amplitude 500;
BA_REL_ "GenSigTimeoutTime" BU_SG_REL_ LH_EPS_ZF_2G SG_ 210 HC1_Amplitude 500;
BA_REL_ "GenSigTimeoutTime" BU_SG_REL_ LH_EPS_ZF_3G SG_ 210 HC1_Amplitude 500;
BA_REL_ "GenSigTimeoutTime" BU_SG_REL_ Airbag SG_ 1490 IDT_Mux 2000;
BA_REL_ "GenSigTimeoutTime" BU_SG_REL_ Bremse_MK60EC SG_ 1490 IDT_Mux 2000;
BA_REL_ "GenSigTimeoutTime" BU_SG_REL_ Bremse_MK70MABS SG_ 1490 IDT_Mux 2000;
BA_REL_ "GenSigTimeoutTime" BU_SG_REL_ Bremse_TRW_EBC450M SG_ 1490 IDT_Mux 2000;
BA_REL_ "GenSigTimeoutTime" BU_SG_REL_ Bremse_TRW_ESP SG_ 1490 IDT_Mux 2000;
BA_REL_ "GenSigTimeoutTime" BU_SG_REL_ Daempfer SG_ 1490 IDT_Mux 2000;
BA_REL_ "GenSigTimeoutTime" BU_SG_REL_ EPB_TRW SG_ 1490 IDT_Mux 2000;
BA_REL_ "GenSigTimeoutTime" BU_SG_REL_ EPB_TRW_VW411CS SG_ 1490 IDT_Mux 2000;
BA_REL_ "GenSigTimeoutTime" BU_SG_REL_ LH_EPS_APA SG_ 1490 IDT_Mux 2000;
BA_REL_ "GenSigTimeoutTime" BU_SG_REL_ LH_EPS_ZF_2G SG_ 1490 IDT_Mux 2000;
BA_REL_ "GenSigTimeoutTime" BU_SG_REL_ LH_EPS_ZF_3G SG_ 1490 IDT_Mux 2000;
BA_REL_ "GenSigTimeoutTime" BU_SG_REL_ LWS SG_ 1490 IDT_Mux 2000;
BA_REL_ "GenSigTimeoutTime" BU_SG_REL_ Magne_Ride SG_ 1490 IDT_Mux 2000;
BA_REL_ "GenSigTimeoutTime" BU_SG_REL_ Airbag SG_ 1490 IDT_VIN_4 2000;
BA_REL_ "GenSigTimeoutTime" BU_SG_REL_ Daempfer SG_ 1490 IDT_VIN_4 2000;
BA_REL_ "GenSigTimeoutTime" BU_SG_REL_ LWS SG_ 1490 IDT_VIN_4 2000;
BA_REL_ "GenSigTimeoutTime" BU_SG_REL_ Magne_Ride SG_ 1490 IDT_VIN_4 2000;
BA_REL_ "GenSigTimeoutTime" BU_SG_REL_ Airbag SG_ 1490 IDT_VIN_11 2000;
BA_REL_ "GenSigTimeoutTime" BU_SG_REL_ Daempfer SG_ 1490 IDT_VIN_11 2000;
BA_REL_ "GenSigTimeoutTime" BU_SG_REL_ LWS SG_ 1490 IDT_VIN_11 2000;
BA_REL_ "GenSigTimeoutTime" BU_SG_REL_ Magne_Ride SG_ 1490 IDT_VIN_11 2000;
BA_REL_ "GenSigTimeoutTime" BU_SG_REL_ Airbag SG_ 1490 IDT_VIN_5 2000;
BA_REL_ "GenSigTimeoutTime" BU_SG_REL_ Daempfer SG_ 1490 IDT_VIN_5 2000;
BA_REL_ "GenSigTimeoutTime" BU_SG_REL_ LWS SG_ 1490 IDT_VIN_5 2000;
BA_REL_ "GenSigTimeoutTime" BU_SG_REL_ Magne_Ride SG_ 1490 IDT_VIN_5 2000;
BA_REL_ "GenSigTimeoutTime" BU_SG_REL_ Airbag SG_ 1490 IDT_VIN_12 2000;
BA_REL_ "GenSigTimeoutTime" BU_SG_REL_ Daempfer SG_ 1490 IDT_VIN_12 2000;
BA_REL_ "GenSigTimeoutTime" BU_SG_REL_ LWS SG_ 1490 IDT_VIN_12 2000;
BA_REL_ "GenSigTimeoutTime" BU_SG_REL_ Magne_Ride SG_ 1490 IDT_VIN_12 2000;
BA_REL_ "GenSigTimeoutTime" BU_SG_REL_ Airbag SG_ 1490 IDT_VIN_6 2000;
BA_REL_ "GenSigTimeoutTime" BU_SG_REL_ Daempfer SG_ 1490 IDT_VIN_6 2000;
BA_REL_ "GenSigTimeoutTime" BU_SG_REL_ LWS SG_ 1490 IDT_VIN_6 2000;
BA_REL_ "GenSigTimeoutTime" BU_SG_REL_ Magne_Ride SG_ 1490 IDT_VIN_6 2000;
BA_REL_ "GenSigTimeoutTime" BU_SG_REL_ Airbag SG_ 1490 IDT_VIN_13 2000;
BA_REL_ "GenSigTimeoutTime" BU_SG_REL_ Bremse_MK60EC SG_ 1490 IDT_VIN_13 2000;
BA_REL_ "GenSigTimeoutTime" BU_SG_REL_ Bremse_TRW_EBC450M SG_ 1490 IDT_VIN_13 2000;
BA_REL_ "GenSigTimeoutTime" BU_SG_REL_ Bremse_TRW_ESP SG_ 1490 IDT_VIN_13 2000;
BA_REL_ "GenSigTimeoutTime" BU_SG_REL_ Daempfer SG_ 1490 IDT_VIN_13 2000;
BA_REL_ "GenSigTimeoutTime" BU_SG_REL_ EPB_TRW SG_ 1490 IDT_VIN_13 2000;
BA_REL_ "GenSigTimeoutTime" BU_SG_REL_ EPB_TRW_VW411CS SG_ 1490 IDT_VIN_13 2000;
BA_REL_ "GenSigTimeoutTime" BU_SG_REL_ LWS SG_ 1490 IDT_VIN_13 2000;
BA_REL_ "GenSigTimeoutTime" BU_SG_REL_ Magne_Ride SG_ 1490 IDT_VIN_13 2000;
BA_REL_ "GenSigTimeoutTime" BU_SG_REL_ Airbag SG_ 1490 IDT_VIN_7 2000;
BA_REL_ "GenSigTimeoutTime" BU_SG_REL_ Bremse_MK60EC SG_ 1490 IDT_VIN_7 2000;
BA_REL_ "GenSigTimeoutTime" BU_SG_REL_ Bremse_TRW_EBC450M SG_ 1490 IDT_VIN_7 2000;
BA_REL_ "GenSigTimeoutTime" BU_SG_REL_ Daempfer SG_ 1490 IDT_VIN_7 2000;
BA_REL_ "GenSigTimeoutTime" BU_SG_REL_ EPB_TRW SG_ 1490 IDT_VIN_7 2000;
BA_REL_ "GenSigTimeoutTime" BU_SG_REL_ EPB_TRW_VW411CS SG_ 1490 IDT_VIN_7 2000;
BA_REL_ "GenSigTimeoutTime" BU_SG_REL_ LWS SG_ 1490 IDT_VIN_7 2000;
BA_REL_ "GenSigTimeoutTime" BU_SG_REL_ Magne_Ride SG_ 1490 IDT_VIN_7 2000;
BA_REL_ "GenSigTimeoutTime" BU_SG_REL_ Airbag SG_ 1490 IDT_VIN_14 2000;
BA_REL_ "GenSigTimeoutTime" BU_SG_REL_ Bremse_MK60EC SG_ 1490 IDT_VIN_14 2000;
BA_REL_ "GenSigTimeoutTime" BU_SG_REL_ Bremse_MK70MABS SG_ 1490 IDT_VIN_14 2000;
BA_REL_ "GenSigTimeoutTime" BU_SG_REL_ Bremse_TRW_EBC450M SG_ 1490 IDT_VIN_14 2000;
BA_REL_ "GenSigTimeoutTime" BU_SG_REL_ Bremse_TRW_ESP SG_ 1490 IDT_VIN_14 2000;
BA_REL_ "GenSigTimeoutTime" BU_SG_REL_ Daempfer SG_ 1490 IDT_VIN_14 2000;
BA_REL_ "GenSigTimeoutTime" BU_SG_REL_ EPB_TRW SG_ 1490 IDT_VIN_14 2000;
BA_REL_ "GenSigTimeoutTime" BU_SG_REL_ EPB_TRW_VW411CS SG_ 1490 IDT_VIN_14 2000;
BA_REL_ "GenSigTimeoutTime" BU_SG_REL_ LH_EPS_APA SG_ 1490 IDT_VIN_14 2000;
BA_REL_ "GenSigTimeoutTime" BU_SG_REL_ LH_EPS_ZF_2G SG_ 1490 IDT_VIN_14 2000;
BA_REL_ "GenSigTimeoutTime" BU_SG_REL_ LH_EPS_ZF_3G SG_ 1490 IDT_VIN_14 2000;
BA_REL_ "GenSigTimeoutTime" BU_SG_REL_ LWS SG_ 1490 IDT_VIN_14 2000;
BA_REL_ "GenSigTimeoutTime" BU_SG_REL_ Magne_Ride SG_ 1490 IDT_VIN_14 2000;
BA_REL_ "GenSigTimeoutTime" BU_SG_REL_ Airbag SG_ 1490 IDT_VIN_1 2000;
BA_REL_ "GenSigTimeoutTime" BU_SG_REL_ Daempfer SG_ 1490 IDT_VIN_1 2000;
BA_REL_ "GenSigTimeoutTime" BU_SG_REL_ LWS SG_ 1490 IDT_VIN_1 2000;
BA_REL_ "GenSigTimeoutTime" BU_SG_REL_ Magne_Ride SG_ 1490 IDT_VIN_1 2000;
BA_REL_ "GenSigTimeoutTime" BU_SG_REL_ Airbag SG_ 1490 IDT_VIN_8 2000;
BA_REL_ "GenSigTimeoutTime" BU_SG_REL_ Bremse_MK60EC SG_ 1490 IDT_VIN_8 2000;
BA_REL_ "GenSigTimeoutTime" BU_SG_REL_ Bremse_TRW_EBC450M SG_ 1490 IDT_VIN_8 2000;
BA_REL_ "GenSigTimeoutTime" BU_SG_REL_ Daempfer SG_ 1490 IDT_VIN_8 2000;
BA_REL_ "GenSigTimeoutTime" BU_SG_REL_ EPB_TRW SG_ 1490 IDT_VIN_8 2000;
BA_REL_ "GenSigTimeoutTime" BU_SG_REL_ EPB_TRW_VW411CS SG_ 1490 IDT_VIN_8 2000;
BA_REL_ "GenSigTimeoutTime" BU_SG_REL_ LWS SG_ 1490 IDT_VIN_8 2000;
BA_REL_ "GenSigTimeoutTime" BU_SG_REL_ Magne_Ride SG_ 1490 IDT_VIN_8 2000;
BA_REL_ "GenSigTimeoutTime" BU_SG_REL_ Airbag SG_ 1490 IDT_VIN_15 2000;
BA_REL_ "GenSigTimeoutTime" BU_SG_REL_ Bremse_MK60EC SG_ 1490 IDT_VIN_15 2000;
BA_REL_ "GenSigTimeoutTime" BU_SG_REL_ Bremse_MK70MABS SG_ 1490 IDT_VIN_15 2000;
BA_REL_ "GenSigTimeoutTime" BU_SG_REL_ Bremse_TRW_EBC450M SG_ 1490 IDT_VIN_15 2000;
BA_REL_ "GenSigTimeoutTime" BU_SG_REL_ Bremse_TRW_ESP SG_ 1490 IDT_VIN_15 2000;
BA_REL_ "GenSigTimeoutTime" BU_SG_REL_ Daempfer SG_ 1490 IDT_VIN_15 2000;
BA_REL_ "GenSigTimeoutTime" BU_SG_REL_ EPB_TRW SG_ 1490 IDT_VIN_15 2000;
BA_REL_ "GenSigTimeoutTime" BU_SG_REL_ EPB_TRW_VW411CS SG_ 1490 IDT_VIN_15 2000;
BA_REL_ "GenSigTimeoutTime" BU_SG_REL_ LH_EPS_APA SG_ 1490 IDT_VIN_15 2000;
BA_REL_ "GenSigTimeoutTime" BU_SG_REL_ LH_EPS_ZF_2G SG_ 1490 IDT_VIN_15 2000;
BA_REL_ "GenSigTimeoutTime" BU_SG_REL_ LH_EPS_ZF_3G SG_ 1490 IDT_VIN_15 2000;
BA_REL_ "GenSigTimeoutTime" BU_SG_REL_ LWS SG_ 1490 IDT_VIN_15 2000;
BA_REL_ "GenSigTimeoutTime" BU_SG_REL_ Magne_Ride SG_ 1490 IDT_VIN_15 2000;
BA_REL_ "GenSigTimeoutTime" BU_SG_REL_ Airbag SG_ 1490 IDT_VIN_2 2000;
BA_REL_ "GenSigTimeoutTime" BU_SG_REL_ Daempfer SG_ 1490 IDT_VIN_2 2000;
BA_REL_ "GenSigTimeoutTime" BU_SG_REL_ LWS SG_ 1490 IDT_VIN_2 2000;
BA_REL_ "GenSigTimeoutTime" BU_SG_REL_ Magne_Ride SG_ 1490 IDT_VIN_2 2000;
BA_REL_ "GenSigTimeoutTime" BU_SG_REL_ Airbag SG_ 1490 IDT_VIN_9 2000;
BA_REL_ "GenSigTimeoutTime" BU_SG_REL_ Daempfer SG_ 1490 IDT_VIN_9 2000;
BA_REL_ "GenSigTimeoutTime" BU_SG_REL_ LWS SG_ 1490 IDT_VIN_9 2000;
BA_REL_ "GenSigTimeoutTime" BU_SG_REL_ Magne_Ride SG_ 1490 IDT_VIN_9 2000;
BA_REL_ "GenSigTimeoutTime" BU_SG_REL_ Airbag SG_ 1490 IDT_VIN_16 2000;
BA_REL_ "GenSigTimeoutTime" BU_SG_REL_ Bremse_MK60EC SG_ 1490 IDT_VIN_16 2000;
BA_REL_ "GenSigTimeoutTime" BU_SG_REL_ Bremse_MK70MABS SG_ 1490 IDT_VIN_16 2000;
BA_REL_ "GenSigTimeoutTime" BU_SG_REL_ Bremse_TRW_EBC450M SG_ 1490 IDT_VIN_16 2000;
BA_REL_ "GenSigTimeoutTime" BU_SG_REL_ Bremse_TRW_ESP SG_ 1490 IDT_VIN_16 2000;
BA_REL_ "GenSigTimeoutTime" BU_SG_REL_ Daempfer SG_ 1490 IDT_VIN_16 2000;
BA_REL_ "GenSigTimeoutTime" BU_SG_REL_ EPB_TRW SG_ 1490 IDT_VIN_16 2000;
BA_REL_ "GenSigTimeoutTime" BU_SG_REL_ EPB_TRW_VW411CS SG_ 1490 IDT_VIN_16 2000;
BA_REL_ "GenSigTimeoutTime" BU_SG_REL_ LH_EPS_APA SG_ 1490 IDT_VIN_16 2000;
BA_REL_ "GenSigTimeoutTime" BU_SG_REL_ LH_EPS_ZF_2G SG_ 1490 IDT_VIN_16 2000;
BA_REL_ "GenSigTimeoutTime" BU_SG_REL_ LH_EPS_ZF_3G SG_ 1490 IDT_VIN_16 2000;
BA_REL_ "GenSigTimeoutTime" BU_SG_REL_ LWS SG_ 1490 IDT_VIN_16 2000;
BA_REL_ "GenSigTimeoutTime" BU_SG_REL_ Magne_Ride SG_ 1490 IDT_VIN_16 2000;
BA_REL_ "GenSigTimeoutTime" BU_SG_REL_ Airbag SG_ 1490 IDT_VIN_3 2000;
BA_REL_ "GenSigTimeoutTime" BU_SG_REL_ Daempfer SG_ 1490 IDT_VIN_3 2000;
BA_REL_ "GenSigTimeoutTime" BU_SG_REL_ LWS SG_ 1490 IDT_VIN_3 2000;
BA_REL_ "GenSigTimeoutTime" BU_SG_REL_ Magne_Ride SG_ 1490 IDT_VIN_3 2000;
BA_REL_ "GenSigTimeoutTime" BU_SG_REL_ Airbag SG_ 1490 IDT_VIN_10 2000;
BA_REL_ "GenSigTimeoutTime" BU_SG_REL_ Daempfer SG_ 1490 IDT_VIN_10 2000;
BA_REL_ "GenSigTimeoutTime" BU_SG_REL_ LWS SG_ 1490 IDT_VIN_10 2000;
BA_REL_ "GenSigTimeoutTime" BU_SG_REL_ Magne_Ride SG_ 1490 IDT_VIN_10 2000;
BA_REL_ "GenSigTimeoutTime" BU_SG_REL_ Airbag SG_ 1490 IDT_VIN_17 2000;
BA_REL_ "GenSigTimeoutTime" BU_SG_REL_ Bremse_MK60EC SG_ 1490 IDT_VIN_17 2000;
BA_REL_ "GenSigTimeoutTime" BU_SG_REL_ Bremse_MK70MABS SG_ 1490 IDT_VIN_17 2000;
BA_REL_ "GenSigTimeoutTime" BU_SG_REL_ Bremse_TRW_EBC450M SG_ 1490 IDT_VIN_17 2000;
BA_REL_ "GenSigTimeoutTime" BU_SG_REL_ Bremse_TRW_ESP SG_ 1490 IDT_VIN_17 2000;
BA_REL_ "GenSigTimeoutTime" BU_SG_REL_ Daempfer SG_ 1490 IDT_VIN_17 2000;
BA_REL_ "GenSigTimeoutTime" BU_SG_REL_ EPB_TRW SG_ 1490 IDT_VIN_17 2000;
BA_REL_ "GenSigTimeoutTime" BU_SG_REL_ EPB_TRW_VW411CS SG_ 1490 IDT_VIN_17 2000;
BA_REL_ "GenSigTimeoutTime" BU_SG_REL_ LH_EPS_APA SG_ 1490 IDT_VIN_17 2000;
BA_REL_ "GenSigTimeoutTime" BU_SG_REL_ LH_EPS_ZF_2G SG_ 1490 IDT_VIN_17 2000;
BA_REL_ "GenSigTimeoutTime" BU_SG_REL_ LH_EPS_ZF_3G SG_ 1490 IDT_VIN_17 2000;
BA_REL_ "GenSigTimeoutTime" BU_SG_REL_ LWS SG_ 1490 IDT_VIN_17 2000;
BA_REL_ "GenSigTimeoutTime" BU_SG_REL_ Magne_Ride SG_ 1490 IDT_VIN_17 2000;
BA_REL_ "GenSigTimeoutTime" BU_SG_REL_ BMS_Hybrid SG_ 1512 KL_PTC_Soll 5000;
BA_REL_ "GenSigTimeoutTime" BU_SG_REL_ Ladegeraet_EGolf SG_ 1512 KL_PTC_Soll 5000;
BA_REL_ "GenSigTimeoutTime" BU_SG_REL_ Ladegeraet_EGolf SG_ 1512 PTC_Strom 5000;
BA_REL_ "GenSigTimeoutTime" BU_SG_REL_ Ladegeraet_EGolf SG_ 1512 EKK_Strom 5000;
BA_REL_ "GenSigTimeoutTime" BU_SG_REL_ Ladegeraet_EGolf SG_ 1512 EKK_Status 5000;
BA_REL_ "GenSigTimeoutTime" BU_SG_REL_ Ladegeraet_EGolf SG_ 1512 KL_Standklima_Status 5000;
BA_REL_ "GenSigTimeoutTime" BU_SG_REL_ Ladegeraet_EGolf SG_ 1512 KL_Charisma_FahrPr 5000;
BA_REL_ "GenSigTimeoutTime" BU_SG_REL_ Ladegeraet_EGolf SG_ 1512 KL_Charisma_Status 5000;
BA_REL_ "GenSigTimeoutTime" BU_SG_REL_ BMS_Hybrid SG_ 1527 KE1_Umluftstellung 5000;
BA_REL_ "GenSigTimeoutTime" BU_SG_REL_ Motor_Diesel SG_ 800 KO1_Sta_Tank 500;
BA_REL_ "GenSigTimeoutTime" BU_SG_REL_ Motor_Hybrid SG_ 800 KO1_Sta_Tank 500;
BA_REL_ "GenSigTimeoutTime" BU_SG_REL_ Motor_Otto SG_ 800 KO1_Sta_Tank 500;
BA_REL_ "GenSigTimeoutTime" BU_SG_REL_ Motor_Diesel SG_ 800 KO1_Oeldruck 500;
BA_REL_ "GenSigTimeoutTime" BU_SG_REL_ Motor_Otto SG_ 800 KO1_Oeldruck 500;
BA_REL_ "GenSigTimeoutTime" BU_SG_REL_ Motor_Diesel SG_ 800 KO1_Kuehlmittel 500;
BA_REL_ "GenSigTimeoutTime" BU_SG_REL_ Motor_Otto SG_ 800 KO1_Kuehlmittel 500;
BA_REL_ "GenSigTimeoutTime" BU_SG_REL_ Motor_Diesel SG_ 800 KO1_Warn_Tank 500;
BA_REL_ "GenSigTimeoutTime" BU_SG_REL_ Motor_Diesel SG_ 800 KO1_Warn_Tank 500;
BA_REL_ "GenSigTimeoutTime" BU_SG_REL_ Motor_Otto SG_ 800 KO1_Warn_Tank 500;
BA_REL_ "GenSigTimeoutTime" BU_SG_REL_ Motor_Diesel SG_ 800 KO1_Vorgluehen 500;
BA_REL_ "GenSigTimeoutTime" BU_SG_REL_ Allrad SG_ 800 KO1_Handbremse 500;
BA_REL_ "GenSigTimeoutTime" BU_SG_REL_ Bremse_MK60EC SG_ 800 KO1_Handbremse 500;
BA_REL_ "GenSigTimeoutTime" BU_SG_REL_ Bremse_MK70MABS SG_ 800 KO1_Handbremse 500;
BA_REL_ "GenSigTimeoutTime" BU_SG_REL_ Getriebe_DQ SG_ 800 KO1_Handbremse 500;
BA_REL_ "GenSigTimeoutTime" BU_SG_REL_ Getriebe_DQ_Hyb SG_ 800 KO1_Handbremse 500;
BA_REL_ "GenSigTimeoutTime" BU_SG_REL_ Getriebe_Sele SG_ 800 KO1_Handbremse 500;
BA_REL_ "GenSigTimeoutTime" BU_SG_REL_ LH_EPS_APA SG_ 800 KO1_Handbremse 500;
BA_REL_ "GenSigTimeoutTime" BU_SG_REL_ LH_EPS_ZF_2G SG_ 800 KO1_Handbremse 500;
BA_REL_ "GenSigTimeoutTime" BU_SG_REL_ LH_EPS_ZF_3G SG_ 800 KO1_Handbremse 500;
BA_REL_ "GenSigTimeoutTime" BU_SG_REL_ Motor_Diesel SG_ 800 KO1_Handbremse 500;
BA_REL_ "GenSigTimeoutTime" BU_SG_REL_ Motor_Hybrid SG_ 800 KO1_Handbremse 500;
BA_REL_ "GenSigTimeoutTime" BU_SG_REL_ Motor_Otto SG_ 800 KO1_Handbremse 500;
BA_REL_ "GenSigTimeoutTime" BU_SG_REL_ RKA_Plus SG_ 800 KO1_Handbremse 500;
BA_REL_ "GenSigTimeoutTime" BU_SG_REL_ Airbag SG_ 800 KO1_Stellglieder 500;
BA_REL_ "GenSigTimeoutTime" BU_SG_REL_ LH_EPS_ZF_2G SG_ 800 KO1_Stellglieder 500;
BA_REL_ "GenSigTimeoutTime" BU_SG_REL_ LH_EPS_ZF_3G SG_ 800 KO1_Stellglieder 500;
BA_REL_ "GenSigTimeoutTime" BU_SG_REL_ Motor_Diesel SG_ 800 KO1_Stellglieder 500;
BA_REL_ "GenSigTimeoutTime" BU_SG_REL_ Motor_Diesel SG_ 800 KO1_Tankinhalt 500;
BA_REL_ "GenSigTimeoutTime" BU_SG_REL_ Motor_Hybrid SG_ 800 KO1_Tankinhalt 500;
BA_REL_ "GenSigTimeoutTime" BU_SG_REL_ Motor_Otto SG_ 800 KO1_Tankinhalt 500;
BA_REL_ "GenSigTimeoutTime" BU_SG_REL_ Motor_Diesel SG_ 800 KO1_OBD_Tank 500;
BA_REL_ "GenSigTimeoutTime" BU_SG_REL_ Motor_Hybrid SG_ 800 KO1_OBD_Tank 500;
BA_REL_ "GenSigTimeoutTime" BU_SG_REL_ Motor_Otto SG_ 800 KO1_OBD_Tank 500;
BA_REL_ "GenSigTimeoutTime" BU_SG_REL_ Motor_Otto SG_ 800 KO1_Quelle_kmh 500;
BA_REL_ "GenSigTimeoutTime" BU_SG_REL_ LH_EPS_ZF_2G SG_ 800 KO1_kmh 500;
BA_REL_ "GenSigTimeoutTime" BU_SG_REL_ LH_EPS_ZF_3G SG_ 800 KO1_kmh 500;
BA_REL_ "GenSigTimeoutTime" BU_SG_REL_ LWR SG_ 800 KO1_kmh 500;
BA_REL_ "GenSigTimeoutTime" BU_SG_REL_ HCA SG_ 800 KO1_Zaehler 500;
BA_REL_ "GenSigTimeoutTime" BU_SG_REL_ Getriebe_DQ SG_ 800 KO1_angez_kmh 500;
BA_REL_ "GenSigTimeoutTime" BU_SG_REL_ Getriebe_DQ_Hyb SG_ 800 KO1_angez_kmh 500;
BA_REL_ "GenSigTimeoutTime" BU_SG_REL_ HCA SG_ 800 KO1_angez_kmh 500;
BA_REL_ "GenSigTimeoutTime" BU_SG_REL_ Motor_Diesel SG_ 800 KO1_angez_kmh 500;
BA_REL_ "GenSigTimeoutTime" BU_SG_REL_ Motor_Otto SG_ 800 KO1_angez_kmh 500;
BA_REL_ "GenSigTimeoutTime" BU_SG_REL_ RKA_Plus SG_ 800 KO1_angez_kmh 500;
BA_REL_ "GenSigTimeoutTime" BU_SG_REL_ Getriebe_DQ SG_ 800 KO1_kmh_mph 500;
BA_REL_ "GenSigTimeoutTime" BU_SG_REL_ Getriebe_DQ_Hyb SG_ 800 KO1_kmh_mph 500;
BA_REL_ "GenSigTimeoutTime" BU_SG_REL_ Motor_Diesel SG_ 800 KO1_kmh_mph 500;
BA_REL_ "GenSigTimeoutTime" BU_SG_REL_ Motor_Otto SG_ 800 KO1_kmh_mph 500;
BA_REL_ "GenSigTimeoutTime" BU_SG_REL_ Airbag SG_ 800 KO1_Airbag_Lampe 500;
BA_REL_ "GenSigTimeoutTime" BU_SG_REL_ LH_EPS_APA SG_ 800 KO1_Lenkh_Lampe 500;
BA_REL_ "GenSigTimeoutTime" BU_SG_REL_ LH_EPS_ZF_2G SG_ 800 KO1_Lenkh_Lampe 500;
BA_REL_ "GenSigTimeoutTime" BU_SG_REL_ LH_EPS_ZF_3G SG_ 800 KO1_Lenkh_Lampe 500;
BA_REL_ "GenSigTimeoutTime" BU_SG_REL_ HCA SG_ 800 KO1_LDW_AnzFeh 500;
BA_REL_ "GenSigTimeoutTime" BU_SG_REL_ Airbag SG_ 800 KO1_SILA_gueltig 500;
BA_REL_ "GenSigTimeoutTime" BU_SG_REL_ LH_EPS_APA SG_ 800 KO1_SILA_gueltig 500;
BA_REL_ "GenSigTimeoutTime" BU_SG_REL_ LH_EPS_ZF_2G SG_ 800 KO1_SILA_gueltig 500;
BA_REL_ "GenSigTimeoutTime" BU_SG_REL_ LH_EPS_ZF_3G SG_ 800 KO1_SILA_gueltig 500;
BA_REL_ "GenSigTimeoutTime" BU_SG_REL_ Bremse_MK60EC SG_ 1056 KO2_Sta_Auss_T 2000;
BA_REL_ "GenSigTimeoutTime" BU_SG_REL_ Bremse_MK70MABS SG_ 1056 KO2_Sta_Auss_T 2000;
BA_REL_ "GenSigTimeoutTime" BU_SG_REL_ EPB_TRW_VW411CS SG_ 1056 KO2_Sta_Auss_T 2000;
BA_REL_ "GenSigTimeoutTime" BU_SG_REL_ HCA SG_ 1056 KO2_Sta_Auss_T 2000;
BA_REL_ "GenSigTimeoutTime" BU_SG_REL_ Magne_Ride SG_ 1056 KO2_Sta_Auss_T 2000;
BA_REL_ "GenSigTimeoutTime" BU_SG_REL_ Motor_Diesel SG_ 1056 KO2_Sta_Auss_T 2000;
BA_REL_ "GenSigTimeoutTime" BU_SG_REL_ Motor_Hybrid SG_ 1056 KO2_Sta_Auss_T 2000;
BA_REL_ "GenSigTimeoutTime" BU_SG_REL_ Motor_Otto SG_ 1056 KO2_Sta_Auss_T 2000;
BA_REL_ "GenSigTimeoutTime" BU_SG_REL_ RKA_Plus SG_ 1056 KO2_Sta_Auss_T 2000;
BA_REL_ "GenSigTimeoutTime" BU_SG_REL_ Motor_Diesel SG_ 1056 KO2_Verb_TOG 2000;
BA_REL_ "GenSigTimeoutTime" BU_SG_REL_ Motor_Hybrid SG_ 1056 KO2_Verb_TOG 2000;
BA_REL_ "GenSigTimeoutTime" BU_SG_REL_ Motor_Otto SG_ 1056 KO2_Verb_TOG 2000;
BA_REL_ "GenSigTimeoutTime" BU_SG_REL_ Motor_Diesel SG_ 1056 KO2_GRA_High 2000;
BA_REL_ "GenSigTimeoutTime" BU_SG_REL_ Motor_Otto SG_ 1056 KO2_GRA_High 2000;
BA_REL_ "GenSigTimeoutTime" BU_SG_REL_ PDC_PLA SG_ 1056 KO2_PLA_Displaystatus 2000;
BA_REL_ "GenSigTimeoutTime" BU_SG_REL_ AFS SG_ 1056 KO2_gef_Auss_T 2000;
BA_REL_ "GenSigTimeoutTime" BU_SG_REL_ Bremse_MK60EC SG_ 1056 KO2_gef_Auss_T 2000;
BA_REL_ "GenSigTimeoutTime" BU_SG_REL_ Bremse_TRW_EBC450M SG_ 1056 KO2_gef_Auss_T 2000;
BA_REL_ "GenSigTimeoutTime" BU_SG_REL_ Bremse_TRW_EBC450M SG_ 1056 KO2_gef_Auss_T 2000;
BA_REL_ "GenSigTimeoutTime" BU_SG_REL_ Bremse_TRW_ESP SG_ 1056 KO2_gef_Auss_T 2000;
BA_REL_ "GenSigTimeoutTime" BU_SG_REL_ Bremse_TRW_ESP SG_ 1056 KO2_gef_Auss_T 2000;
BA_REL_ "GenSigTimeoutTime" BU_SG_REL_ EPB_TRW_VW411CS SG_ 1056 KO2_gef_Auss_T 2000;
BA_REL_ "GenSigTimeoutTime" BU_SG_REL_ Getriebe_DQ SG_ 1056 KO2_gef_Auss_T 2000;
BA_REL_ "GenSigTimeoutTime" BU_SG_REL_ Getriebe_DQ_Hyb SG_ 1056 KO2_gef_Auss_T 2000;
BA_REL_ "GenSigTimeoutTime" BU_SG_REL_ Getriebe_Sele SG_ 1056 KO2_gef_Auss_T 2000;
BA_REL_ "GenSigTimeoutTime" BU_SG_REL_ HCA SG_ 1056 KO2_gef_Auss_T 2000;
BA_REL_ "GenSigTimeoutTime" BU_SG_REL_ LWR SG_ 1056 KO2_gef_Auss_T 2000;
BA_REL_ "GenSigTimeoutTime" BU_SG_REL_ Magne_Ride SG_ 1056 KO2_gef_Auss_T 2000;
BA_REL_ "GenSigTimeoutTime" BU_SG_REL_ Motor_Hybrid SG_ 1056 KO2_gef_Auss_T 2000;
BA_REL_ "GenSigTimeoutTime" BU_SG_REL_ Motor_Otto SG_ 1056 KO2_gef_Auss_T 2000;
BA_REL_ "GenSigTimeoutTime" BU_SG_REL_ PDC_PLA SG_ 1056 KO2_gef_Auss_T 2000;
BA_REL_ "GenSigTimeoutTime" BU_SG_REL_ RKA_Plus SG_ 1056 KO2_gef_Auss_T 2000;
BA_REL_ "GenSigTimeoutTime" BU_SG_REL_ Bremse_MK60EC SG_ 1056 KO2_Aussen_T 2000;
BA_REL_ "GenSigTimeoutTime" BU_SG_REL_ Bremse_MK70MABS SG_ 1056 KO2_Aussen_T 2000;
BA_REL_ "GenSigTimeoutTime" BU_SG_REL_ Magne_Ride SG_ 1056 KO2_Aussen_T 2000;
BA_REL_ "GenSigTimeoutTime" BU_SG_REL_ Motor_Diesel SG_ 1056 KO2_Aussen_T 2000;
BA_REL_ "GenSigTimeoutTime" BU_SG_REL_ Motor_Otto SG_ 1056 KO2_Aussen_T 2000;
BA_REL_ "GenSigTimeoutTime" BU_SG_REL_ PDC_PLA SG_ 1056 KO2_Aussen_T 2000;
BA_REL_ "GenSigTimeoutTime" BU_SG_REL_ Bremse_TRW_EBC450M SG_ 1056 KBI_rotes_P_verbaut 2000;
BA_REL_ "GenSigTimeoutTime" BU_SG_REL_ EPB_TRW_VW411CS SG_ 1056 KBI_rotes_P_verbaut 2000;
BA_REL_ "GenSigTimeoutTime" BU_SG_REL_ Getriebe_DQ SG_ 1056 KO_Segeln_Menuestatus 2000;
BA_REL_ "GenSigTimeoutTime" BU_SG_REL_ Getriebe_DQ SG_ 1056 KO_Segeln_Zustandswechsel 2000;
BA_REL_ "GenSigTimeoutTime" BU_SG_REL_ Bremse_MK60EC SG_ 1056 KB2_Req_IstZu_Solldruecke 2000;
BA_REL_ "GenSigTimeoutTime" BU_SG_REL_ Bremse_TRW_EBC450M SG_ 1056 KB2_Req_IstZu_Solldruecke 2000;
BA_REL_ "GenSigTimeoutTime" BU_SG_REL_ RKA_Plus SG_ 1056 KB2_Req_IstZu_Solldruecke 2000;
BA_REL_ "GenSigTimeoutTime" BU_SG_REL_ Airbag SG_ 1056 KO2_Bel_Displ 2000;
BA_REL_ "GenSigTimeoutTime" BU_SG_REL_ Daempfer SG_ 1056 KO2_Bel_Displ 2000;
BA_REL_ "GenSigTimeoutTime" BU_SG_REL_ Magne_Ride SG_ 1056 KO2_Bel_Displ 2000;
BA_REL_ "GenSigTimeoutTime" BU_SG_REL_ PDC_PLA SG_ 1056 KO2_Bel_Displ 2000;
BA_REL_ "GenSigTimeoutTime" BU_SG_REL_ Airbag SG_ 1056 KO2_Sta_Displ 2000;
BA_REL_ "GenSigTimeoutTime" BU_SG_REL_ Daempfer SG_ 1056 KO2_Sta_Displ 2000;
BA_REL_ "GenSigTimeoutTime" BU_SG_REL_ Magne_Ride SG_ 1056 KO2_Sta_Displ 2000;
BA_REL_ "GenSigTimeoutTime" BU_SG_REL_ PDC_PLA SG_ 1056 KO2_Sta_Displ 2000;
BA_REL_ "GenSigTimeoutTime" BU_SG_REL_ Motor_Diesel SG_ 1056 KO2_MFA_v_Einheit 2000;
BA_REL_ "GenSigTimeoutTime" BU_SG_REL_ Motor_Hybrid SG_ 1056 KO2_MFA_v_Einheit 2000;
BA_REL_ "GenSigTimeoutTime" BU_SG_REL_ Motor_Otto SG_ 1056 KO2_MFA_v_Einheit 2000;
BA_REL_ "GenSigTimeoutTime" BU_SG_REL_ Motor_Otto SG_ 1056 KO2_MFA_v_Einheit 2000;
BA_REL_ "GenSigTimeoutTime" BU_SG_REL_ Motor_Diesel SG_ 1056 KO2_OBD_Nib_Temp 2000;
BA_REL_ "GenSigTimeoutTime" BU_SG_REL_ Motor_Hybrid SG_ 1056 KO2_OBD_Nib_Temp 2000;
BA_REL_ "GenSigTimeoutTime" BU_SG_REL_ Motor_Otto SG_ 1056 KO2_OBD_Nib_Temp 2000;
BA_REL_ "GenSigTimeoutTime" BU_SG_REL_ Bremse_TRW_EBC450M SG_ 1312 KO3_Sprache 2000;
BA_REL_ "GenSigTimeoutTime" BU_SG_REL_ Bremse_TRW_ESP SG_ 1312 KO3_Sprache 2000;
BA_REL_ "GenSigTimeoutTime" BU_SG_REL_ Allrad SG_ 1312 KO3_Derivat 2000;
BA_REL_ "GenSigTimeoutTime" BU_SG_REL_ Bremse_MK60EC SG_ 1312 KO3_Derivat 2000;
BA_REL_ "GenSigTimeoutTime" BU_SG_REL_ Allrad SG_ 1312 KO3_Radumfang 2000;
BA_REL_ "GenSigTimeoutTime" BU_SG_REL_ Bremse_MK60EC SG_ 1312 KO3_Radumfang 2000;
BA_REL_ "GenSigTimeoutTime" BU_SG_REL_ Bremse_MK70MABS SG_ 1312 KO3_Radumfang 2000;
BA_REL_ "GenSigTimeoutTime" BU_SG_REL_ Bremse_TRW_EBC450M SG_ 1312 KO3_Radumfang 2000;
BA_REL_ "GenSigTimeoutTime" BU_SG_REL_ Bremse_TRW_ESP SG_ 1312 KO3_Radumfang 2000;
BA_REL_ "GenSigTimeoutTime" BU_SG_REL_ Getriebe_DQ SG_ 1312 KO3_Radumfang 2000;
BA_REL_ "GenSigTimeoutTime" BU_SG_REL_ Getriebe_DQ_Hyb SG_ 1312 KO3_Radumfang 2000;
BA_REL_ "GenSigTimeoutTime" BU_SG_REL_ PDC_PLA SG_ 1312 KO3_Radumfang 2000;
BA_REL_ "GenSigTimeoutTime" BU_SG_REL_ Bremse_MK60EC SG_ 1312 KO3_Verbau_Br 2000;
BA_REL_ "GenSigTimeoutTime" BU_SG_REL_ Allrad SG_ 1312 KO3_Generation 2000;
BA_REL_ "GenSigTimeoutTime" BU_SG_REL_ Bremse_MK60EC SG_ 1312 KO3_Generation 2000;
BA_REL_ "GenSigTimeoutTime" BU_SG_REL_ Airbag SG_ 1312 KO3_Verbau_Air 2000;
BA_REL_ "GenSigTimeoutTime" BU_SG_REL_ Allrad SG_ 1312 KO3_Baureihe 2000;
BA_REL_ "GenSigTimeoutTime" BU_SG_REL_ Bremse_MK60EC SG_ 1312 KO3_Baureihe 2000;
BA_REL_ "GenSigTimeoutTime" BU_SG_REL_ Allrad SG_ 1312 KO3_Marke 2000;
BA_REL_ "GenSigTimeoutTime" BU_SG_REL_ Bremse_MK60EC SG_ 1312 KO3_Marke 2000;
BA_REL_ "GenSigTimeoutTime" BU_SG_REL_ Airbag SG_ 1312 KO3_Mp_Code 2000;
BA_REL_ "GenSigTimeoutTime" BU_SG_REL_ Allrad SG_ 1312 KO3_Mp_Code 2000;
BA_REL_ "GenSigTimeoutTime" BU_SG_REL_ Bremse_MK60EC SG_ 1312 KO3_Mp_Code 2000;
BA_REL_ "GenSigTimeoutTime" BU_SG_REL_ Bremse_MK70MABS SG_ 1312 KO3_Mp_Code 2000;
BA_REL_ "GenSigTimeoutTime" BU_SG_REL_ Bremse_TRW_EBC450M SG_ 1312 KO3_Mp_Code 2000;
BA_REL_ "GenSigTimeoutTime" BU_SG_REL_ Bremse_TRW_ESP SG_ 1312 KO3_Mp_Code 2000;
BA_REL_ "GenSigTimeoutTime" BU_SG_REL_ Getriebe_DQ SG_ 1312 KO3_Mp_Code 2000;
BA_REL_ "GenSigTimeoutTime" BU_SG_REL_ Getriebe_DQ_Hyb SG_ 1312 KO3_Mp_Code 2000;
BA_REL_ "GenSigTimeoutTime" BU_SG_REL_ PDC_PLA SG_ 1312 KO3_Mp_Code 2000;
BA_REL_ "GenSigTimeoutTime" BU_SG_REL_ Ladegeraet_EGolf SG_ 1312 KO3_Schluessel 2000;
BA_REL_ "GenSigTimeoutTime" BU_SG_REL_ AFS SG_ 1312 KO3_Um_AFS2 2000;
BA_REL_ "GenSigTimeoutTime" BU_SG_REL_ AFS SG_ 1312 KO3_Um_Tourist 2000;
BA_REL_ "GenSigTimeoutTime" BU_SG_REL_ LWR SG_ 1312 KO3_Um_Tourist 2000;
BA_REL_ "GenSigTimeoutTime" BU_SG_REL_ Bremse_TRW_EBC450M SG_ 1312 KO3_Um_AutoHold 2000;
BA_REL_ "GenSigTimeoutTime" BU_SG_REL_ Bremse_TRW_ESP SG_ 1312 KO3_Um_AutoHold 2000;
BA_REL_ "GenSigTimeoutTime" BU_SG_REL_ AFS SG_ 1312 KO3_Standzeit 2000;
BA_REL_ "GenSigTimeoutTime" BU_SG_REL_ Allrad SG_ 1312 KO3_Standzeit 2000;
BA_REL_ "GenSigTimeoutTime" BU_SG_REL_ Bremse_MK60EC SG_ 1312 KO3_Standzeit 2000;
BA_REL_ "GenSigTimeoutTime" BU_SG_REL_ Bremse_TRW_EBC450M SG_ 1312 KO3_Standzeit 2000;
BA_REL_ "GenSigTimeoutTime" BU_SG_REL_ Bremse_TRW_ESP SG_ 1312 KO3_Standzeit 2000;
BA_REL_ "GenSigTimeoutTime" BU_SG_REL_ Getriebe_DQ SG_ 1312 KO3_Standzeit 2000;
BA_REL_ "GenSigTimeoutTime" BU_SG_REL_ Getriebe_DQ_Hyb SG_ 1312 KO3_Standzeit 2000;
BA_REL_ "GenSigTimeoutTime" BU_SG_REL_ Magne_Ride SG_ 1312 KO3_Standzeit 2000;
BA_REL_ "GenSigTimeoutTime" BU_SG_REL_ Motor_Diesel SG_ 1312 KO3_Standzeit 2000;
BA_REL_ "GenSigTimeoutTime" BU_SG_REL_ Motor_Hybrid SG_ 1312 KO3_Standzeit 2000;
BA_REL_ "GenSigTimeoutTime" BU_SG_REL_ Motor_Otto SG_ 1312 KO3_Standzeit 2000;
BA_REL_ "GenSigTimeoutTime" BU_SG_REL_ AFS SG_ 1312 KO3_Sta_Standz 2000;
BA_REL_ "GenSigTimeoutTime" BU_SG_REL_ Bremse_MK60EC SG_ 1312 KO3_Sta_Standz 2000;
BA_REL_ "GenSigTimeoutTime" BU_SG_REL_ Getriebe_DQ SG_ 1312 KO3_Sta_Standz 2000;
BA_REL_ "GenSigTimeoutTime" BU_SG_REL_ Getriebe_DQ_Hyb SG_ 1312 KO3_Sta_Standz 2000;
BA_REL_ "GenSigTimeoutTime" BU_SG_REL_ Magne_Ride SG_ 1312 KO3_Sta_Standz 2000;
BA_REL_ "GenSigTimeoutTime" BU_SG_REL_ Motor_Diesel SG_ 1312 KO3_Sta_Standz 2000;
BA_REL_ "GenSigTimeoutTime" BU_SG_REL_ Motor_Hybrid SG_ 1312 KO3_Sta_Standz 2000;
BA_REL_ "GenSigTimeoutTime" BU_SG_REL_ Motor_Otto SG_ 1312 KO3_Sta_Standz 2000;
BA_REL_ "GenSigTimeoutTime" BU_SG_REL_ Bremse_MK60EC SG_ 1312 KO3_Kilometer 2000;
BA_REL_ "GenSigTimeoutTime" BU_SG_REL_ Bremse_MK70MABS SG_ 1312 KO3_Kilometer 2000;
BA_REL_ "GenSigTimeoutTime" BU_SG_REL_ Getriebe_AG6 SG_ 1312 KO3_Kilometer 2000;
BA_REL_ "GenSigTimeoutTime" BU_SG_REL_ LH_EPS_ZF_2G SG_ 1312 KO3_Kilometer 2000;
BA_REL_ "GenSigTimeoutTime" BU_SG_REL_ LH_EPS_ZF_3G SG_ 1312 KO3_Kilometer 2000;
BA_REL_ "GenSigTimeoutTime" BU_SG_REL_ Gateway_PQ35 SG_ 1470 LDW_KD_Fehler 500;
BA_REL_ "GenSigTimeoutTime" BU_SG_REL_ Gateway_PQ35 SG_ 976 LH1_Lastinfo 500;
BA_REL_ "GenSigTimeoutTime" BU_SG_REL_ Gateway_PQ35 SG_ 976 LH1_SleepInd 500;
BA_REL_ "GenSigTimeoutTime" BU_SG_REL_ Gateway_PQ35 SG_ 976 LH1_Fehlereintr 500;
BA_REL_ "GenSigTimeoutTime" BU_SG_REL_ Bremse_MK60EC SG_ 978 LH2_Checksumme 500;
BA_REL_ "GenSigTimeoutTime" BU_SG_REL_ Bremse_TRW_EBC450M SG_ 978 LH2_Checksumme 500;
BA_REL_ "GenSigTimeoutTime" BU_SG_REL_ Bremse_TRW_ESP SG_ 978 LH2_Checksumme 500;
BA_REL_ "GenSigTimeoutTime" BU_SG_REL_ HCA SG_ 978 LH2_Checksumme 500;
BA_REL_ "GenSigTimeoutTime" BU_SG_REL_ PDC_PLA SG_ 978 LH2_Checksumme 500;
BA_REL_ "GenSigTimeoutTime" BU_SG_REL_ Bremse_MK60EC SG_ 978 LH2_Zaehler 500;
BA_REL_ "GenSigTimeoutTime" BU_SG_REL_ Bremse_TRW_EBC450M SG_ 978 LH2_Zaehler 500;
BA_REL_ "GenSigTimeoutTime" BU_SG_REL_ Bremse_TRW_ESP SG_ 978 LH2_Zaehler 500;
BA_REL_ "GenSigTimeoutTime" BU_SG_REL_ HCA SG_ 978 LH2_Zaehler 500;
BA_REL_ "GenSigTimeoutTime" BU_SG_REL_ PDC_PLA SG_ 978 LH2_Zaehler 500;
BA_REL_ "GenSigTimeoutTime" BU_SG_REL_ LWS SG_ 978 LH2_Geradeaus 500;
BA_REL_ "GenSigTimeoutTime" BU_SG_REL_ Magne_Ride SG_ 978 LH2_Geradeaus 500;
BA_REL_ "GenSigTimeoutTime" BU_SG_REL_ HCA SG_ 978 LH2_Sta_HCA 500;
BA_REL_ "GenSigTimeoutTime" BU_SG_REL_ Bremse_MK60EC SG_ 978 LH2_StatEPS_PLA 500;
BA_REL_ "GenSigTimeoutTime" BU_SG_REL_ Bremse_TRW_EBC450M SG_ 978 LH2_StatEPS_PLA 500;
BA_REL_ "GenSigTimeoutTime" BU_SG_REL_ Bremse_TRW_ESP SG_ 978 LH2_StatEPS_PLA 500;
BA_REL_ "GenSigTimeoutTime" BU_SG_REL_ PDC_PLA SG_ 978 LH2_StatEPS_PLA 500;
BA_REL_ "GenSigTimeoutTime" BU_SG_REL_ PDC_PLA SG_ 978 LH2_aktLenkeingriff 500;
BA_REL_ "GenSigTimeoutTime" BU_SG_REL_ PDC_PLA SG_ 978 LH2_PLA_Err 500;
BA_REL_ "GenSigTimeoutTime" BU_SG_REL_ PDC_PLA SG_ 978 LH2_PLA_Abbr 500;
VAL_ 1100 GE6_TurbDZ 16382 "Init" 16383 "Fehler" ;
VAL_ 1100 GE6_QmaxBeschl 0 "gueltiger_Wert" 1 "Ersatz_Init_oder_Fehlerwert" ;
VAL_ 1100 GE6_QB_OelTemp 0 "gueltiger_Wert" 1 "Ersatz_Init_oder_Fehlerwert" ;
VAL_ 1100 GE6_OelTemp 255 "Fehler" ;
VAL_ 1100 GE6_maxBeschl 255 "Fehler" ;
VAL_ 1100 GE6_Gangwechsel 0 "kein_Gangwechsel" 1 "Gangwechsel" ;
VAL_ 1100 GE6_Zielgang_err 0 "Zielgang_nicht_erreicht" 1 "Zielgang_erreicht" ;
VAL_ 1100 GE_Heizwunsch 0 "maximaler_Waermebedarf" 1 "kein_Waermebedarf" 2 "Kuehlbedarf" 3 "Notfall_(maximaler_Kuehlbedarf)" ;
VAL_ 1100 GE1_StSt_Info 0 "Motorlauf_nicht_notwendig_(Stoppfreigabe)" 1 "Motoranlauf_nicht_zwingend_notwendig_(Stoppverbot,keine_Startanforderung)" 2 "Motoranlauf_zwingend_notwendig_(Startanforderung)" 3 "Systemfehler" ;
VAL_ 1100 GE6_Verlustmom 255 "Fehler" ;
VAL_ 1348 GE7_Text_01 0 "Text_aus" 1 "Text_ein" ;
VAL_ 1348 GE7_Text_02 0 "Text_aus" 1 "Text_ein" ;
VAL_ 1348 GE7_Text_03 0 "Text_aus" 1 "Text_ein" ;
VAL_ 1348 GE7_Gong 0 "kein_Gong" 1 "Gong_aktiv" ;
VAL_ 1348 GE7_Text_04 0 "Text_aus" 1 "Text_ein" ;
VAL_ 1348 GE7_Text_05 0 "Text_aus" 1 "Text_ein" ;
VAL_ 1348 GE7_Waehlh_ausgef 0 "Waehlhebel_OK" 1 "Waehlhebel_ausgef" ;
VAL_ 1348 GE7_Text_07 0 "Text_aus" 1 "Text_ein" ;
VAL_ 1348 GE_Segeln_Menueanf 0 "Segeln_nicht_vorhanden" 1 "Segeln_vorhanden" ;
VAL_ 1348 GE_Segeln_Status 0 "Personalisierung_Segeln_aus" 1 "Personalisierung_Segeln_ein" ;
VAL_ 1104 GE8_Hydr_Pumpe 0 "Hydraulikpumpe_aus" 1 "Hydraulikpumpe_angest" ;
VAL_ 1104 GE8_Motor_aus 0 "Motor_startbereit" 1 "Motor_aus" ;
VAL_ 1104 GE8_Anfahrfkt 0 "Anfahrfunktion_nicht_aktiv" 1 "Anfahrfunktion_aktiv" ;
VAL_ 1106 GH1_FreigabeK0 0 "K0_oeffnen" 1 "K0_schliessen" ;
VAL_ 1106 GH1_FreigabeVMStop 0 "VM_Stopp_nicht_erlaubt" 1 "VM_Stopp_erlaubt" ;
VAL_ 1106 GH1_FehlerstatusGSG 0 "kein_Fehler" 1 "kein_Hydraulikdruck" 2 "Anforderung_n_gleich_0" 3 "beide_Fehler" ;
VAL_ 1106 GH1_nK0 255 "Fehler" ;
VAL_ 1106 GH1_VZMomEingriff 0 "positives_Vorzeichen" 1 "negatives_Vorzeichen" ;
VAL_ 1106 GH1_Wiederstart 0 "kein_Wiederstart_aktiv" 1 "Wiederstart_aktiv" ;
VAL_ 1106 GH1_VM_akt_halten 0 "keine_Empfehlung" 1 "VM_aktiv_halten_starten" ;
VAL_ 1106 GH1_Sportfaktor 0 "nicht_sportlich" ;
VAL_ 1106 GH1_Freig_LL_Reg 0 "keine_DZ_Reg_erlaubt" 1 "LL_Reg_freigegeben" ;
VAL_ 1106 GH1_VKM_StAnf 0 "keine_Startanf" 1 "Startanf" ;
VAL_ 1106 GH1_VKM_StKontr 0 "nicht_aktiv" 1 "aktiv" ;
VAL_ 1106 GH1_AnzeigeDZ 4095 "Fehler" ;
VAL_ 1106 GH1_Filt_MomAufbau 0 "keine_Beeinflussung_der_Filterung_durch_Getriebe" 1 "multiplikative_Konstante_fuer_MSG" 2 "multiplikative_Konstante_fuer_MSG" 3 "multiplikative_Konstante_fuer_MSG" 4 "multiplikative_Konstante_fuer_MSG" 5 "multiplikative_Konstante_fuer_MSG" 6 "multiplikative_Konstante_fuer_MSG" 7 "multiplikative_Konstante_fuer_MSG" ;
VAL_ 1106 GE_Freigabe_Verfallsinfo_WFS 0 "Aus" 1 "Ein" ;
VAL_ 906 GRA_Hauptschalt 0 "Gerastet_AUS" 1 "EIN_Nicht_Gerastet_AUS" ;
VAL_ 906 GRA_Abbrechen 0 "Tipschalter_nicht_betaetigt" 1 "Tipschalter_betaetigt" ;
VAL_ 906 GRA_Down_kurz 0 "Tipschalter_nicht_betaetigt" 1 "Tipschalter_betaetigt" ;
VAL_ 906 GRA_Up_kurz 0 "Tipschalter_nicht_betaetigt" 1 "Tipschalter_betaetigt" ;
VAL_ 906 GRA_Down_lang 0 "Tipschalter_nicht_betaetigt" 1 "Tipschalter_lang_betaetigt" ;
VAL_ 906 GRA_Up_lang 0 "Tipschalter_nicht_betaetigt" 1 "Tipschalter_lang_betaetigt" ;
VAL_ 906 GRA_Fehler_Bed 0 "iO" 1 "Fehler_Bedienhebel" ;
VAL_ 906 GRA_Kodierinfo 0 "GRA" 1 "ACC" ;
VAL_ 906 GRA_Neu_Setzen 0 "Tipschalter_nicht_betaetigt" 1 "Tipschalter_betaetigt" ;
VAL_ 906 GRA_Recall 0 "Tipschalter_nicht_betaetigt" 1 "Tipschalter_betaetigt" ;
VAL_ 906 GRA_Sender 0 "BSG_oder_BCM" 1 "Lenksaeulenmodul_6_Pos" 2 "nicht_belegt" 3 "Lenksaeulenmodul_4_Pos" ;
VAL_ 906 GRA_Tip_Down 0 "Tipschalter_nicht_betaetigt" 1 "Tip_Down" ;
VAL_ 906 GRA_Tip_Up 0 "Tipschalter_nicht_betaetigt" 1 "Tip_Up" ;
VAL_ 906 GRA_Zeitluecke 0 "Taste_nicht_betaetigt" 1 "DIST_minus_1" 2 "DIST_plus_1" 3 "nicht_belegt" ;
VAL_ 906 GRA_Sta_Limiter 0 "Limiter_aus" 1 "Limiter_ein" ;
VAL_ 906 GRA_Typ_Hauptschalt 0 "gerastet" 1 "getastet" ;
VAL_ 906 GRA_Sportschalter 0 "Aus" 1 "Ein" ;
VAL_ 906 GRA_Fehler_Tip 0 "iO" 1 "Fehler_erkannt" ;
VAL_ 1510 Weckzeit_EV_erreicht 0 "inaktiv" 1 "aktiv" ;
VAL_ 1510 Standklimatisierung_Anf 0 "keine_Anforderung" 1 "Anforderung_starten" 2 "Anforderung_stoppen" ;
VAL_ 1510 Ladevorgang_Anf 0 "keine_Anforderung" 1 "Anforderung_starten" 2 "Anforderung_stoppen" ;
VAL_ 1510 GSM_Wake_Up_ACAN 0 "kein_Wecken_ACAN" 1 "Wecken_ACAN" ;
VAL_ 1510 Standklima_Temp_Vorwahl 11 "Low" 12 "High" 13 "keine_Vorgabe" 14 "reserviert" 15 "reserviert" ;
VAL_ 1510 Ladestrom_max 0 "5A" 1 "10A" 2 "16A" 3 "reserviert" ;
VAL_ 1510 GSM_Zeit_Typ 0 "aktuelle_Uhrzeit_GSM" 1 "Abfahrtzeitpunkt" 2 "Ladeendzeitpunkt" 3 "Weckzeitpunkt_EV_Antrieb" 4 "NT_Zeit_Start" 5 "NT_Zeit_Ende" 6 "reserviert" 7 "reserviert" ;
VAL_ 1510 GSM_Monat 0 "ungueltig" 13 "ungueltig" 14 "relatives_Datum" 15 "Spezialfall" ;
VAL_ 1510 GSM_Stunde 24 "ungueltig" 25 "ungueltig" 26 "ungueltig" 27 "ungueltig" 28 "ungueltig" 29 "ungueltig" 30 "ungueltig" 31 "ungueltig" ;
VAL_ 1510 GSM_Minute 60 "ungueltig" 61 "ungueltig" 62 "ungueltig" 63 "ungueltig" ;
VAL_ 1510 GSM_Ladestecker_Anf 0 "keine_Anf" 1 "verriegeln_Anf" 2 "entriegeln_Anf" 3 "reserviert" ;
VAL_ 1529 GM_KD_Fehler 0 "kein_Fehlerspeichereintrag" 1 "Fehlerspeichereintrag" ;
VAL_ 1164 HS1_Drehz_Grenze 0 "kein_Grenzwert" 1 "untere_Abschaltgrenze" 2 "untere_Komfortgrenze" 3 "Obere_Abschaltgrenze" 4 "Obere_Komfortgrenze" ;
VAL_ 1164 HS1_Gang 0 "Triebstrang_offen" 1 "Gang_1" 2 "Hoechster_Gang" 3 "Rueckwaertsgang" 7 "nicht_bekannt" ;
VAL_ 210 HC1_Sta_HCA 0 "deaktiv" 1 "Anf_nicht_ausf" 2 "Kom_gestoert" 3 "bereit" 5 "ext_MomEingr_angef" ;
VAL_ 210 HC1_LM_Offset_Sign 0 "positives_Vorzeichen" 1 "negatives_Vorzeichen" ;
VAL_ 1512 KL_HV_ein 0 "Aus" 1 "Ein" ;
VAL_ 1512 KL_Innengeblaese 0 "Aus" 1 "Ein" ;
VAL_ 1512 KL_Wake_Up_ACAN 0 "kein_Wecken_ACAN" 1 "Wecken_ACAN" ;
VAL_ 1512 KL_HV_Anf 0 "kein_HV_Bordnetz_benoetigt" 1 "HV_Bordnetz_benoetigt" ;
VAL_ 1512 KL_Ventil_Batterie_Anf 0 "Ventil_oeffnen" 1 "Ventil_schliessen" ;
VAL_ 1512 KL_Ventil_vor_Motor_Anf 0 "Ventil_oeffnen" 1 "Ventil_schliessen" ;
VAL_ 1512 EKK_Status 0 "inaktiv" 1 "aktiv" ;
VAL_ 1512 KL_Standklima_Status 0 "aus" 1 "ein" 2 "nicht_moeglich__Aussenhuelle_nicht_geschlossen" 3 "abgebrochen__Aussenhuelle_geoeffnet" 4 "nicht_moeglich__HV_nicht_aktiv" 5 "abgebrochen__HV_deaktiviert" 6 "nicht_moeglich__Batt_hat_Prio" 7 "on_hold_Freigabe_HV_Komponenten_fehlt" ;
VAL_ 1512 PTC_Pumpe_Ist 11 "nicht_definiert" 12 "nicht_definiert" 13 "nicht_definiert" 14 "nicht_definiert" 15 "nicht_verbaut" ;
VAL_ 1512 PTC_Pumpe_Status 0 "nicht_schaltbar" 1 "foerdert_nicht" 2 "foerdert" 3 "reserviert" ;
VAL_ 1512 KL_Charisma_FahrPr 0 "nicht_belegt" 1 "Programm_1" 2 "Programm_2" 3 "Programm_3" 4 "Programm_4" 5 "Programm_5" 6 "Programm_6" 7 "Programm_7" ;
VAL_ 1512 KL_Charisma_Status 0 "Init" 1 "verfuegbar" 2 "nicht_verfuegbar" 3 "asynchron_durch_Fahrerwunsch" ;
VAL_ 1512 EKK_Status_Vorstrg 0 "Aus" 1 "Ein" ;
VAL_ 1512 KL_Standklima_Strg_Kluefter 255 "Fehler" ;
VAL_ 1527 KE1_Comp_enable 0 "Disable" 1 "Enable" ;
VAL_ 800 KO1_SleepInd 0 "CAN_wird_benoetigt" 1 "Sleep_bereit" ;
VAL_ 800 KO1_Sta_Tank 0 "Tankfuellst_iO" 1 "Tankfuellst_n_iO" ;
VAL_ 800 KO1_Oeldruck 0 "kleiner_Schwellwert" 1 "groesser_Schwellwert" ;
VAL_ 800 KO1_Sta_Oeldr 0 "iO" 1 "Warnung" ;
VAL_ 800 KO1_Kuehlmittel 0 "iO" 1 "Mangel" ;
VAL_ 800 KO1_Wakeup_Komfort 0 "keine_Anforderung" 1 "Wake_Up_Komfort" ;
VAL_ 800 KO1_Warn_Tank 0 "Lampe_aus" 1 "Lampe_ein" ;
VAL_ 800 KO1_Vorgluehen 0 "Lampe_aus" 1 "Lampe_ein" ;
VAL_ 800 KO1_Bremsinfo 0 "iO" 1 "Bremsfluessigkeitswarnung" ;
VAL_ 800 KO1_Handbremse 0 "nicht_angezogen" 1 "angezogen" ;
VAL_ 800 KO1_La_Ladekon 0 "Lampe_aus" 1 "Lampe_ein" ;
VAL_ 800 KO1_Stellglieder 0 "nein" 1 "ja" ;
VAL_ 800 KO1_Zeitluecke 0 "keine_Anzeige" 1 "Zeitluecke_1" 2 "Zeitluecke_2" 3 "Zeitluecke_3" 4 "Zeitluecke_4" 5 "Zeitluecke_5" 6 "Zeitluecke_6" 7 "Zeitluecke_7" ;
VAL_ 800 KO1_Tankstop 1 "Tankstop_erkannt" ;
VAL_ 800 KO1_Tankinhalt 127 "Fehler" ;
VAL_ 800 KO1_OBD_Tank 0 "iO" 1 "Tankwarnung" ;
VAL_ 800 KO1_Quelle_kmh 0 "Tachogeber" 1 "ABS_Signale" ;
VAL_ 800 KO1_ACC_Inkons 0 "iO" 1 "Fehler" ;
VAL_ 800 KO1_ACC_AnzFhl 0 "kein_Fehler" 1 "ACC_Anzeige_defekt" ;
VAL_ 800 KO1_angez_kmh 1020 "Fehler" 1021 "Fehler" 1022 "Fehler" 1023 "Fehler" ;
VAL_ 800 KO1_kmh_mph 0 "km_h" 1 "miles_hour" ;
VAL_ 800 KO1_ABS_Lampe 0 "Lampe_aus" 1 "Lampe_ein" ;
VAL_ 800 KO1_ASRESP_Lampe 0 "Lampe_aus" 1 "Lampe_ein" ;
VAL_ 800 KO1_Brems_Lampe 0 "Lampe_aus" 1 "Lampe_ein" ;
VAL_ 800 KO1_Airbag_Lampe 0 "Lampe_aus" 1 "Lampe_ein" ;
VAL_ 800 KO1_Lenkh_Lampe 0 "Lampe_aus" 1 "Lampe_ein" ;
VAL_ 800 KO1_LDW_AnzFeh 0 "i_O" 1 "Fehler" ;
VAL_ 800 KO1_SILA_gueltig 0 "ungueltig" 1 "gueltig" ;
VAL_ 1056 KO2_Sta_Auss_T 0 "iO" 1 "n_iO" ;
VAL_ 1056 KO2_Verb_TOG 0 "TOG_verbaut" 1 "TOG_nicht_verbaut" ;
VAL_ 1056 KO2_Oelwarn 0 "Schwelle_nicht_ueberschritten" 1 "Schwelle_ueberschritten" ;
VAL_ 1056 KO2_GRA_High 0 "nein" 1 "ja" ;
VAL_ 1056 KO2_Temp_Einheit 0 "Celsius" 1 "Fahrenheit" ;
VAL_ 1056 KO2_Wischwasser 0 "keine_Warnung" 1 "Wischwasserwarnung_aktiv" ;
VAL_ 1056 KO2_PLA_Displaystatus 0 "nicht_dargestellt" 1 "dargestellt" ;
VAL_ 1056 KO2_Fehlereintr 0 "kein_Fehlerspeichereintrag" 1 "Fehlerspeichereintrag" ;
VAL_ 1056 KO2_gef_Auss_T 255 "Fehler" ;
VAL_ 1056 KO2_Aussen_T 255 "Fehler" ;
VAL_ 1056 KB2_EasyEntry 0 "inaktiv" 1 "aktiv" ;
VAL_ 1056 KBI_rotes_P_verbaut 0 "nicht_verbaut" 1 "verbaut" ;
VAL_ 1056 KO_Segeln_Menuestatus 0 "kein_Menue" 1 "Menue_verfuegbar" ;
VAL_ 1056 KO_Segeln_Zustandswechsel 0 "kein_Zustandswechsel" 1 "Zustandswechsel_gewuenscht" ;
VAL_ 1056 KB2_Auto_eKiSi 0 "inaktiv" 1 "aktiv" ;
VAL_ 1056 KB2_Req_IstZu_Solldruecke 0 "keine_Anforderung" 1 "Anforderung_Soll_gleich_Istdruck" ;
VAL_ 1056 KO2_Bel_Displ 127 "kein_Ersatzwert" ;
VAL_ 1056 KO2_Sta_Displ 0 "Kl_58d_iO" 1 "Kl_58d_n_iO" ;
VAL_ 1056 KO2_Bel_Schalt 127 "kein_Ersatzwert" ;
VAL_ 1056 KO2_Sta_Schalt 0 "Kl_58s_iO" 1 "Kl_58s_n_iO" ;
VAL_ 1056 KO2_MFA_v_Einheit 0 "kmh" 1 "mph" ;
VAL_ 1056 KO2_Passiv_Autolock 0 "inaktiv" 1 "aktiv" ;
VAL_ 1056 KO2_WFS_Schl_Ort 0 "keyless" 1 "Lesespule" ;
VAL_ 1056 KB2_MFA_Strecke_Einheit 0 "km" 1 "miles" ;
VAL_ 1056 KO2_OBD_Nib_Temp 0 "kein_Fehler" 1 "KS_M" 2 "KS_P" 3 "OC" 4 "OOR_P" 5 "OOR_M" 6 "RC_P" 7 "RC_M" 8 "KS_P_OC" 9 "KS_M_OC" 10 "KS_MP" 11 "KS_MP_OC" 12 "frei" 13 "frei" 14 "frei" 15 "frei" ;
VAL_ 1312 KO3_Sprache 0 "keine_Sprachvar" 1 "Deutsch" 2 "Englisch" 3 "Franzoesisch" 4 "Italienisch" 5 "Spanisch" 6 "Portugiesisch" 8 "Tschechisch" 9 "Chinesisch" 10 "US_Englisch" 11 "Niederlaendisch" 12 "Japanisch" 13 "Russisch" 14 "Koreanisch" 15 "Franko_Kanadisch" 16 "Schwedisch" 17 "Polnisch" 18 "Tuerkisch" 19 "US_Spanisch" 20 "Norwegisch" ;
VAL_ 1312 KO3_Derivat 0 "Kurzheck_Multivan" 1 "Stufenheck_Nutz" 2 "Variant" 3 "Fliessheck" 4 "Coupe_Sportwagen" 5 "Cabrio_Roadster_Spider" 6 "Offroad" 7 "City_Van_Pickup" 8 "MPV" 9 "Sonstige" ;
VAL_ 1312 KO3_Verbau_Mot 0 "ohne_CAN" 1 "mit_CAN" ;
VAL_ 1312 KO3_Verbau_Get 0 "ohne_CAN" 1 "mit_CAN" ;
VAL_ 1312 KO3_Verbau_Br 0 "ohne_CAN" 1 "mit_CAN" ;
VAL_ 1312 KO3_Verbau_Kl 0 "ohne_CAN" 1 "mit_CAN" ;
VAL_ 1312 KO3_Verbau_Air 0 "ohne_CAN" 1 "mit_CAN" ;
VAL_ 1312 KO3_Verbau_ADR 0 "ohne_CAN" 1 "mit_CAN" ;
VAL_ 1312 KO3_Verbau_BN 0 "ohne_CAN" 1 "mit_CAN" ;
VAL_ 1312 KO3_Verbau_Syn 0 "ohne_CAN" 1 "mit_CAN" ;
VAL_ 1312 KO3_Land 0 "Deutschland" 1 "Europa" 2 "USA" 3 "Kanada" 4 "Grossbritannien" 5 "Japan" 6 "Saudi_Arabien" 7 "Australien" ;
VAL_ 1312 KO3_Baureihe 0 "LT_Klasse" 1 "A00_Klasse" 2 "A0_Klasse" 3 "A_Klasse" 4 "B_Klasse" 5 "C_Klasse" 6 "D_Klasse" 7 "T_Klasse" ;
VAL_ 1312 KO3_Verbau_LWS 0 "ohne_CAN" 1 "mit_CAN" ;
VAL_ 1312 KO3_Verbau_DP 0 "ohne_CAN" 1 "mit_CAN" ;
VAL_ 1312 KO3_Verbau_LH 0 "ohne_CAN" 1 "mit_CAN" ;
VAL_ 1312 KO3_Marke 0 "VW" 1 "Audi" 2 "Seat" 3 "Skoda" 4 "VW_Nutzf" 5 "Bugatti_Lamborghini" 6 "Bentley_RollsRoyce" 7 "Ford_Porsche" ;
VAL_ 1312 KO3_Verbau_Niveau 0 "ohne_CAN" 1 "mit_CAN" ;
VAL_ 1312 KO3_Mp_Code 0 "Land_Sprache" 1 "Plattform" 2 "Radumfang" 3 "Verbauliste" ;
VAL_ 1312 KO3_Schluessel 0 "ungueltig" ;
VAL_ 1312 KO3_Um_AFS2 0 "Taster_nicht_gedrueckt" 1 "Taster_gedrueckt" ;
VAL_ 1312 KO3_Um_Tourist 0 "Taster_nicht_gedrueckt" 1 "Taster_gedrueckt" ;
VAL_ 1312 KO3_Um_AutoHold 0 "Taster_nicht_gedrueckt" 1 "Taster_gedrueckt" ;
VAL_ 1312 KO3_SWA_AnzFeh 0 "iO" 1 "Fehler" ;
VAL_ 1312 KO3_Sta_Standz 0 "Standzeit_iO" 1 "Kl_30_war_weg" ;
VAL_ 1564 Restladezeit_HV_Batterie 127 "Restladezeit_nicht_verfuegbar" ;
VAL_ 1564 Lademodus_HV_Batterie 0 "Sofortlademodus" 1 "zeitversetztes_Laden" ;
VAL_ 1564 LM_EKlKomLeiRed 0 "keine_LeistBegr" 1 "LeistBegr_75" 2 "LeistBegr_50" 3 "LeistBegr_25" ;
VAL_ 1564 LM_HV_PTC_aus 0 "inaktiv" 1 "aktiv" ;
VAL_ 1564 LM_HV_PTC_LeistRed 0 "keine_LeistBegr" 1 "LeistBegr_75" 2 "LeistBegr_50" 3 "LeistBegr_25" ;
VAL_ 1564 LM_KlimaKompr 0 "keine_Anforderung" 1 "Klimakompr_aus" ;
VAL_ 1564 LM_Bat_heiz_aktiv 0 "inaktiv" 1 "aktiv" ;
VAL_ 1564 LM_Bat_kuehl_aktiv 0 "inaktiv" 1 "aktiv" ;
VAL_ 1564 LM_Bat_laden_aktiv 0 "inaktiv" 1 "aktiv" ;
VAL_ 1564 LM_Wake_Up_KCAN 0 "kein_Wecken_KCAN" 1 "Wecken_KCAN" ;
VAL_ 1564 LM_Standkl_heiz_aktiv 0 "inaktiv" 1 "aktiv" ;
VAL_ 1564 LM_Standkl_kuehl_aktiv 0 "inaktiv" 1 "aktiv" ;
VAL_ 1564 LM_MaxLadLeistung_HV 511 "Init" ;
VAL_ 1470 LDW_Lernmodus_seitenabhaengig 0 "links_aus__rechts_aus" 1 "nicht_definiert" 2 "nicht_definiert" 3 "nicht_definiert" 4 "nicht_definiert" 5 "links_outlined__rechts_outlined" 6 "links_outlined__rechts_an" 7 "links_outlined__rechts_Warnung" 8 "nicht_definiert" 9 "links_an__rechts_outlined" 10 "links_an__rechts_an" 11 "links_an__rechts_Warnung" 12 "nicht_definiert" 13 "links_Warnung__rechts_outlined" 14 "links_Warnung__rechts_an" 15 "links_Warnung__rechts_Warnung" ;
VAL_ 1470 LDW_Lernmodus 0 "LDW_aus" 1 "LDW_an_inakt" 2 "LDW_an_aktiv" 3 "LDW_warn_re" 4 "LDW_Warn_li" ;
VAL_ 1470 LDW_Textbits 0 "kein_Text" 1 "Lane assist zur Zeit nicht verfügbar" 2 "Lane assist Systemfehler" 3 "Lane assist zur Zeit keine Sensorsicht" 4 "Lane assist Fahreruebernahme" 5 "Lane assist keine Funktion bei Anhaengerbetrieb (Vorhalt)" ;
VAL_ 1470 LDW_Gong 0 "kein_akust_Signal" 1 "Gong1" 2 "Gong2" ;
VAL_ 1470 LDW_Lampe_gelb 0 "Lampe_aus" 1 "Lampe_ein" ;
VAL_ 1470 LDW_Lampe_gruen 0 "Lampe_aus" 1 "Lampe_ein" ;
VAL_ 1470 LDW_SW_Warnung_links 0 "Spurwechsel_Warnung_links_nicht_aktiv" 1 "Spurwechsel_Warnung_links_aktiv" ;
VAL_ 1470 LDW_SW_Warnung_rechts 0 "Spurwechsel_Warnung_rechts_nicht_aktiv" 1 "Spurwechsel_Warnung_rechts_aktiv" ;
VAL_ 1470 LDW_KD_Fehler 0 "kein_Fehlerspeichereintrag" 1 "Fehlerspeichereintrag" ;
VAL_ 1470 LDW_Seite_DLCTLC 0 "links" 1 "rechts" ;
VAL_ 1470 LDW_Frueh_Spaet 0 "frueh_frueh_aktiv" 1 "frueh_spaet_aktiv" 2 "spaet_spaet_aktiv" 3 "Fehler" ;
VAL_ 976 LH1_Fehler_LI 0 "iO" 1 "n_iO" ;
VAL_ 976 LH1_Sicherheitslamp 0 "Lampe_aus" 1 "Lampe_ein" ;
VAL_ 976 LH1_Fehlerlampe 0 "Lampe_aus" 1 "Lampe_ein" ;
VAL_ 976 LH1_Textbits 0 "kein_Text" 1 "Text_1" 2 "Text_2" 4 "Text_3" ;
VAL_ 976 LH1_Akustiksign 0 "Akustiksignal_nicht_aktiv" 1 "Akustiksignal_aktiv" ;
VAL_ 976 LH1_SleepInd 0 "CAN_wird_benoetigt" 1 "Sleep_bereit" ;
VAL_ 976 LH1_Fehlereintr 0 "kein_Fehlerspeichereintrag" 1 "Fehlerspeichereintrag" ;
VAL_ 976 LH1_EPS_Diagmode 0 "nicht_aktiv" 1 "aktiv" ;
VAL_ 976 LH1_gue_ECU_Temp 0 "ungueltig" 1 "gueltig" ;
VAL_ 976 LH1_Kuehlung 0 "keine_Anforderung" 1 "Anf_Kuehlung" ;
VAL_ 976 LH1_Mode_Hybrid 0 "Mode_Hybrid_nicht_aktiv" 1 "Mode_Hybrid_aktiv" ;
VAL_ 976 LH1_NL_Untersp 1 "Unterspannung" ;
VAL_ 976 LH1_NL_Uebersp 1 "Ueberspannung" ;
VAL_ 976 LH1_NL_Uebertemp 1 "Uebertemperatur" ;
VAL_ 976 LH1_NL_Sensor 1 "Sensorik_Fehler" ;
VAL_ 976 LH1_NL_CAN_SS 1 "CAN_Schnittstelle_Fehler" ;
VAL_ 976 LH1_NL_ECU 1 "ECU_intern_defekt" ;
VAL_ 976 LH1_NL_Motor 1 "Servomotordefekt" ;
VAL_ 976 LH1_NL_LeistDichte 1 "Leistungsdichtebegrenzung" ;
VAL_ 978 LH2_Geradeaus 0 "Keine_Geradeausfahrt" 1 "Geradeausfahrt" ;
VAL_ 978 LH2_Sta_Charisma 0 "deaktiv" 1 "Komfort" 2 "Normal" 3 "Sport" ;
VAL_ 978 LH2_Sta_HCA 0 "deaktiv" 1 "Anf_nicht_ausf_kein_FSP" 2 "Anf_nicht_ausf_mit_FSP" 3 "bereit" 4 "Anf_abgewiesen" 5 "Eingriff_aktiv_mit_Act_Ret" 7 "Eingriff_aktiv_ohne_Act_Ret" ;
VAL_ 978 LH2_Ausg_LW1 0 "nicht_aktiv" 1 "aktiviert" ;
VAL_ 978 LH2_Ausg_LW1_gue 0 "ungueltig" 1 "gueltig" ;
VAL_ 978 LH2_aktLenkeingriff 0 "Init" 1 "kein_Eingriff" 2 "DSR" 8 "HCA" 32 "Torque_Steer" 64 "PLA" ;
